VERSION "dbc-export 1 2026.26.6.5"

NS_ :

BS_:

BU_: ADSP APB APP APS APSB BB BMS CC CMP CMPD CP DAS DI DIF DIR DPB EPAS3P EPAS3S EPASTP EPASTS EPBL EPBR ESP EVSE FC GTW HCML HCMR HVP IBST ICR IDB LS OCS1P PARK PCS PCS2 PM PMF PMR PNCD PTC RADC RCM RCM2 RCM3 RCU SCCM SCM SCS SDCR TAS TCU TCU2 TPMS TRCM UI UIS UMC USM V2G VC VCBATT VCBATT0 VCBATT1 VCBATT2 VCCC VCFRONT VCFRONT1 VCFRONT2 VCLEFT VCRIGHT VCSEAT2L VCSEAT2R VCSEC VEH

BO_ 1513 APP_alertLog: 8 APP
 SG_ APP_alertID M : 0|14@1+ (1,0) [0|16383] "" Vector__XXX
 SG_ APP_sw285_exitTransportMode m285 : 24|1@1+ (1,0) [0|1] "" Vector__XXX
 SG_ APP_sw285_satRejectionTimeout m285 : 25|1@1+ (1,0) [0|1] "" Vector__XXX
 SG_ APP_sw285_gpsPPSMissing m285 : 26|1@1+ (1,0) [0|1] "" Vector__XXX
 SG_ APP_sw286_cfgBufNull m286 : 16|1@1+ (1,0) [0|1] "" Vector__XXX
 SG_ APP_sw286_invalidID m286 : 17|1@1+ (1,0) [0|1] "" Vector__XXX
 SG_ APP_sw286_gpsBufferOverflow m286 : 18|1@1+ (1,0) [0|1] "" Vector__XXX
 SG_ APP_sw286_navx5CfgFailed m286 : 19|1@1+ (1,0) [0|1] "" Vector__XXX
 SG_ APP_sw286_mcuNMEAmsgUDPinvalid m286 : 20|1@1+ (1,0) [0|1] "" Vector__XXX
 SG_ APP_sw286_mcuDbgMsgInvalid m286 : 21|1@1+ (1,0) [0|1] "" Vector__XXX
 SG_ APP_sw286_mcuDbgMsgTooBig m286 : 22|1@1+ (1,0) [0|1] "" Vector__XXX
 SG_ APP_sw286_mcuFwdNMEAfail m286 : 23|1@1+ (1,0) [0|1] "" Vector__XXX
 SG_ APP_sw286_NMEAinvalidChecksum m286 : 24|1@1+ (1,0) [0|1] "" Vector__XXX
 SG_ APP_sw286_unexpectedNMEAmsg m286 : 25|1@1+ (1,0) [0|1] "" Vector__XXX
 SG_ APP_sw286_UARTbusFull m286 : 26|1@1+ (1,0) [0|1] "" Vector__XXX
 SG_ APP_sw286_UARTframeError m286 : 27|1@1+ (1,0) [0|1] "" Vector__XXX
 SG_ APP_sw286_UBXrxFrameTooBig m286 : 28|1@1+ (1,0) [0|1] "" Vector__XXX
 SG_ APP_sw286_emptyValidNMEA m286 : 29|1@1+ (1,0) [0|1] "" Vector__XXX
 SG_ APP_sw286_invalidAsciiNMEA m286 : 30|1@1+ (1,0) [0|1] "" Vector__XXX
 SG_ APP_sw286_wheeltickUARTfault m286 : 31|1@1+ (1,0) [0|1] "" Vector__XXX
 SG_ APP_sw286_baudrateMismatch m286 : 32|1@1+ (1,0) [0|1] "" Vector__XXX
 SG_ APP_sw286_wheelTickInvalidSrc m286 : 33|1@1+ (1,0) [0|1] "" Vector__XXX
 SG_ APP_sw286_UARTparityError m286 : 34|1@1+ (1,0) [0|1] "" Vector__XXX
 SG_ APP_sw286_UARTrxFifoOverflow m286 : 35|1@1+ (1,0) [0|1] "" Vector__XXX
 SG_ APP_sw286_UARTrxFifoUnderflow m286 : 36|1@1+ (1,0) [0|1] "" Vector__XXX
 SG_ APP_sw286_UARTtxFifoOverflow m286 : 37|1@1+ (1,0) [0|1] "" Vector__XXX
 SG_ APP_sw286_esfWtMsgTimeout m286 : 38|1@1+ (1,0) [0|1] "" Vector__XXX
 SG_ APP_sw286_PFLASHReadError m286 : 39|1@1+ (1,0) [0|1] "" Vector__XXX
 SG_ APP_sw286_PFLASHWriteError m286 : 40|1@1+ (1,0) [0|1] "" Vector__XXX
 SG_ APP_sw286_gpsCfgNack m286 : 41|1@1+ (1,0) [0|1] "" Vector__XXX
 SG_ APP_sw286_gpsCfgIdFail m286 : 42|6@1+ (1,0) [0|63] "" Vector__XXX
 SG_ APP_sw286_gpsSetCfgNoAck m286 : 48|1@1+ (1,0) [0|1] "" Vector__XXX
 SG_ APP_sw286_gpsReadCfgNoResponse m286 : 49|1@1+ (1,0) [0|1] "" Vector__XXX
 SG_ APP_sw286_ubxErrorReported m286 : 50|1@1+ (1,0) [0|1] "" Vector__XXX
 SG_ APP_sw288_dist_to_stop m288 : 16|8@1+ (0.5,0) [0|127.5] "" Vector__XXX
 SG_ APP_sw288_ego_speed m288 : 24|8@1+ (0.2,0) [0|51] "" Vector__XXX
 SG_ APP_sw288_ego_acceleration m288 : 32|8@1+ (0.1,-15.5) [-15.5|10] "" Vector__XXX
 SG_ APP_sw291_dist_to_stop m291 : 16|8@1+ (0.5,0) [0|127.5] "" Vector__XXX
 SG_ APP_sw291_ego_speed m291 : 24|8@1+ (0.2,0) [0|51] "" Vector__XXX
 SG_ APP_sw291_ego_acceleration m291 : 32|8@1+ (0.1,-15.5) [-15.5|10] "" Vector__XXX
 SG_ APP_sw293_clockFrequencyDrift m293 : 16|16@1- (0.0005,0) [-16.384|16.3835] "" Vector__XXX
 SG_ APP_sw294_clockFrequencyDrift m294 : 16|16@1- (0.0005,0) [-16.384|16.3835] "" Vector__XXX
 SG_ APP_sw295_clockFrequencyDrift m295 : 16|16@1- (0.0005,0) [-16.384|16.3835] "" Vector__XXX
 SG_ APP_sw296_clockFrequencyDrift m296 : 16|16@1- (0.0005,0) [-16.384|16.3835] "" Vector__XXX
 SG_ APP_sw297_clockFrequencyDrift m297 : 16|16@1- (0.0005,0) [-16.384|16.3835] "" Vector__XXX
 SG_ APP_sw298_clockFrequencyDrift m298 : 16|16@1- (0.0005,0) [-16.384|16.3835] "" Vector__XXX
 SG_ APP_sw299_clockFrequencyDrift m299 : 16|16@1- (0.0005,0) [-16.384|16.3835] "" Vector__XXX
 SG_ APP_sw300_clockFrequencyDrift m300 : 16|16@1- (0.0005,0) [-16.384|16.3835] "" Vector__XXX
 SG_ APP_sw301_clockFrequencyDrift m301 : 16|16@1- (0.0005,0) [-16.384|16.3835] "" Vector__XXX
 SG_ APP_sw302_AP_vehicleState10Hz m302 : 16|1@1+ (1,0) [0|1] "" Vector__XXX
 SG_ APP_sw302_cameraCleaningStatus m302 : 17|1@1+ (1,0) [0|1] "" Vector__XXX
 SG_ APP_sw304_lssLPillarBlocked m304 : 16|1@1+ (1,0) [0|1] "" Vector__XXX
 SG_ APP_sw304_lssRPillarBlocked m304 : 17|1@1+ (1,0) [0|1] "" Vector__XXX
 SG_ APP_sw304_lssLRepeaterBlocked m304 : 18|1@1+ (1,0) [0|1] "" Vector__XXX
 SG_ APP_sw304_lssRRepeaterBlocked m304 : 19|1@1+ (1,0) [0|1] "" Vector__XXX
 SG_ APP_sw304_lssMainBlocked m304 : 20|1@1+ (1,0) [0|1] "" Vector__XXX
 SG_ APP_sw305_lssLPillarStreamExit m305 : 16|1@1+ (1,0) [0|1] "" Vector__XXX
 SG_ APP_sw305_lssRPillarStreamExit m305 : 17|1@1+ (1,0) [0|1] "" Vector__XXX
 SG_ APP_sw305_lssLRepeaterStreamExit m305 : 18|1@1+ (1,0) [0|1] "" Vector__XXX
 SG_ APP_sw305_lssRRepeaterStreamExit m305 : 19|1@1+ (1,0) [0|1] "" Vector__XXX
 SG_ APP_sw306_lssUssS1Blocked m306 : 16|1@1+ (1,0) [0|1] "" Vector__XXX
 SG_ APP_sw306_lssUssS2Blocked m306 : 17|1@1+ (1,0) [0|1] "" Vector__XXX
 SG_ APP_sw306_lssUssS3Blocked m306 : 18|1@1+ (1,0) [0|1] "" Vector__XXX
 SG_ APP_sw306_lssUssS4Blocked m306 : 19|1@1+ (1,0) [0|1] "" Vector__XXX
 SG_ APP_sw306_lssUssS5Blocked m306 : 20|1@1+ (1,0) [0|1] "" Vector__XXX
 SG_ APP_sw306_lssUssS6Blocked m306 : 21|1@1+ (1,0) [0|1] "" Vector__XXX
 SG_ APP_sw306_lssUssS7Blocked m306 : 22|1@1+ (1,0) [0|1] "" Vector__XXX
 SG_ APP_sw306_lssUssS8Blocked m306 : 23|1@1+ (1,0) [0|1] "" Vector__XXX
 SG_ APP_sw306_lssUssS9Blocked m306 : 24|1@1+ (1,0) [0|1] "" Vector__XXX
 SG_ APP_sw306_lssUssS10Blocked m306 : 25|1@1+ (1,0) [0|1] "" Vector__XXX
 SG_ APP_sw306_lssUssS11Blocked m306 : 26|1@1+ (1,0) [0|1] "" Vector__XXX
 SG_ APP_sw306_lssUssS12Blocked m306 : 27|1@1+ (1,0) [0|1] "" Vector__XXX
 SG_ APP_sw307_lssTurnSignalFLFault m307 : 16|1@1+ (1,0) [0|1] "" Vector__XXX
 SG_ APP_sw307_lssTurnSignalFRFault m307 : 17|1@1+ (1,0) [0|1] "" Vector__XXX
 SG_ APP_sw307_lssTurnSignalRLFault m307 : 18|1@1+ (1,0) [0|1] "" Vector__XXX
 SG_ APP_sw307_lssTurnSignalRRFault m307 : 19|1@1+ (1,0) [0|1] "" Vector__XXX
 SG_ APP_sw308_IBST_status m308 : 16|1@1+ (1,0) [0|1] "" Vector__XXX
 SG_ APP_sw321_energyStatus m321 : 16|1@1+ (1,0) [0|1] "" Vector__XXX
 SG_ APP_sw321_status m321 : 17|1@1+ (1,0) [0|1] "" Vector__XXX
 SG_ APP_sw321_autonomyHealth m321 : 18|1@1+ (1,0) [0|1] "" Vector__XXX
 SG_ APP_sw322_sunGlare m322 : 16|1@1+ (1,0) [0|1] "" Vector__XXX
 SG_ APP_sw322_blinded m322 : 17|1@1+ (1,0) [0|1] "" Vector__XXX
 SG_ APP_sw322_falseWipe m322 : 18|1@1+ (1,0) [0|1] "" Vector__XXX
 SG_ APP_sw323_confidence m323 : 16|8@1+ (0.004,0) [0|1.02] "" Vector__XXX
 SG_ APP_sw323_distance m323 : 24|8@1+ (0.5,0) [0|127.5] "" Vector__XXX
 SG_ APP_sw323_ttc m323 : 32|8@1+ (0.02,0) [0|5.1] "" Vector__XXX
 SG_ APP_sw324_state m324 : 16|1@1+ (1,0) [0|1] "" Vector__XXX
 SG_ APP_sw325_taskId m325 : 16|8@1+ (1,0) [0|255] "" Vector__XXX
 SG_ APP_sw325_issue m325 : 24|6@1+ (1,0) [0|63] "" Vector__XXX
 SG_ APP_sw327_driveHandSideMismatch m327 : 16|1@1+ (1,0) [0|1] "" Vector__XXX
 SG_ APP_sw327_hardwareTypeMismatch m327 : 17|1@1+ (1,0) [0|1] "" Vector__XXX
 SG_ APP_sw327_turboTypeMismatch m327 : 18|1@1+ (1,0) [0|1] "" Vector__XXX
 SG_ APP_sw327_epasTypeMismatch m327 : 19|1@1+ (1,0) [0|1] "" Vector__XXX
 SG_ APP_sw327_radarTypeMismatch m327 : 20|1@1+ (1,0) [0|1] "" Vector__XXX
 SG_ APP_sw327_chassisTypeMismatch m327 : 21|1@1+ (1,0) [0|1] "" Vector__XXX
 SG_ APP_sw327_displayTypeMismatch m327 : 22|1@1+ (1,0) [0|1] "" Vector__XXX
 SG_ APP_sw327_cameraTypeMismatch m327 : 23|1@1+ (1,0) [0|1] "" Vector__XXX
 SG_ APP_sw327_parkAssistTypeMismatch m327 : 24|1@1+ (1,0) [0|1] "" Vector__XXX
 SG_ APP_sw327_selfieCamTypeMismatch m327 : 25|1@1+ (1,0) [0|1] "" Vector__XXX
 SG_ APP_sw328_ussS1Unavailable m328 : 16|1@1+ (1,0) [0|1] "" Vector__XXX
 SG_ APP_sw328_ussS2Unavailable m328 : 17|1@1+ (1,0) [0|1] "" Vector__XXX
 SG_ APP_sw328_ussS3Unavailable m328 : 18|1@1+ (1,0) [0|1] "" Vector__XXX
 SG_ APP_sw328_ussS4Unavailable m328 : 19|1@1+ (1,0) [0|1] "" Vector__XXX
 SG_ APP_sw328_ussS5Unavailable m328 : 20|1@1+ (1,0) [0|1] "" Vector__XXX
 SG_ APP_sw328_ussS6Unavailable m328 : 21|1@1+ (1,0) [0|1] "" Vector__XXX
 SG_ APP_sw328_ussS7Unavailable m328 : 22|1@1+ (1,0) [0|1] "" Vector__XXX
 SG_ APP_sw328_ussS8Unavailable m328 : 23|1@1+ (1,0) [0|1] "" Vector__XXX
 SG_ APP_sw328_ussS9Unavailable m328 : 24|1@1+ (1,0) [0|1] "" Vector__XXX
 SG_ APP_sw328_ussS10Unavailable m328 : 25|1@1+ (1,0) [0|1] "" Vector__XXX
 SG_ APP_sw328_ussS11Unavailable m328 : 26|1@1+ (1,0) [0|1] "" Vector__XXX
 SG_ APP_sw328_ussS12Unavailable m328 : 27|1@1+ (1,0) [0|1] "" Vector__XXX
 SG_ APP_sw328_fisheyeStreamExit m328 : 28|1@1+ (1,0) [0|1] "" Vector__XXX
 SG_ APP_sw328_lPillarStreamExit m328 : 29|1@1+ (1,0) [0|1] "" Vector__XXX
 SG_ APP_sw328_rPillarStreamExit m328 : 30|1@1+ (1,0) [0|1] "" Vector__XXX
 SG_ APP_sw328_lRepeaterStreamExit m328 : 31|1@1+ (1,0) [0|1] "" Vector__XXX
 SG_ APP_sw328_rRepeaterStreamExit m328 : 32|1@1+ (1,0) [0|1] "" Vector__XXX
 SG_ APP_sw328_backupStreamExit m328 : 33|1@1+ (1,0) [0|1] "" Vector__XXX
 SG_ APP_sw328_fisheyeCal m328 : 34|1@1+ (1,0) [0|1] "" Vector__XXX
 SG_ APP_sw328_lPillarCal m328 : 35|1@1+ (1,0) [0|1] "" Vector__XXX
 SG_ APP_sw328_rPillarCal m328 : 36|1@1+ (1,0) [0|1] "" Vector__XXX
 SG_ APP_sw328_lRepeaterCal m328 : 37|1@1+ (1,0) [0|1] "" Vector__XXX
 SG_ APP_sw328_rRepeaterCal m328 : 38|1@1+ (1,0) [0|1] "" Vector__XXX
 SG_ APP_sw328_backupCal m328 : 39|1@1+ (1,0) [0|1] "" Vector__XXX
 SG_ APP_sw328_epasMia m328 : 40|1@1+ (1,0) [0|1] "" Vector__XXX
 SG_ APP_sw328_espMia m328 : 41|1@1+ (1,0) [0|1] "" Vector__XXX
 SG_ APP_sw328_parkMia m328 : 42|1@1+ (1,0) [0|1] "" Vector__XXX
 SG_ APP_sw328_sccmMia m328 : 43|1@1+ (1,0) [0|1] "" Vector__XXX
 SG_ APP_sw328_scMia m328 : 44|1@1+ (1,0) [0|1] "" Vector__XXX
 SG_ APP_sw328_ussOLONotEnabled m328 : 45|1@1+ (1,0) [0|1] "" Vector__XXX
 SG_ APP_sw328_ussPASNotEnabled m328 : 46|1@1+ (1,0) [0|1] "" Vector__XXX
 SG_ APP_sw328_ussOOCNotEnabled m328 : 47|1@1+ (1,0) [0|1] "" Vector__XXX
 SG_ APP_sw328_ussTemporaryFault m328 : 48|1@1+ (1,0) [0|1] "" Vector__XXX
 SG_ APP_sw328_ussSystemError m328 : 49|1@1+ (1,0) [0|1] "" Vector__XXX
 SG_ APP_sw328_ussFault m328 : 50|1@1+ (1,0) [0|1] "" Vector__XXX
 SG_ APP_sw328_ussStatusOutOfDate m328 : 51|1@1+ (1,0) [0|1] "" Vector__XXX
 SG_ APP_sw328_perceptionUnhealthy m328 : 52|1@1+ (1,0) [0|1] "" Vector__XXX
 SG_ APP_sw328_drivableSpaceUnhealthy m328 : 53|1@1+ (1,0) [0|1] "" Vector__XXX
 SG_ APP_sw328_uiDisplayNotOk m328 : 54|1@1+ (1,0) [0|1] "" Vector__XXX
 SG_ APP_sw328_externalLightsOff m328 : 55|1@1+ (1,0) [0|1] "" Vector__XXX
 SG_ APP_sw328_forwardCamerasBlinded m328 : 56|1@1+ (1,0) [0|1] "" Vector__XXX
 SG_ APP_sw328_backupCameraBlinded m328 : 57|1@1+ (1,0) [0|1] "" Vector__XXX
 SG_ APP_sw328_extComputeNotActive m328 : 58|1@1+ (1,0) [0|1] "" Vector__XXX
 SG_ APP_sw329_cipvSysReqAccel m329 : 16|7@1+ (0.15625,-10) [-10|9.84375] "" Vector__XXX
 SG_ APP_sw329_leftLaneReqAccel m329 : 24|7@1+ (0.15625,-10) [-10|9.84375] "" Vector__XXX
 SG_ APP_sw329_rightLaneReqAccel m329 : 32|7@1+ (0.15625,-10) [-10|9.84375] "" Vector__XXX
 SG_ APP_sw329_leftLaneAvailable m329 : 39|1@1+ (1,0) [0|1] "" Vector__XXX
 SG_ APP_sw329_rightLaneAvailable m329 : 40|1@1+ (1,0) [0|1] "" Vector__XXX
 SG_ APP_sw329_laneChangeLeft m329 : 41|1@1+ (1,0) [0|1] "" Vector__XXX
 SG_ APP_sw329_laneChangeRight m329 : 42|1@1+ (1,0) [0|1] "" Vector__XXX
 SG_ APP_sw329_leftLaneChngBehStatus m329 : 43|5@1+ (1,0) [0|31] "" Vector__XXX
 SG_ APP_sw329_rightLaneChngBehStatus m329 : 48|5@1+ (1,0) [0|31] "" Vector__XXX
 SG_ APP_sw330_initFailure m330 : 16|1@1+ (1,0) [0|1] "" Vector__XXX
 SG_ APP_sw330_streamExit m330 : 17|1@1+ (1,0) [0|1] "" Vector__XXX
 SG_ APP_sw330_ledFault m330 : 18|1@1+ (1,0) [0|1] "" Vector__XXX
 SG_ APP_sw331_lPillarOccluded m331 : 16|1@1+ (1,0) [0|1] "" Vector__XXX
 SG_ APP_sw331_rPillarOccluded m331 : 17|1@1+ (1,0) [0|1] "" Vector__XXX
 SG_ APP_sw331_lRepeaterOccluded m331 : 18|1@1+ (1,0) [0|1] "" Vector__XXX
 SG_ APP_sw331_rRepeaterOccluded m331 : 19|1@1+ (1,0) [0|1] "" Vector__XXX
 SG_ APP_sw331_gpsDegraded m331 : 20|1@1+ (1,0) [0|1] "" Vector__XXX
 SG_ APP_sw331_poorWeather m331 : 21|1@1+ (1,0) [0|1] "" Vector__XXX
 SG_ APP_sw331_invalidMap m331 : 22|1@1+ (1,0) [0|1] "" Vector__XXX
 SG_ APP_sw331_adverseRoadConditions m331 : 23|1@1+ (1,0) [0|1] "" Vector__XXX
 SG_ APP_sw332_narrowWithFisheye m332 : 16|1@1+ (1,0) [0|1] "" Vector__XXX
 SG_ APP_sw332_pillars m332 : 17|1@1+ (1,0) [0|1] "" Vector__XXX
 SG_ APP_sw348_main m348 : 16|1@1+ (1,0) [0|1] "" Vector__XXX
 SG_ APP_sw348_narrow m348 : 17|1@1+ (1,0) [0|1] "" Vector__XXX
 SG_ APP_sw348_fisheye m348 : 18|1@1+ (1,0) [0|1] "" Vector__XXX
 SG_ APP_sw348_leftPillar m348 : 19|1@1+ (1,0) [0|1] "" Vector__XXX
 SG_ APP_sw348_rightPillar m348 : 20|1@1+ (1,0) [0|1] "" Vector__XXX
 SG_ APP_sw348_leftRepeater m348 : 21|1@1+ (1,0) [0|1] "" Vector__XXX
 SG_ APP_sw348_rightRepeater m348 : 22|1@1+ (1,0) [0|1] "" Vector__XXX
 SG_ APP_sw348_backup m348 : 23|1@1+ (1,0) [0|1] "" Vector__XXX
 SG_ APP_sw348_selfie m348 : 24|1@1+ (1,0) [0|1] "" Vector__XXX
 SG_ APP_sw348_fascia m348 : 25|1@1+ (1,0) [0|1] "" Vector__XXX
 SG_ APP_sw351_errorCode m351 : 16|32@1+ (1,0) [0|4294967295] "" Vector__XXX
 SG_ APP_sw352_errorCode m352 : 16|32@1+ (1,0) [0|4294967295] "" Vector__XXX
 SG_ APP_sw353_errorCode m353 : 16|32@1+ (1,0) [0|4294967295] "" Vector__XXX
 SG_ APP_sw355_quad1 m355 : 16|1@1+ (1,0) [0|1] "" Vector__XXX
 SG_ APP_sw355_quad2 m355 : 17|1@1+ (1,0) [0|1] "" Vector__XXX
 SG_ APP_sw355_quad3 m355 : 18|1@1+ (1,0) [0|1] "" Vector__XXX
 SG_ APP_sw355_quad1FailureRate m355 : 24|8@1+ (0.392156869173,0) [0|100.000001639] "" Vector__XXX
 SG_ APP_sw355_quad2FailureRate m355 : 32|8@1+ (0.392156869173,0) [0|100.000001639] "" Vector__XXX
 SG_ APP_sw355_quad3FailureRate m355 : 40|8@1+ (0.392156869173,0) [0|100.000001639] "" Vector__XXX
 SG_ APP_sw357_cabinCameraFailsafeAct m357 : 16|1@1+ (1,0) [0|1] "" Vector__XXX
 SG_ APP_sw357_cameraDisabled m357 : 17|1@1+ (1,0) [0|1] "" Vector__XXX
 SG_ APP_sw357_cameraNotStreaming m357 : 18|1@1+ (1,0) [0|1] "" Vector__XXX
 SG_ APP_sw357_disableByBuildCfg m357 : 19|1@1+ (1,0) [0|1] "" Vector__XXX
 SG_ APP_sw357_invalidCameraFailsafe m357 : 20|1@1+ (1,0) [0|1] "" Vector__XXX
 SG_ APP_sw357_invalidDrowsinessPredi m357 : 21|1@1+ (1,0) [0|1] "" Vector__XXX
 SG_ APP_sw357_invalidSccmSteeringAng m357 : 22|1@1+ (1,0) [0|1] "" Vector__XXX
 SG_ APP_sw357_invalidSccmSteeri_0001 m357 : 23|1@1+ (1,0) [0|1] "" Vector__XXX
 SG_ APP_sw357_noVisionOutput m357 : 24|1@1+ (1,0) [0|1] "" Vector__XXX
 SG_ APP_sw357_poorFrontCameraVisibil m357 : 25|1@1+ (1,0) [0|1] "" Vector__XXX
 SG_ APP_sw357_staleVisionDv m357 : 26|1@1+ (1,0) [0|1] "" Vector__XXX
 SG_ APP_sw357_staleVisionOutput m357 : 27|1@1+ (1,0) [0|1] "" Vector__XXX
 SG_ APP_sw357_sccmMia m357 : 28|1@1+ (1,0) [0|1] "" Vector__XXX
 SG_ APP_sw357_electricalFaultForSccm m357 : 29|1@1+ (1,0) [0|1] "" Vector__XXX
 SG_ APP_sw357_electricalFaultForMain m357 : 30|1@1+ (1,0) [0|1] "" Vector__XXX
 SG_ APP_sw357_electricalFaultForCabi m357 : 31|1@1+ (1,0) [0|1] "" Vector__XXX
 SG_ APP_sw357_mainCameraFailsafeActi m357 : 32|1@1+ (1,0) [0|1] "" Vector__XXX
 SG_ APP_sw357_electricalFaultForFish m357 : 33|1@1+ (1,0) [0|1] "" Vector__XXX
 SG_ APP_sw357_fisheyeCameraFailsafeA m357 : 34|1@1+ (1,0) [0|1] "" Vector__XXX
 SG_ APP_sw357_camCalibOutOfBounds m357 : 35|1@1+ (1,0) [0|1] "" Vector__XXX
 SG_ APP_sw358_noSpeedLimitSource m358 : 16|1@1+ (1,0) [0|1] "" Vector__XXX
 SG_ APP_sw358_mainCameraBlinded m358 : 17|1@1+ (1,0) [0|1] "" Vector__XXX
 SG_ APP_sw358_fisheyeCameraBlinded m358 : 18|1@1+ (1,0) [0|1] "" Vector__XXX
 SG_ APP_sw358_mainCameraStreamUnavai m358 : 19|1@1+ (1,0) [0|1] "" Vector__XXX
 SG_ APP_sw358_fisheyeCameraStreamUna m358 : 20|1@1+ (1,0) [0|1] "" Vector__XXX
 SG_ APP_sw358_camCalibOutOfBounds m358 : 21|1@1+ (1,0) [0|1] "" Vector__XXX
 SG_ APP_sw359_mainCameraBlinded m359 : 16|1@1+ (1,0) [0|1] "" Vector__XXX
 SG_ APP_sw359_narrowCameraBlinded m359 : 17|1@1+ (1,0) [0|1] "" Vector__XXX
 SG_ APP_sw359_fisheyeCameraBlinded m359 : 18|1@1+ (1,0) [0|1] "" Vector__XXX
 SG_ APP_sw362_fasciaCamDeserFault m362 : 16|3@1+ (1,0) [0|7] "" Vector__XXX
 SG_ APP_sw362_fasciaCamI2CbusFault m362 : 19|1@1+ (1,0) [0|1] "" Vector__XXX
 SG_ APP_sw362_fasciaCamSensorFault m362 : 20|3@1+ (1,0) [0|7] "" Vector__XXX
 SG_ APP_sw362_fasciaCamSerFault m362 : 24|3@1+ (1,0) [0|7] "" Vector__XXX
 SG_ APP_sw363_exitStatus m363 : 16|1@1+ (1,0) [0|1] "" Vector__XXX
 SG_ APP_sw363_bufferError m363 : 17|1@1+ (1,0) [0|1] "" Vector__XXX
 SG_ APP_sw363_frameGrabFailure m363 : 18|1@1+ (1,0) [0|1] "" Vector__XXX
 SG_ APP_sw363_gainControlFailure m363 : 19|1@1+ (1,0) [0|1] "" Vector__XXX
 SG_ APP_sw363_tempMonitorFailure m363 : 20|2@1+ (1,0) [0|3] "" Vector__XXX
 SG_ APP_sw363_firstFrameGrabFailure m363 : 22|1@1+ (1,0) [0|1] "" Vector__XXX
 SG_ APP_sw363_deserParityError m363 : 23|1@1+ (1,0) [0|1] "" Vector__XXX
 SG_ APP_sw363_deserLockError m363 : 24|1@1+ (1,0) [0|1] "" Vector__XXX
 SG_ APP_sw363_deserCrcError m363 : 25|1@1+ (1,0) [0|1] "" Vector__XXX
 SG_ APP_sw363_imagerHeartbeat m363 : 26|2@1+ (1,0) [0|3] "" Vector__XXX
 SG_ APP_sw363_serializerCrcErrCount m363 : 28|8@1+ (1,0) [0|255] "" Vector__XXX
 SG_ APP_sw363_deserLineLengthError m363 : 36|1@1+ (1,0) [0|1] "" Vector__XXX
 SG_ APP_sw363_numCaptureRecoveries m363 : 37|3@1+ (1,0) [0|7] "" Vector__XXX
 SG_ APP_sw363_currentTemperature m363 : 40|8@1+ (1,-60) [-60|195] "" Vector__XXX
 SG_ APP_sw363_minTemperature m363 : 48|8@1+ (1,-60) [-60|195] "" Vector__XXX
 SG_ APP_sw363_maxTemperature m363 : 56|8@1+ (1,-60) [-60|195] "" Vector__XXX
 SG_ APP_sw364_colorFilterMismatch m364 : 16|1@1+ (1,0) [0|1] "" Vector__XXX
 SG_ APP_sw364_detectedColorFilter m364 : 17|2@1+ (1,0) [0|3] "" Vector__XXX
 SG_ APP_sw364_expectedColorFilter m364 : 19|2@1+ (1,0) [0|3] "" Vector__XXX
 SG_ APP_sw364_cameraPositionMismatch m364 : 21|1@1+ (1,0) [0|1] "" Vector__XXX
 SG_ APP_sw364_blacklistedFuseID m364 : 22|1@1+ (1,0) [0|1] "" Vector__XXX
 SG_ APP_sw364_uuidMismatch m364 : 23|1@1+ (1,0) [0|1] "" Vector__XXX
 SG_ APP_sw364_detectedPosition m364 : 24|4@1+ (1,0) [0|15] "" Vector__XXX
 SG_ APP_sw365_fasciaCamExtNoCalFile m365 : 16|1@1+ (1,0) [0|1] "" Vector__XXX
 SG_ APP_sw366_clockFrequencyDrift m366 : 16|16@1- (0.0005,0) [-16.384|16.3835] "" Vector__XXX
 SG_ APP_sw371_decryptionFailed m371 : 16|1@1+ (1,0) [0|1] "" Vector__XXX
 SG_ APP_sw389_frontCamResidue m389 : 16|1@1+ (1,0) [0|1] "" Vector__XXX
 SG_ APP_sw389_leftPillarCamResidue m389 : 17|1@1+ (1,0) [0|1] "" Vector__XXX
 SG_ APP_sw389_rightPillarCamResidue m389 : 18|1@1+ (1,0) [0|1] "" Vector__XXX
 SG_ APP_sw397_apImuNoise m397 : 16|1@1+ (1,0) [0|1] "" Vector__XXX
 SG_ APP_sw399_status m399 : 16|1@1+ (1,0) [0|1] "" Vector__XXX
 SG_ APP_sw404_status m404 : 16|1@1+ (1,0) [0|1] "" Vector__XXX
 SG_ APP_sw404_autonomyHealth m404 : 17|1@1+ (1,0) [0|1] "" Vector__XXX
 SG_ APP_sw407_unknown m407 : 16|1@1+ (1,0) [0|1] "" Vector__XXX
 SG_ APP_sw407_neutralGear m407 : 17|1@1+ (1,0) [0|1] "" Vector__XXX
 SG_ APP_sw407_noAutonomyModeActive m407 : 18|1@1+ (1,0) [0|1] "" Vector__XXX
 SG_ APP_sw407_delivered m407 : 19|1@1+ (1,0) [0|1] "" Vector__XXX
 SG_ APP_sw407_fsdDisabled m407 : 20|1@1+ (1,0) [0|1] "" Vector__XXX
 SG_ APP_sw407_outsideGeofence m407 : 21|1@1+ (1,0) [0|1] "" Vector__XXX
 SG_ APP_sw407_driverlessGtwConfigOff m407 : 22|1@1+ (1,0) [0|1] "" Vector__XXX
 SG_ APP_sw407_sentryActive m407 : 23|1@1+ (1,0) [0|1] "" Vector__XXX
 SG_ APP_sw407_apPowerRequestNotNomin m407 : 24|1@1+ (1,0) [0|1] "" Vector__XXX
 SG_ APP_sw407_gnssDegradedSignalStre m407 : 25|1@1+ (1,0) [0|1] "" Vector__XXX
 SG_ APP_sw407_cameraCalibration m407 : 26|1@1+ (1,0) [0|1] "" Vector__XXX
 SG_ APP_sw407_factoryCalibration m407 : 27|1@1+ (1,0) [0|1] "" Vector__XXX
 SG_ APP_sw407_frontCamerasStreamLost m407 : 28|1@1+ (1,0) [0|1] "" Vector__XXX
 SG_ APP_sw407_leftCamerasStreamLost m407 : 29|1@1+ (1,0) [0|1] "" Vector__XXX
 SG_ APP_sw407_rightCamerasStreamLost m407 : 30|1@1+ (1,0) [0|1] "" Vector__XXX
 SG_ APP_sw407_backupCameraStreamLost m407 : 31|1@1+ (1,0) [0|1] "" Vector__XXX
 SG_ APP_sw407_outOfSyncCameraStreams m407 : 32|1@1+ (1,0) [0|1] "" Vector__XXX
 SG_ APP_sw407_cameraAutoexposureLost m407 : 33|1@1+ (1,0) [0|1] "" Vector__XXX
 SG_ APP_sw407_cameraNightOffgassing m407 : 34|1@1+ (1,0) [0|1] "" Vector__XXX
 SG_ APP_sw407_cameraVisionFailsafeBe m407 : 35|1@1+ (1,0) [0|1] "" Vector__XXX
 SG_ APP_sw407_severeFrontVisionOcclu m407 : 36|1@1+ (1,0) [0|1] "" Vector__XXX
 SG_ APP_sw407_severeLeftVisionOcclus m407 : 37|1@1+ (1,0) [0|1] "" Vector__XXX
 SG_ APP_sw407_severeRightVisionOcclu m407 : 38|1@1+ (1,0) [0|1] "" Vector__XXX
 SG_ APP_sw407_severeReverseVisionOcc m407 : 39|1@1+ (1,0) [0|1] "" Vector__XXX
 SG_ APP_sw407_frequentVisionOcclusio m407 : 40|1@1+ (1,0) [0|1] "" Vector__XXX
 SG_ APP_sw407_fasciaVisionOcclusionA m407 : 41|1@1+ (1,0) [0|1] "" Vector__XXX
 SG_ APP_sw407_safetyDriverUnbuckled m407 : 42|1@1+ (1,0) [0|1] "" Vector__XXX
 SG_ APP_sw407_visionFpsLow m407 : 43|1@1+ (1,0) [0|1] "" Vector__XXX
 SG_ APP_sw407_driverDoorOpen m407 : 44|1@1+ (1,0) [0|1] "" Vector__XXX
 SG_ APP_sw407_passengerDoorOpen m407 : 45|1@1+ (1,0) [0|1] "" Vector__XXX
 SG_ APP_sw407_trunkOpen m407 : 46|1@1+ (1,0) [0|1] "" Vector__XXX
 SG_ APP_sw407_frunkOpen m407 : 47|1@1+ (1,0) [0|1] "" Vector__XXX
 SG_ APP_sw407_notPowerStateDrive m407 : 48|1@1+ (1,0) [0|1] "" Vector__XXX
 SG_ APP_sw407_cruiseUnavailable m407 : 49|1@1+ (1,0) [0|1] "" Vector__XXX
 SG_ APP_sw407_cruiseNotActive m407 : 50|1@1+ (1,0) [0|1] "" Vector__XXX
 SG_ APP_sw407_cruiseFault m407 : 51|1@1+ (1,0) [0|1] "" Vector__XXX
 SG_ APP_sw407_epasEacUnavailable m407 : 52|1@1+ (1,0) [0|1] "" Vector__XXX
 SG_ APP_sw407_epasEacNotActive m407 : 53|1@1+ (1,0) [0|1] "" Vector__XXX
 SG_ APP_sw407_epasDriverlessModeNotA m407 : 54|1@1+ (1,0) [0|1] "" Vector__XXX
 SG_ APP_sw407_epasRedundancyLost m407 : 55|1@1+ (1,0) [0|1] "" Vector__XXX
 SG_ APP_sw407_epasSystemTorqueReduce m407 : 56|1@1+ (1,0) [0|1] "" Vector__XXX
 SG_ APP_sw407_navGoalInvalid m407 : 57|1@1+ (1,0) [0|1] "" Vector__XXX
 SG_ APP_sw407_noFixedRoute m407 : 58|1@1+ (1,0) [0|1] "" Vector__XXX
 SG_ APP_sw407_notInParkNoTakeover m407 : 59|1@1+ (1,0) [0|1] "" Vector__XXX
 SG_ APP_sw407_extendedComputeInactiv m407 : 60|1@1+ (1,0) [0|1] "" Vector__XXX
 SG_ APP_sw407_epbRedundantBrakingSta m407 : 61|1@1+ (1,0) [0|1] "" Vector__XXX
 SG_ APP_sw407_cruiseStackMismatch m407 : 62|1@1+ (1,0) [0|1] "" Vector__XXX
 SG_ APP_sw407_vehicleAutonomyBehavio m407 : 63|1@1+ (1,0) [0|1] "" Vector__XXX
 SG_ APP_sw408_lvDegradedState m408 : 16|1@1+ (1,0) [0|1] "" Vector__XXX
 SG_ APP_sw408_lvCriticalState m408 : 17|1@1+ (1,0) [0|1] "" Vector__XXX
 SG_ APP_sw408_controllerSolverFailur m408 : 18|1@1+ (1,0) [0|1] "" Vector__XXX
 SG_ APP_sw408_controllerSolverDegrad m408 : 19|1@1+ (1,0) [0|1] "" Vector__XXX
 SG_ APP_sw408_controllerSolverCritic m408 : 20|1@1+ (1,0) [0|1] "" Vector__XXX
 SG_ APP_sw408_driverNotPresent m408 : 21|1@1+ (1,0) [0|1] "" Vector__XXX
 SG_ APP_sw408_driverMonitorStrikeout m408 : 22|1@1+ (1,0) [0|1] "" Vector__XXX
 SG_ APP_sw408_passengerExpected m408 : 23|1@1+ (1,0) [0|1] "" Vector__XXX
 SG_ APP_sw408_rideshareIngressNoNavR m408 : 24|1@1+ (1,0) [0|1] "" Vector__XXX
 SG_ APP_sw408_cabinCamBlinded m408 : 25|1@1+ (1,0) [0|1] "" Vector__XXX
 SG_ APP_sw408_incompatibleSystemHeal m408 : 26|1@1+ (1,0) [0|1] "" Vector__XXX
 SG_ APP_sw408_stateMachineDisabled m408 : 27|1@1+ (1,0) [0|1] "" Vector__XXX
 SG_ APP_sw408_imuReplicationNotReady m408 : 28|1@1+ (1,0) [0|1] "" Vector__XXX
 SG_ APP_sw408_singleSocHealthyExcept m408 : 29|1@1+ (1,0) [0|1] "" Vector__XXX
 SG_ APP_sw408_systemUnhealthyDevOver m408 : 30|1@1+ (1,0) [0|1] "" Vector__XXX
 SG_ APP_sw408_passengerUnbuckled m408 : 31|1@1+ (1,0) [0|1] "" Vector__XXX
 SG_ APP_sw408_passengerUnbuckledActi m408 : 32|1@1+ (1,0) [0|1] "" Vector__XXX
 SG_ APP_sw408_chargeCableConnectedOr m408 : 33|1@1+ (1,0) [0|1] "" Vector__XXX
 SG_ APP_sw408_fleetMaintenanceRequir m408 : 34|1@1+ (1,0) [0|1] "" Vector__XXX
 SG_ APP_sw408_sgkPlannerActiveDRN m408 : 35|1@1+ (1,0) [0|1] "" Vector__XXX
 SG_ APP_sw408_visionCabinOccupancyUn m408 : 36|1@1+ (1,0) [0|1] "" Vector__XXX
 SG_ APP_sw408_lowTirePressureReading m408 : 37|1@1+ (1,0) [0|1] "" Vector__XXX
 SG_ APP_sw408_elevatedTirePressureRe m408 : 38|1@1+ (1,0) [0|1] "" Vector__XXX
 SG_ APP_sw408_washerFluidLow m408 : 39|1@1+ (1,0) [0|1] "" Vector__XXX
 SG_ APP_sw408_imuDataNotReliable m408 : 40|1@1+ (1,0) [0|1] "" Vector__XXX
 SG_ APP_sw408_flatTire m408 : 41|1@1+ (1,0) [0|1] "" Vector__XXX
 SG_ APP_sw408_tirePressureHardWarnin m408 : 42|1@1+ (1,0) [0|1] "" Vector__XXX
 SG_ APP_sw408_epbParkingAvailability m408 : 43|1@1+ (1,0) [0|1] "" Vector__XXX
 SG_ APP_sw408_epbParkingAvailab_0002 m408 : 44|1@1+ (1,0) [0|1] "" Vector__XXX
 SG_ APP_sw408_epbParkingAvailab_0001 m408 : 45|1@1+ (1,0) [0|1] "" Vector__XXX
 SG_ APP_sw408_epbParkingAvailab_0003 m408 : 46|1@1+ (1,0) [0|1] "" Vector__XXX
 SG_ APP_sw408_epbStatusNotParked m408 : 47|1@1+ (1,0) [0|1] "" Vector__XXX
 SG_ APP_sw408_diLosingPropulsion m408 : 48|1@1+ (1,0) [0|1] "" Vector__XXX
 SG_ APP_sw408_diVdcStateNotNormal m408 : 49|1@1+ (1,0) [0|1] "" Vector__XXX
 SG_ APP_sw408_diBrakingDecelerationU m408 : 50|1@1+ (1,0) [0|1] "" Vector__XXX
 SG_ APP_sw408_apRedundancyUnavailabl m408 : 51|1@1+ (1,0) [0|1] "" Vector__XXX
 SG_ APP_sw408_headlightsNotAimed m408 : 52|1@1+ (1,0) [0|1] "" Vector__XXX
 SG_ APP_sw408_lowBeamLightFaulted m408 : 53|1@1+ (1,0) [0|1] "" Vector__XXX
 SG_ APP_sw408_highBeamLightFaulted m408 : 54|1@1+ (1,0) [0|1] "" Vector__XXX
 SG_ APP_sw408_lowBeamLightFaultedInL m408 : 55|1@1+ (1,0) [0|1] "" Vector__XXX
 SG_ APP_sw408_highBeamLightFaultedIn m408 : 56|1@1+ (1,0) [0|1] "" Vector__XXX
 SG_ APP_sw408_brakeLightFaulted m408 : 57|1@1+ (1,0) [0|1] "" Vector__XXX
 SG_ APP_sw408_allBrakeLightsFaulted m408 : 58|1@1+ (1,0) [0|1] "" Vector__XXX
 SG_ APP_sw408_leftTurnLightFaulted m408 : 59|1@1+ (1,0) [0|1] "" Vector__XXX
 SG_ APP_sw408_rightTurnLightFaulted m408 : 60|1@1+ (1,0) [0|1] "" Vector__XXX
 SG_ APP_sw408_reverseLightFaulted m408 : 61|1@1+ (1,0) [0|1] "" Vector__XXX
 SG_ APP_sw408_tailLightFaulted m408 : 62|1@1+ (1,0) [0|1] "" Vector__XXX
 SG_ APP_sw408_allTailLightsFaultedIn m408 : 63|1@1+ (1,0) [0|1] "" Vector__XXX
 SG_ APP_sw409_windshieldCamHeaterFau m409 : 16|1@1+ (1,0) [0|1] "" Vector__XXX
 SG_ APP_sw409_leftPillarCamHeaterFau m409 : 17|1@1+ (1,0) [0|1] "" Vector__XXX
 SG_ APP_sw409_rightPillarCamHeaterFa m409 : 18|1@1+ (1,0) [0|1] "" Vector__XXX
 SG_ APP_sw409_wiperNotHealthy m409 : 19|1@1+ (1,0) [0|1] "" Vector__XXX
 SG_ APP_sw409_brakePedalPressed m409 : 20|1@1+ (1,0) [0|1] "" Vector__XXX
 SG_ APP_sw409_rankerNotHealthy m409 : 21|1@1+ (1,0) [0|1] "" Vector__XXX
 SG_ APP_sw409_redundantBrakePathActi m409 : 22|1@1+ (1,0) [0|1] "" Vector__XXX
 SG_ APP_sw409_redundantBrakesNotRead m409 : 23|1@1+ (1,0) [0|1] "" Vector__XXX
 SG_ APP_sw409_redundantBrakesNotArme m409 : 24|1@1+ (1,0) [0|1] "" Vector__XXX
 SG_ APP_sw409_redundantBrakesRedunda m409 : 25|1@1+ (1,0) [0|1] "" Vector__XXX
 SG_ APP_sw409_redundantBrakesFailOpe m409 : 26|1@1+ (1,0) [0|1] "" Vector__XXX
 SG_ APP_sw409_rcmWarningIndicatorOn m409 : 27|1@1+ (1,0) [0|1] "" Vector__XXX
 SG_ APP_sw409_seatbeltStatusUnhealth m409 : 28|1@1+ (1,0) [0|1] "" Vector__XXX
 SG_ APP_sw409_teleopStreamsUnhealthy m409 : 29|1@1+ (1,0) [0|1] "" Vector__XXX
 SG_ APP_sw409_seatOccupancyStatusUnh m409 : 30|1@1+ (1,0) [0|1] "" Vector__XXX
 SG_ APP_sw409_visionFailoverActive m409 : 31|1@1+ (1,0) [0|1] "" Vector__XXX
 SG_ APP_sw409_poorLocalizationAccura m409 : 32|1@1+ (1,0) [0|1] "" Vector__XXX
 SG_ APP_sw409_apsCanMessagesMia m409 : 33|1@1+ (1,0) [0|1] "" Vector__XXX
 SG_ APP_sw409_diChassisControlCanMes m409 : 34|1@1+ (1,0) [0|1] "" Vector__XXX
 SG_ APP_sw409_diSystemStatusCanMessa m409 : 35|1@1+ (1,0) [0|1] "" Vector__XXX
 SG_ APP_sw409_steeringCanMessagesMia m409 : 36|1@1+ (1,0) [0|1] "" Vector__XXX
 SG_ APP_sw409_parkBrakeCanMessagesMi m409 : 37|1@1+ (1,0) [0|1] "" Vector__XXX
 SG_ APP_sw409_brakingCanMessagesMia m409 : 38|1@1+ (1,0) [0|1] "" Vector__XXX
 SG_ APP_sw409_imuCanMessagesMia m409 : 39|1@1+ (1,0) [0|1] "" Vector__XXX
 SG_ APP_sw409_narrowWashNotAvailable m409 : 40|1@1+ (1,0) [0|1] "" Vector__XXX
 SG_ APP_sw409_driverNotPresentPreAct m409 : 41|1@1+ (1,0) [0|1] "" Vector__XXX
 SG_ APP_sw409_passengerUnexpectedRid m409 : 42|1@1+ (1,0) [0|1] "" Vector__XXX
 SG_ APP_sw409_waitingForPassengerEgr m409 : 43|1@1+ (1,0) [0|1] "" Vector__XXX
 SG_ APP_sw409_unassignedPassengerUnb m409 : 44|1@1+ (1,0) [0|1] "" Vector__XXX
 SG_ APP_sw409_notAuthenticatedForDri m409 : 45|1@1+ (1,0) [0|1] "" Vector__XXX
 SG_ APP_sw409_coolantSystemNotReady m409 : 46|1@1+ (1,0) [0|1] "" Vector__XXX
 SG_ APP_sw409_defogSystemNotReady m409 : 47|1@1+ (1,0) [0|1] "" Vector__XXX
 SG_ APP_sw409_coolantSystemUnhealthy m409 : 48|1@1+ (1,0) [0|1] "" Vector__XXX
 SG_ APP_sw409_defogSystemUnhealthy m409 : 49|1@1+ (1,0) [0|1] "" Vector__XXX
 SG_ APP_sw409_diSpeedCanMessageMia m409 : 50|1@1+ (1,0) [0|1] "" Vector__XXX
 SG_ APP_sw409_cameraRedundancyNotRea m409 : 51|1@1+ (1,0) [0|1] "" Vector__XXX
 SG_ APP_sw409_audioBusDown m409 : 52|1@1+ (1,0) [0|1] "" Vector__XXX
 SG_ APP_sw409_autonomousBehaviorsTas m409 : 53|1@1+ (1,0) [0|1] "" Vector__XXX
 SG_ APP_sw409_hvDriveNoRestart m409 : 54|1@1+ (1,0) [0|1] "" Vector__XXX
 SG_ APP_sw409_vehicleLosingHv m409 : 55|1@1+ (1,0) [0|1] "" Vector__XXX
 SG_ APP_sw409_bmsCanMessagesMia m409 : 56|1@1+ (1,0) [0|1] "" Vector__XXX
 SG_ APP_sw409_cameraPreconditioningI m409 : 57|1@1+ (1,0) [0|1] "" Vector__XXX
 SG_ APP_sw409_safetyOperatorNotPrese m409 : 58|1@1+ (1,0) [0|1] "" Vector__XXX
 SG_ APP_sw409_unsupervisedRtNotAllow m409 : 59|1@1+ (1,0) [0|1] "" Vector__XXX
 SG_ APP_sw409_driverPresentNotAllowe m409 : 60|1@1+ (1,0) [0|1] "" Vector__XXX
 SG_ APP_sw409_apThermalDegradedBlock m409 : 61|1@1+ (1,0) [0|1] "" Vector__XXX
 SG_ APP_sw409_apThermalDegradedPullo m409 : 62|1@1+ (1,0) [0|1] "" Vector__XXX
 SG_ APP_sw409_autonomousBehaviorsLin m409 : 63|1@1+ (1,0) [0|1] "" Vector__XXX
 SG_ APP_sw410_noValidSgkStatus m410 : 16|1@1+ (1,0) [0|1] "" Vector__XXX
 SG_ APP_sw410_autonomyControllingAnd m410 : 17|1@1+ (1,0) [0|1] "" Vector__XXX
 SG_ APP_sw410_cameraDayOffgassing m410 : 18|1@1+ (1,0) [0|1] "" Vector__XXX
 SG_ APP_sw410_missionPlannerDesiredB m410 : 19|1@1+ (1,0) [0|1] "" Vector__XXX
 SG_ APP_sw410_arbiterSelectedBehavio m410 : 20|1@1+ (1,0) [0|1] "" Vector__XXX
 SG_ APP_sw410_arbiterSelectedBe_0001 m410 : 21|1@1+ (1,0) [0|1] "" Vector__XXX
 SG_ APP_sw410_peerVisionFailoverActi m410 : 22|1@1+ (1,0) [0|1] "" Vector__XXX
 SG_ APP_sw410_apsAUnhealthy m410 : 23|1@1+ (1,0) [0|1] "" Vector__XXX
 SG_ APP_sw410_apsBUnhealthy m410 : 24|1@1+ (1,0) [0|1] "" Vector__XXX
 SG_ APP_sw410_apsSelfCanFaulted m410 : 25|1@1+ (1,0) [0|1] "" Vector__XXX
 SG_ APP_sw410_apsPeerCanFaulted m410 : 26|1@1+ (1,0) [0|1] "" Vector__XXX
 SG_ APP_sw410_apsSelfImemFaulted m410 : 27|1@1+ (1,0) [0|1] "" Vector__XXX
 SG_ APP_sw410_apsPeerImemFaulted m410 : 28|1@1+ (1,0) [0|1] "" Vector__XXX
 SG_ APP_sw410_apsSelfVrmFaulted m410 : 29|1@1+ (1,0) [0|1] "" Vector__XXX
 SG_ APP_sw410_apsPeerVrmFaulted m410 : 30|1@1+ (1,0) [0|1] "" Vector__XXX
 SG_ APP_sw410_apsSelfPmicFaulted m410 : 31|1@1+ (1,0) [0|1] "" Vector__XXX
 SG_ APP_sw410_apsPeerPmicFaulted m410 : 32|1@1+ (1,0) [0|1] "" Vector__XXX
 SG_ APP_sw410_apsSingleCameraPowerFa m410 : 33|1@1+ (1,0) [0|1] "" Vector__XXX
 SG_ APP_sw410_apsDualCameraPowerFail m410 : 34|1@1+ (1,0) [0|1] "" Vector__XXX
 SG_ APP_sw410_apTaskPendingReboot m410 : 35|1@1+ (1,0) [0|1] "" Vector__XXX
 SG_ APP_sw410_anyLvHealthCanMessageM m410 : 36|1@1+ (1,0) [0|1] "" Vector__XXX
 SG_ APP_sw410_anyLvHealthCanMessageI m410 : 37|1@1+ (1,0) [0|1] "" Vector__XXX
 SG_ APP_sw410_uiHealthStatusCanMessa m410 : 38|1@1+ (1,0) [0|1] "" Vector__XXX
 SG_ APP_sw410_gtwCarConfigCanMessage m410 : 39|1@1+ (1,0) [0|1] "" Vector__XXX
 SG_ APP_sw410_bbStatusCanMessageMia m410 : 40|1@1+ (1,0) [0|1] "" Vector__XXX
 SG_ APP_sw410_vcleftDoorStatusCanMes m410 : 41|1@1+ (1,0) [0|1] "" Vector__XXX
 SG_ APP_sw410_vcrightDoorStatusCanMe m410 : 42|1@1+ (1,0) [0|1] "" Vector__XXX
 SG_ APP_sw410_anyLeftDoorOpenButtonF m410 : 43|1@1+ (1,0) [0|1] "" Vector__XXX
 SG_ APP_sw410_anyRightDoorOpenButton m410 : 44|1@1+ (1,0) [0|1] "" Vector__XXX
 SG_ APP_sw410_sgkAutonomyStateNotInS m410 : 45|1@1+ (1,0) [0|1] "" Vector__XXX
 SG_ APP_sw410_apThermalModelFaultDet m410 : 46|1@1+ (1,0) [0|1] "" Vector__XXX
 SG_ APP_sw410_wheelSpeedsCanMessageM m410 : 47|1@1+ (1,0) [0|1] "" Vector__XXX
 SG_ APP_sw410_allWheelSpeedsSensorsF m410 : 48|1@1+ (1,0) [0|1] "" Vector__XXX
 SG_ APP_sw410_diAutonomyHealthCanMes m410 : 49|1@1+ (1,0) [0|1] "" Vector__XXX
 SG_ APP_sw410_devPulloverOverrideAct m410 : 50|1@1+ (1,0) [0|1] "" Vector__XXX
 SG_ APP_sw410_imuRedundancyLost m410 : 51|1@1+ (1,0) [0|1] "" Vector__XXX
 SG_ APP_sw410_noImuSourcesAvailable m410 : 52|1@1+ (1,0) [0|1] "" Vector__XXX
 SG_ APP_sw410_tamperingDetected m410 : 53|1@1+ (1,0) [0|1] "" Vector__XXX
 SG_ APP_sw410_cabinCameraIrLedFaulte m410 : 54|1@1+ (1,0) [0|1] "" Vector__XXX
 SG_ APP_sw410_cameraExposureMismatch m410 : 55|1@1+ (1,0) [0|1] "" Vector__XXX
 SG_ APP_sw410_ssdClipLoggingInactive m410 : 56|1@1+ (1,0) [0|1] "" Vector__XXX
 SG_ APP_sw410_selfNetworkDecryptionN m410 : 57|1@1+ (1,0) [0|1] "" Vector__XXX
 SG_ APP_sw410_uiCenterDisplayUnavail m410 : 58|1@1+ (1,0) [0|1] "" Vector__XXX
 SG_ APP_sw410_uiConnectivityOffline m410 : 59|1@1+ (1,0) [0|1] "" Vector__XXX
 SG_ APP_sw410_uiConnectivityHwUnheal m410 : 60|1@1+ (1,0) [0|1] "" Vector__XXX
 SG_ APP_sw410_uiQtCarUnavailable m410 : 61|1@1+ (1,0) [0|1] "" Vector__XXX
 SG_ APP_sw410_gnssUartFaulted m410 : 62|1@1+ (1,0) [0|1] "" Vector__XXX
 SG_ APP_sw410_gnssAntennaFaulted m410 : 63|1@1+ (1,0) [0|1] "" Vector__XXX
 SG_ APP_sw413_apSystemIssuePendingRe m413 : 16|1@1+ (1,0) [0|1] "" Vector__XXX
 SG_ APP_sw413_diVelocityEstimatorSta m413 : 17|1@1+ (1,0) [0|1] "" Vector__XXX
 SG_ APP_sw413_noVehicleSpeedSourceAv m413 : 18|1@1+ (1,0) [0|1] "" Vector__XXX
 SG_ APP_sw413_secondaryWasherFluidLo m413 : 19|1@1+ (1,0) [0|1] "" Vector__XXX
 SG_ APP_sw413_leftRepeaterAirCleanDe m413 : 20|1@1+ (1,0) [0|1] "" Vector__XXX
 SG_ APP_sw413_rightRepeaterAirCleanD m413 : 21|1@1+ (1,0) [0|1] "" Vector__XXX
 SG_ APP_sw413_backupAirCleanDegraded m413 : 22|1@1+ (1,0) [0|1] "" Vector__XXX
 SG_ APP_sw413_fasciaAirCleanDegraded m413 : 23|1@1+ (1,0) [0|1] "" Vector__XXX
 SG_ APP_sw413_leftRepeaterFluid_0001 m413 : 24|1@1+ (1,0) [0|1] "" Vector__XXX
 SG_ APP_sw413_rightRepeaterFlui_0001 m413 : 25|1@1+ (1,0) [0|1] "" Vector__XXX
 SG_ APP_sw413_backupFluidCleanDegrad m413 : 26|1@1+ (1,0) [0|1] "" Vector__XXX
 SG_ APP_sw413_fasciaFluidCleanDegrad m413 : 27|1@1+ (1,0) [0|1] "" Vector__XXX
 SG_ APP_sw413_leftRepeaterAirCleanCr m413 : 28|1@1+ (1,0) [0|1] "" Vector__XXX
 SG_ APP_sw413_rightRepeaterAirCleanC m413 : 29|1@1+ (1,0) [0|1] "" Vector__XXX
 SG_ APP_sw413_backupAirCleanCritical m413 : 30|1@1+ (1,0) [0|1] "" Vector__XXX
 SG_ APP_sw413_fasciaAirCleanCritical m413 : 31|1@1+ (1,0) [0|1] "" Vector__XXX
 SG_ APP_sw413_leftRepeaterFluidClean m413 : 32|1@1+ (1,0) [0|1] "" Vector__XXX
 SG_ APP_sw413_rightRepeaterFluidClea m413 : 33|1@1+ (1,0) [0|1] "" Vector__XXX
 SG_ APP_sw413_backupFluidCleanCritic m413 : 34|1@1+ (1,0) [0|1] "" Vector__XXX
 SG_ APP_sw413_fasciaFluidCleanCritic m413 : 35|1@1+ (1,0) [0|1] "" Vector__XXX
 SG_ APP_sw413_cabinCamFanRpmFault m413 : 36|1@1+ (1,0) [0|1] "" Vector__XXX
 SG_ APP_sw413_gnssPpsMIA m413 : 37|1@1+ (1,0) [0|1] "" Vector__XXX
 SG_ APP_sw413_camDayOffgassingPreAle m413 : 38|1@1+ (1,0) [0|1] "" Vector__XXX
 SG_ APP_sw413_fluidCleaningStatusMia m413 : 39|1@1+ (1,0) [0|1] "" Vector__XXX
 SG_ APP_sw413_airCleaningStatusMia m413 : 40|1@1+ (1,0) [0|1] "" Vector__XXX
 SG_ APP_sw415_reason1 m415 : 16|9@1+ (1,0) [0|511] "" Vector__XXX
 SG_ APP_sw415_reason2 m415 : 25|9@1+ (1,0) [0|511] "" Vector__XXX
 SG_ APP_sw415_reason3 m415 : 34|9@1+ (1,0) [0|511] "" Vector__XXX
 SG_ APP_sw416_reason1 m416 : 16|9@1+ (1,0) [0|511] "" Vector__XXX
 SG_ APP_sw416_reason2 m416 : 25|9@1+ (1,0) [0|511] "" Vector__XXX
 SG_ APP_sw416_reason3 m416 : 34|9@1+ (1,0) [0|511] "" Vector__XXX
 SG_ APP_sw416_safeStateManeuver m416 : 43|2@1+ (1,0) [0|3] "" Vector__XXX
 SG_ APP_sw417_reason1 m417 : 16|9@1+ (1,0) [0|511] "" Vector__XXX
 SG_ APP_sw417_reason2 m417 : 25|9@1+ (1,0) [0|511] "" Vector__XXX
 SG_ APP_sw417_reason3 m417 : 34|9@1+ (1,0) [0|511] "" Vector__XXX
 SG_ APP_sw418_reason1 m418 : 16|9@1+ (1,0) [0|511] "" Vector__XXX
 SG_ APP_sw418_reason2 m418 : 25|9@1+ (1,0) [0|511] "" Vector__XXX
 SG_ APP_sw418_reason3 m418 : 34|9@1+ (1,0) [0|511] "" Vector__XXX
 SG_ APP_sw418_safeStateManeuver m418 : 43|2@1+ (1,0) [0|3] "" Vector__XXX
 SG_ APP_sw419_reason1 m419 : 16|9@1+ (1,0) [0|511] "" Vector__XXX
 SG_ APP_sw419_reason2 m419 : 25|9@1+ (1,0) [0|511] "" Vector__XXX
 SG_ APP_sw419_reason3 m419 : 34|9@1+ (1,0) [0|511] "" Vector__XXX
 SG_ APP_sw420_reason1 m420 : 16|9@1+ (1,0) [0|511] "" Vector__XXX
 SG_ APP_sw420_reason2 m420 : 25|9@1+ (1,0) [0|511] "" Vector__XXX
 SG_ APP_sw420_reason3 m420 : 34|9@1+ (1,0) [0|511] "" Vector__XXX
 SG_ APP_sw420_safeStateManeuver m420 : 43|2@1+ (1,0) [0|3] "" Vector__XXX
 SG_ APP_sw421_reason1 m421 : 16|9@1+ (1,0) [0|511] "" Vector__XXX
 SG_ APP_sw421_reason2 m421 : 25|9@1+ (1,0) [0|511] "" Vector__XXX
 SG_ APP_sw421_reason3 m421 : 34|9@1+ (1,0) [0|511] "" Vector__XXX
 SG_ APP_sw422_reason1 m422 : 16|9@1+ (1,0) [0|511] "" Vector__XXX
 SG_ APP_sw422_reason2 m422 : 25|9@1+ (1,0) [0|511] "" Vector__XXX
 SG_ APP_sw422_reason3 m422 : 34|9@1+ (1,0) [0|511] "" Vector__XXX
 SG_ APP_sw422_safeStateManeuver m422 : 43|2@1+ (1,0) [0|3] "" Vector__XXX
 SG_ APP_sw423_type m423 : 16|4@1+ (1,0) [0|15] "" Vector__XXX
 SG_ APP_sw424_type m424 : 16|4@1+ (1,0) [0|15] "" Vector__XXX
 SG_ APP_sw425_type m425 : 16|4@1+ (1,0) [0|15] "" Vector__XXX
 SG_ APP_sw426_type m426 : 16|4@1+ (1,0) [0|15] "" Vector__XXX
 SG_ APP_sw427_type m427 : 16|4@1+ (1,0) [0|15] "" Vector__XXX
 SG_ APP_sw428_type m428 : 16|4@1+ (1,0) [0|15] "" Vector__XXX
 SG_ APP_sw429_type m429 : 16|4@1+ (1,0) [0|15] "" Vector__XXX
 SG_ APP_sw433_currentCameraIsAeroRib m433 : 16|1@1+ (1,0) [0|1] "" Vector__XXX
 SG_ APP_sw433_currentCameraAeroRibIn m433 : 17|3@1+ (1,0) [0|7] "" Vector__XXX
 SG_ APP_sw433_previousCameraIsAeroRi m433 : 20|1@1+ (1,0) [0|1] "" Vector__XXX
 SG_ APP_sw433_previousCameraAeroRibI m433 : 21|3@1+ (1,0) [0|7] "" Vector__XXX
 SG_ APP_sw434_currentCameraIsAeroRib m434 : 16|1@1+ (1,0) [0|1] "" Vector__XXX
 SG_ APP_sw434_currentCameraAeroRibIn m434 : 17|3@1+ (1,0) [0|7] "" Vector__XXX
 SG_ APP_sw434_previousCameraIsAeroRi m434 : 20|1@1+ (1,0) [0|1] "" Vector__XXX
 SG_ APP_sw434_previousCameraAeroRibI m434 : 21|3@1+ (1,0) [0|7] "" Vector__XXX
 SG_ APP_sw443_configuredImagerModelN m443 : 16|4@1+ (1,0) [0|15] "" Vector__XXX
 SG_ APP_sw443_detectedImagerModelNum m443 : 20|4@1+ (1,0) [0|15] "" Vector__XXX
 SG_ APP_sw444_configuredImagerModelN m444 : 16|4@1+ (1,0) [0|15] "" Vector__XXX
 SG_ APP_sw444_detectedImagerModelNum m444 : 20|4@1+ (1,0) [0|15] "" Vector__XXX
 SG_ APP_sw445_configuredImagerModelN m445 : 16|4@1+ (1,0) [0|15] "" Vector__XXX
 SG_ APP_sw445_detectedImagerModelNum m445 : 20|4@1+ (1,0) [0|15] "" Vector__XXX
 SG_ APP_sw446_configuredImagerModelN m446 : 16|4@1+ (1,0) [0|15] "" Vector__XXX
 SG_ APP_sw446_detectedImagerModelNum m446 : 20|4@1+ (1,0) [0|15] "" Vector__XXX
 SG_ APP_sw447_configuredImagerModelN m447 : 16|4@1+ (1,0) [0|15] "" Vector__XXX
 SG_ APP_sw447_detectedImagerModelNum m447 : 20|4@1+ (1,0) [0|15] "" Vector__XXX
 SG_ APP_sw448_configuredImagerModelN m448 : 16|4@1+ (1,0) [0|15] "" Vector__XXX
 SG_ APP_sw448_detectedImagerModelNum m448 : 20|4@1+ (1,0) [0|15] "" Vector__XXX
 SG_ APP_sw449_configuredImagerModelN m449 : 16|4@1+ (1,0) [0|15] "" Vector__XXX
 SG_ APP_sw449_detectedImagerModelNum m449 : 20|4@1+ (1,0) [0|15] "" Vector__XXX
 SG_ APP_sw450_configuredImagerModelN m450 : 16|4@1+ (1,0) [0|15] "" Vector__XXX
 SG_ APP_sw450_detectedImagerModelNum m450 : 20|4@1+ (1,0) [0|15] "" Vector__XXX
 SG_ APP_sw451_configuredImagerModelN m451 : 16|4@1+ (1,0) [0|15] "" Vector__XXX
 SG_ APP_sw451_detectedImagerModelNum m451 : 20|4@1+ (1,0) [0|15] "" Vector__XXX
 SG_ APP_sw452_configuredImagerModelN m452 : 16|4@1+ (1,0) [0|15] "" Vector__XXX
 SG_ APP_sw452_detectedImagerModelNum m452 : 20|4@1+ (1,0) [0|15] "" Vector__XXX
 SG_ APP_sw454_reason1 m454 : 16|9@1+ (1,0) [0|511] "" Vector__XXX
 SG_ APP_sw455_reason1 m455 : 16|9@1+ (1,0) [0|511] "" Vector__XXX
 SG_ APP_sw456_reason1 m456 : 16|9@1+ (1,0) [0|511] "" Vector__XXX
 SG_ APP_sw456_reason2 m456 : 25|9@1+ (1,0) [0|511] "" Vector__XXX
 SG_ APP_sw456_reason3 m456 : 34|9@1+ (1,0) [0|511] "" Vector__XXX
 SG_ APP_sw457_reason1 m457 : 16|9@1+ (1,0) [0|511] "" Vector__XXX
 SG_ APP_sw457_reason2 m457 : 25|9@1+ (1,0) [0|511] "" Vector__XXX
 SG_ APP_sw457_reason3 m457 : 34|9@1+ (1,0) [0|511] "" Vector__XXX
 SG_ APP_sw457_safeStateManeuver m457 : 43|2@1+ (1,0) [0|3] "" Vector__XXX
 SG_ APP_sw458_fsdCollisionValue m458 : 16|7@1+ (1,0) [0|127] "" Vector__XXX
 SG_ APP_sw458_aebCollisionValue m458 : 24|7@1+ (1,0) [0|127] "" Vector__XXX
 SG_ APP_sw458_aebDurationAtAceOnset m458 : 32|7@1+ (0.05,0) [0|6.35] "" Vector__XXX
 SG_ APP_sw458_targetDistance m458 : 40|8@1+ (0.5,0) [0|127.5] "" Vector__XXX
 SG_ APP_sw458_targetRelativeSpeed m458 : 48|8@1+ (0.4,-51.2) [-51.2|50.8] "" Vector__XXX
 SG_ APP_sw458_egoVehicleSpeed m458 : 56|8@1+ (0.25,0) [0|63.75] "" Vector__XXX
 SG_ APP_sw459_status m459 : 16|1@1+ (1,0) [0|1] "" Vector__XXX
 SG_ APP_sw460_status m460 : 16|1@1+ (1,0) [0|1] "" Vector__XXX
 SG_ APP_sw461_rerouteRequest m461 : 16|2@1+ (1,0) [0|3] "" Vector__XXX
 SG_ APP_sw461_rerouteReason m461 : 18|9@1+ (1,0) [0|511] "" Vector__XXX
 SG_ APP_sw465_reason1 m465 : 16|9@1+ (1,0) [0|511] "" Vector__XXX
 SG_ APP_sw465_reason2 m465 : 25|9@1+ (1,0) [0|511] "" Vector__XXX
 SG_ APP_sw465_reason3 m465 : 34|9@1+ (1,0) [0|511] "" Vector__XXX
 SG_ APP_sw465_safeStateManeuver m465 : 43|2@1+ (1,0) [0|3] "" Vector__XXX

BO_ 1045 APP_backupDashCamStatus: 8 APP
 SG_ APP_backupDashCamFeedGood : 0|1@1+ (1,0) [0|1] "" Vector__XXX
 SG_ APP_backupDashCamFrameRate : 1|7@1+ (1,0) [0|127] "" Vector__XXX

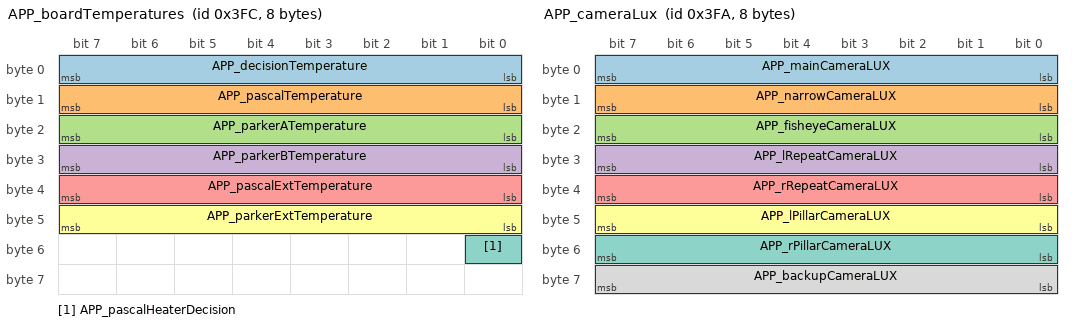
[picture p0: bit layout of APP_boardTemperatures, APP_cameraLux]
BO_ 1020 APP_boardTemperatures: 8 APP
 SG_ APP_decisionTemperature : 0|8@1+ (1,-128) [-128|127] "C" Vector__XXX
 SG_ APP_pascalTemperature : 8|8@1+ (1,-128) [-128|127] "C" Vector__XXX
 SG_ APP_parkerATemperature : 16|8@1+ (1,-128) [-128|127] "C" Vector__XXX
 SG_ APP_parkerBTemperature : 24|8@1+ (1,-128) [-128|127] "C" Vector__XXX
 SG_ APP_pascalExtTemperature : 32|8@1+ (1,-128) [-128|127] "C" Vector__XXX
 SG_ APP_parkerExtTemperature : 40|8@1+ (1,-128) [-128|127] "C" Vector__XXX
 SG_ APP_pascalHeaterDecision : 48|1@1+ (1,0) [0|1] "" Vector__XXX

BO_ 2046 APP_camCalibrationStatus: 8 APP
 SG_ APP_cameraPosition M : 0|4@1+ (1,0) [0|15] "" Vector__XXX
 SG_ APP_mainCamExtPitchCal m1 : 8|9@1+ (0.05,-12.5) [-12.5|12.5] "deg" Vector__XXX
 SG_ APP_mainCamExtYawCal m1 : 17|9@1+ (0.05,-12.5) [-12.5|12.5] "deg" Vector__XXX
 SG_ APP_mainCalibTime m1 : 26|7@1+ (1,0) [0|127] "min" Vector__XXX
 SG_ APP_mainCalibProgress m1 : 33|7@1+ (1,0) [0|100] "percent" Vector__XXX
 SG_ APP_mainCalibrated m1 : 40|1@1+ (1,0) [0|1] "" Vector__XXX
 SG_ APP_narrowCamExtPitchCal m2 : 8|9@1+ (0.05,-12.5) [-12.5|12.5] "deg" Vector__XXX
 SG_ APP_narrowCamExtYawCal m2 : 17|9@1+ (0.05,-12.5) [-12.5|12.5] "deg" Vector__XXX
 SG_ APP_narrowCalibTime m2 : 26|7@1+ (1,0) [0|127] "min" Vector__XXX
 SG_ APP_narrowCalibProgress m2 : 33|7@1+ (1,0) [0|100] "percent" Vector__XXX
 SG_ APP_narrowCalibrated m2 : 40|1@1+ (1,0) [0|1] "" Vector__XXX
 SG_ APP_fisheyeCamExtPitchCal m3 : 8|9@1+ (0.05,-12.5) [-12.5|12.5] "deg" Vector__XXX
 SG_ APP_fisheyeCamExtYawCal m3 : 17|9@1+ (0.05,-12.5) [-12.5|12.5] "deg" Vector__XXX
 SG_ APP_fisheyeCalibTime m3 : 26|7@1+ (1,0) [0|127] "min" Vector__XXX
 SG_ APP_fisheyeCalibProgress m3 : 33|7@1+ (1,0) [0|100] "percent" Vector__XXX
 SG_ APP_fisheyeCalibrated m3 : 40|1@1+ (1,0) [0|1] "" Vector__XXX
 SG_ APP_lPillarCamExtPitchCal m4 : 8|9@1+ (0.05,-12.5) [-12.5|12.5] "deg" Vector__XXX
 SG_ APP_lPillarCamExtYawCal m4 : 17|9@1+ (0.05,-12.5) [-12.5|12.5] "deg" Vector__XXX
 SG_ APP_lPillarCalibTime m4 : 26|7@1+ (1,0) [0|127] "min" Vector__XXX
 SG_ APP_lPillarCalibProgress m4 : 33|7@1+ (1,0) [0|100] "percent" Vector__XXX
 SG_ APP_lPillarCalibrated m4 : 40|1@1+ (1,0) [0|1] "" Vector__XXX
 SG_ APP_rPillarCamExtPitchCal m5 : 8|9@1+ (0.05,-12.5) [-12.5|12.5] "deg" Vector__XXX
 SG_ APP_rPillarCamExtYawCal m5 : 17|9@1+ (0.05,-12.5) [-12.5|12.5] "deg" Vector__XXX
 SG_ APP_rPillarCalibTime m5 : 26|7@1+ (1,0) [0|127] "min" Vector__XXX
 SG_ APP_rPillarCalibProgress m5 : 33|7@1+ (1,0) [0|100] "percent" Vector__XXX
 SG_ APP_rPillarCalibrated m5 : 40|1@1+ (1,0) [0|1] "" Vector__XXX
 SG_ APP_lRepeatCamExtPitchCal m6 : 8|9@1+ (0.05,-12.5) [-12.5|12.5] "deg" Vector__XXX
 SG_ APP_lRepeatCamExtYawCal m6 : 17|9@1+ (0.05,-12.5) [-12.5|12.5] "deg" Vector__XXX
 SG_ APP_lRepeatCalibTime m6 : 26|7@1+ (1,0) [0|127] "min" Vector__XXX
 SG_ APP_lRepeatCalibProgress m6 : 33|7@1+ (1,0) [0|100] "percent" Vector__XXX
 SG_ APP_lRepeatCalibrated m6 : 40|1@1+ (1,0) [0|1] "" Vector__XXX
 SG_ APP_rRepeatCamExtPitchCal m7 : 8|9@1+ (0.05,-12.5) [-12.5|12.5] "deg" Vector__XXX
 SG_ APP_rRepeatCamExtYawCal m7 : 17|9@1+ (0.05,-12.5) [-12.5|12.5] "deg" Vector__XXX
 SG_ APP_rRepeatCalibTime m7 : 26|7@1+ (1,0) [0|127] "min" Vector__XXX
 SG_ APP_rRepeatCalibProgress m7 : 33|7@1+ (1,0) [0|100] "percent" Vector__XXX
 SG_ APP_rRepeatCalibrated m7 : 40|1@1+ (1,0) [0|1] "" Vector__XXX
 SG_ APP_backupCamExtPitchCal m8 : 8|9@1+ (0.05,-12.5) [-12.5|12.5] "deg" Vector__XXX
 SG_ APP_backupCamExtYawCal m8 : 17|9@1+ (0.05,-12.5) [-12.5|12.5] "deg" Vector__XXX
 SG_ APP_backupCalibTime m8 : 26|7@1+ (1,0) [0|127] "min" Vector__XXX
 SG_ APP_backupCalibProgress m8 : 33|7@1+ (1,0) [0|100] "percent" Vector__XXX
 SG_ APP_backupCalibrated m8 : 40|1@1+ (1,0) [0|1] "" Vector__XXX
 SG_ APP_fasciaCamExtPitchCal m10 : 8|9@1+ (0.05,-12.5) [-12.5|12.5] "deg" Vector__XXX
 SG_ APP_fasciaCamExtYawCal m10 : 17|9@1+ (0.05,-12.5) [-12.5|12.5] "deg" Vector__XXX
 SG_ APP_fasciaCalibTime m10 : 26|7@1+ (1,0) [0|127] "min" Vector__XXX
 SG_ APP_fasciaCalibProgress m10 : 33|7@1+ (1,0) [0|100] "percent" Vector__XXX
 SG_ APP_fasciaCalibrated m10 : 40|1@1+ (1,0) [0|1] "" Vector__XXX

BO_ 1018 APP_cameraLux: 8 APP
 SG_ APP_mainCameraLUX : 0|8@1+ (0.5,0) [0|127] "lux^0.5" Vector__XXX
 SG_ APP_narrowCameraLUX : 8|8@1+ (0.5,0) [0|127] "lux^0.5" Vector__XXX
 SG_ APP_fisheyeCameraLUX : 16|8@1+ (0.5,0) [0|127] "lux^0.5" Vector__XXX
 SG_ APP_lRepeatCameraLUX : 24|8@1+ (0.5,0) [0|127] "lux^0.5" Vector__XXX
 SG_ APP_rRepeatCameraLUX : 32|8@1+ (0.5,0) [0|127] "lux^0.5" Vector__XXX
 SG_ APP_lPillarCameraLUX : 40|8@1+ (0.5,0) [0|127] "lux^0.5" Vector__XXX
 SG_ APP_rPillarCameraLUX : 48|8@1+ (0.5,0) [0|127] "lux^0.5" Vector__XXX
 SG_ APP_backupCameraLUX : 56|8@1+ (0.5,0) [0|127] "lux^0.5" Vector__XXX

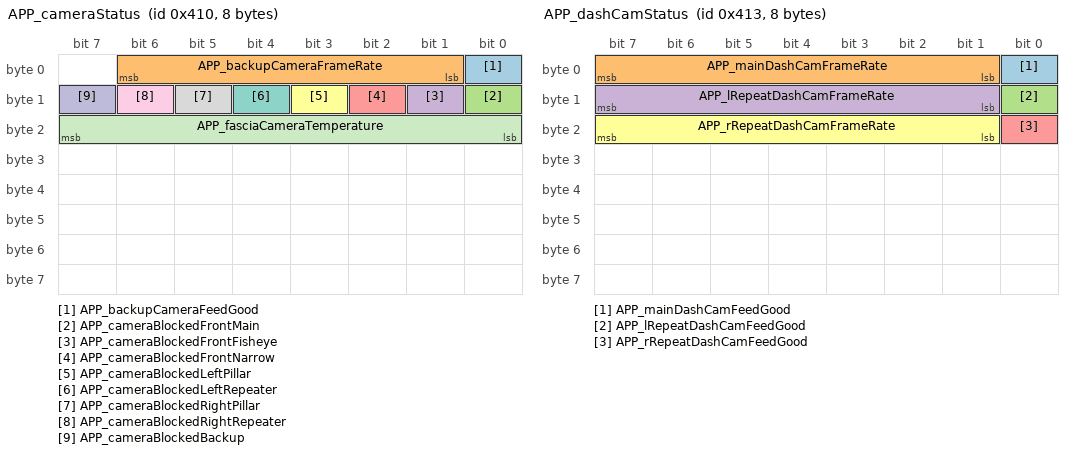
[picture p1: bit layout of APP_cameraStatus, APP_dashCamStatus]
BO_ 1040 APP_cameraStatus: 8 APP
 SG_ APP_backupCameraFeedGood : 0|1@1+ (1,0) [0|1] "" Vector__XXX
 SG_ APP_backupCameraFrameRate : 1|6@1+ (1,0) [0|63] "" Vector__XXX
 SG_ APP_cameraBlockedFrontMain : 8|1@1+ (1,0) [0|1] "" Vector__XXX
 SG_ APP_cameraBlockedFrontFisheye : 9|1@1+ (1,0) [0|1] "" Vector__XXX
 SG_ APP_cameraBlockedFrontNarrow : 10|1@1+ (1,0) [0|1] "" Vector__XXX
 SG_ APP_cameraBlockedLeftPillar : 11|1@1+ (1,0) [0|1] "" Vector__XXX
 SG_ APP_cameraBlockedLeftRepeater : 12|1@1+ (1,0) [0|1] "" Vector__XXX
 SG_ APP_cameraBlockedRightPillar : 13|1@1+ (1,0) [0|1] "" Vector__XXX
 SG_ APP_cameraBlockedRightRepeater : 14|1@1+ (1,0) [0|1] "" Vector__XXX
 SG_ APP_cameraBlockedBackup : 15|1@1+ (1,0) [0|1] "" Vector__XXX
 SG_ APP_fasciaCameraTemperature : 16|8@1+ (1,-60) [-60|195] "C" Vector__XXX

BO_ 1043 APP_dashCamStatus: 8 APP
 SG_ APP_mainDashCamFeedGood : 0|1@1+ (1,0) [0|1] "" Vector__XXX
 SG_ APP_mainDashCamFrameRate : 1|7@1+ (1,0) [0|127] "" Vector__XXX
 SG_ APP_lRepeatDashCamFeedGood : 8|1@1+ (1,0) [0|1] "" Vector__XXX
 SG_ APP_lRepeatDashCamFrameRate : 9|7@1+ (1,0) [0|127] "" Vector__XXX
 SG_ APP_rRepeatDashCamFeedGood : 16|1@1+ (1,0) [0|1] "" Vector__XXX
 SG_ APP_rRepeatDashCamFrameRate : 17|7@1+ (1,0) [0|127] "" Vector__XXX

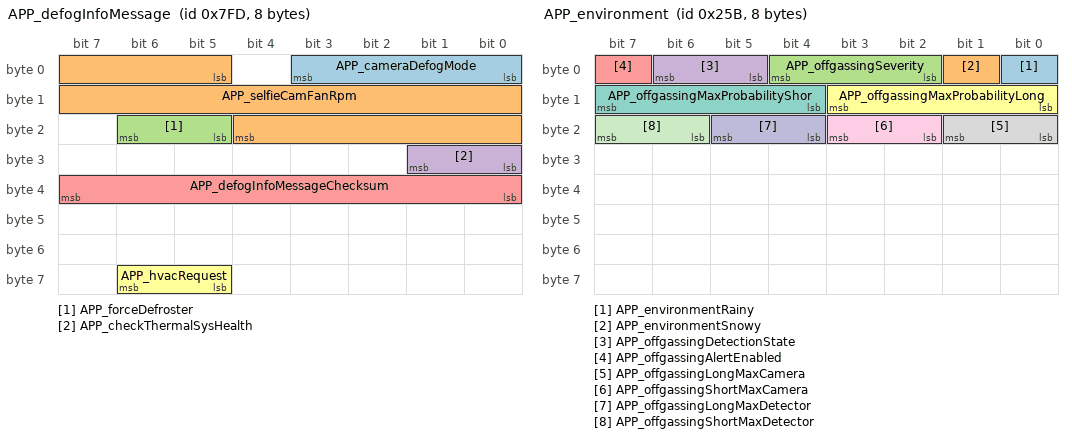
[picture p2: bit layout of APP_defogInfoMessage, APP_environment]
BO_ 2045 APP_defogInfoMessage: 8 APP
 SG_ APP_cameraDefogMode : 0|4@1+ (1,0) [0|15] "" Vector__XXX
 SG_ APP_selfieCamFanRpm : 5|16@1+ (1,0) [0|65535] "rpm" Vector__XXX
 SG_ APP_forceDefroster : 21|2@1+ (1,0) [0|3] "" Vector__XXX
 SG_ APP_checkThermalSysHealth : 24|2@1+ (1,0) [0|3] "" Vector__XXX
 SG_ APP_defogInfoMessageChecksum : 32|8@1+ (1,0) [0|255] "" Vector__XXX
 SG_ APP_hvacRequest : 61|2@1+ (1,0) [0|3] "" Vector__XXX

BO_ 939 APP_driverMonitorStatus: 8 APP
 SG_ APP_cabinCamTelemetryOn : 0|1@1+ (1,0) [0|1] "" Vector__XXX
 SG_ APP_attnMonitorVersion : 1|3@1+ (1,0) [0|7] "" Vector__XXX
 SG_ APP_attnBasedDriverMonitorOn : 4|1@1+ (1,0) [0|1] "" Vector__XXX
 SG_ APP_handsOnDetected : 5|1@1+ (1,0) [0|1] "" Vector__XXX
 SG_ APP_handsOnDetectedSource : 8|3@1+ (1,0) [0|7] "" Vector__XXX
 SG_ APP_cabinCamBlinded : 11|1@1+ (1,0) [0|1] "" Vector__XXX
 SG_ APP_cabinCamDark : 12|1@1+ (1,0) [0|1] "" Vector__XXX
 SG_ APP_driverStateUnknown : 13|1@1+ (1,0) [0|1] "" Vector__XXX
 SG_ APP_driverNotLively : 14|1@1+ (1,0) [0|1] "" Vector__XXX
 SG_ APP_driverStateUnknownHyst : 15|1@1+ (1,0) [0|1] "" Vector__XXX
 SG_ APP_driverLowNominal : 16|1@1+ (1,0) [0|1] "" Vector__XXX
 SG_ APP_driverHeadCappedHyst : 17|1@1+ (1,0) [0|1] "" Vector__XXX
 SG_ APP_driverSunglassesUseHyst : 18|1@1+ (1,0) [0|1] "" Vector__XXX
 SG_ APP_cabinLowLux : 19|1@1+ (1,0) [0|1] "" Vector__XXX
 SG_ APP_cabinCamInconsistent : 20|1@1+ (1,0) [0|1] "" Vector__XXX
 SG_ APP_driverLeaningBack : 21|1@1+ (1,0) [0|1] "" Vector__XXX
 SG_ APP_driverLowEyeVisibility : 22|1@1+ (1,0) [0|1] "" Vector__XXX
 SG_ APP_driverHandsNotReady : 23|1@1+ (1,0) [0|1] "" Vector__XXX
 SG_ APP_driverSeatUnoccupied : 24|1@1+ (1,0) [0|1] "" Vector__XXX
 SG_ APP_handsOnInputRequired : 25|1@1+ (1,0) [0|1] "" Vector__XXX
 SG_ APP_cabinCamDarkHyst : 26|1@1+ (1,0) [0|1] "" Vector__XXX
 SG_ APP_cabinLowLuxHyst : 27|1@1+ (1,0) [0|1] "" Vector__XXX
 SG_ APP_ADDWSystemStatus : 28|2@1+ (1,0) [0|3] "" Vector__XXX
 SG_ APP_dmStrictness : 30|2@1+ (1,0) [0|3] "" Vector__XXX
 SG_ APP_dmStrictnessReason : 32|6@1+ (1,0) [0|63] "" Vector__XXX

BO_ 603 APP_environment: 8 APP
 SG_ APP_environmentRainy : 0|1@1+ (1,0) [0|1] "" Vector__XXX
 SG_ APP_environmentSnowy : 1|1@1+ (1,0) [0|1] "" Vector__XXX
 SG_ APP_offgassingSeverity : 2|3@1+ (1,0) [0|7] "" Vector__XXX
 SG_ APP_offgassingDetectionState : 5|2@1+ (1,0) [0|3] "" Vector__XXX
 SG_ APP_offgassingAlertEnabled : 7|1@1+ (1,0) [0|1] "" Vector__XXX
 SG_ APP_offgassingMaxProbabilityLong : 8|4@1+ (1,0) [0|15] "" Vector__XXX
 SG_ APP_offgassingMaxProbabilityShor : 12|4@1+ (1,0) [0|15] "" Vector__XXX
 SG_ APP_offgassingLongMaxCamera : 16|2@1+ (1,0) [0|3] "" Vector__XXX
 SG_ APP_offgassingShortMaxCamera : 18|2@1+ (1,0) [0|3] "" Vector__XXX
 SG_ APP_offgassingLongMaxDetector : 20|2@1+ (1,0) [0|3] "" Vector__XXX
 SG_ APP_offgassingShortMaxDetector : 22|2@1+ (1,0) [0|3] "" Vector__XXX

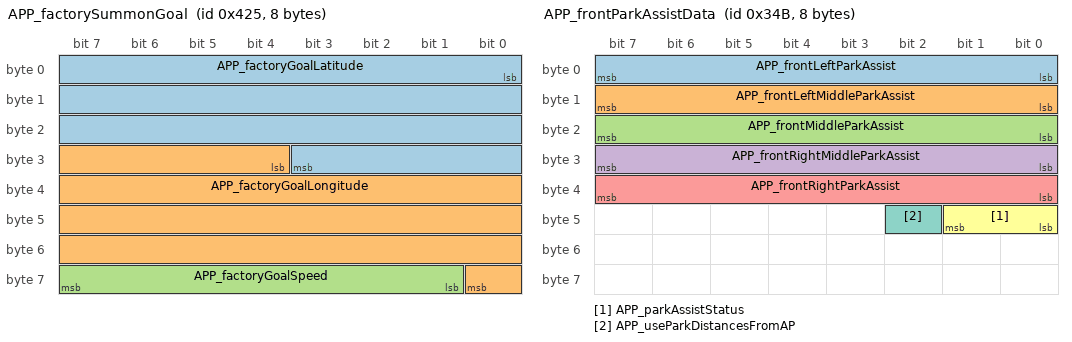
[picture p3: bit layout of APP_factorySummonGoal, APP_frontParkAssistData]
BO_ 1061 APP_factorySummonGoal: 8 APP
 SG_ APP_factoryGoalLatitude : 0|28@1- (1.0e-06,0) [-134.217728|134.217727] "deg" Vector__XXX
 SG_ APP_factoryGoalLongitude : 28|29@1- (1.0e-06,0) [-268.435456|268.435454] "deg" Vector__XXX
 SG_ APP_factoryGoalSpeed : 57|7@1+ (1,0) [0|100] "mph" Vector__XXX

BO_ 843 APP_frontParkAssistData: 8 APP
 SG_ APP_frontLeftParkAssist : 0|8@1+ (1,0) [0|255] "cm" Vector__XXX
 SG_ APP_frontLeftMiddleParkAssist : 8|8@1+ (1,0) [0|255] "cm" Vector__XXX
 SG_ APP_frontMiddleParkAssist : 16|8@1+ (1,0) [0|255] "cm" Vector__XXX
 SG_ APP_frontRightMiddleParkAssist : 24|8@1+ (1,0) [0|255] "cm" Vector__XXX
 SG_ APP_frontRightParkAssist : 32|8@1+ (1,0) [0|255] "cm" Vector__XXX
 SG_ APP_parkAssistStatus : 40|2@1+ (1,0) [0|3] "" Vector__XXX
 SG_ APP_useParkDistancesFromAP : 42|1@1+ (1,0) [0|1] "" Vector__XXX

BO_ 1353 APP_info: 8 APP
 SG_ APP_infoIndex M : 0|8@1+ (1,0) [0|255] "" Vector__XXX
 SG_ APP_buildType m0 : 8|8@1+ (1,0) [0|255] "" Vector__XXX

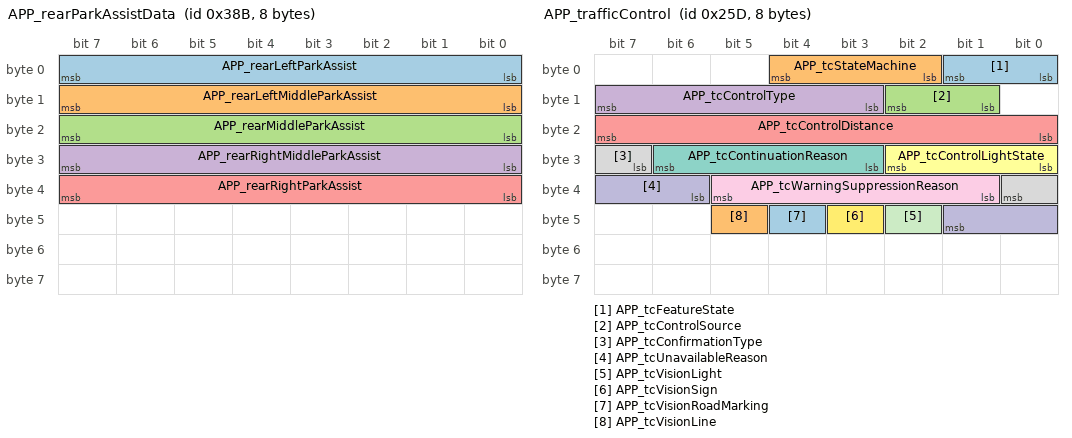
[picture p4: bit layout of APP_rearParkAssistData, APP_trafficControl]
BO_ 907 APP_rearParkAssistData: 8 APP
 SG_ APP_rearLeftParkAssist : 0|8@1+ (1,0) [0|255] "cm" Vector__XXX
 SG_ APP_rearLeftMiddleParkAssist : 8|8@1+ (1,0) [0|255] "cm" Vector__XXX
 SG_ APP_rearMiddleParkAssist : 16|8@1+ (1,0) [0|255] "cm" Vector__XXX
 SG_ APP_rearRightMiddleParkAssist : 24|8@1+ (1,0) [0|255] "cm" Vector__XXX
 SG_ APP_rearRightParkAssist : 32|8@1+ (1,0) [0|255] "cm" Vector__XXX

BO_ 601 APP_status: 8 APP
 SG_ APP_watchdogState : 0|3@1+ (1,0) [0|7] "" Vector__XXX
 SG_ APP_fusedState : 3|2@1+ (1,0) [0|3] "" Vector__XXX
 SG_ APP_cameraHeaterRequest : 5|1@1+ (1,0) [0|1] "" Vector__XXX
 SG_ APP_factorySummonStatus : 6|4@1+ (1,0) [0|15] "" Vector__XXX
 SG_ APP_clipRecordingStatus : 10|3@1+ (1,0) [0|7] "" Vector__XXX
 SG_ APP_allowApActivationWithBrake : 13|1@1+ (1,0) [0|1] "" Vector__XXX
 SG_ APP_summonUnavailableReason : 14|5@1+ (1,0) [0|31] "" Vector__XXX
 SG_ APP_fsdSuspendState : 19|2@1+ (1,0) [0|3] "" Vector__XXX
 SG_ APP_fsdRevokeStrikeoutCount : 21|3@1+ (1,0) [0|7] "" Vector__XXX
 SG_ APP_teslaVisionSupported : 24|2@1+ (1,0) [0|3] "" Vector__XXX
 SG_ APP_teslaVisionUnsupportedReason : 26|3@1+ (1,0) [0|7] "" Vector__XXX
 SG_ APP_fsdRevokeCount : 29|3@1+ (1,0) [0|7] "" Vector__XXX
 SG_ APP_excessiveAccelPedalWarning : 32|1@1+ (1,0) [0|1] "" Vector__XXX
 SG_ APP_unifiedObjectStackSupported : 33|2@1+ (1,0) [0|3] "" Vector__XXX
 SG_ APP_sendingBUCStream : 35|1@1+ (1,0) [0|1] "" Vector__XXX
 SG_ APP_DDAWSystemStatus : 37|3@1+ (1,0) [0|7] "" Vector__XXX
 SG_ APP_socOperatingMode : 40|2@1+ (1,0) [0|3] "" Vector__XXX
 SG_ APP_summonVersionIdentifier : 42|2@1+ (1,0) [0|3] "" Vector__XXX
 SG_ APP_sentryState : 44|3@1+ (1,0) [0|7] "" Vector__XXX
 SG_ APP_autoparkVersionIdentifier : 47|2@1+ (1,0) [0|3] "" Vector__XXX
 SG_ APP_autonomySystemHealth : 49|1@1+ (1,0) [0|1] "" Vector__XXX
 SG_ APP_uiEthFailoverDisabled : 50|1@1+ (1,0) [0|1] "" Vector__XXX
 SG_ APP_suspendResumeAvailable : 51|1@1+ (1,0) [0|1] "" Vector__XXX
 SG_ APP_statusCounter : 52|4@1+ (1,0) [0|15] "" Vector__XXX
 SG_ APP_statusChecksum : 56|8@1+ (1,0) [0|255] "" Vector__XXX

BO_ 605 APP_trafficControl: 8 APP
 SG_ APP_tcFeatureState : 0|2@1+ (1,0) [0|3] "" Vector__XXX
 SG_ APP_tcStateMachine : 2|3@1+ (1,0) [0|7] "" Vector__XXX
 SG_ APP_tcControlSource : 9|2@1+ (1,0) [0|3] "" Vector__XXX
 SG_ APP_tcControlType : 11|5@1+ (1,0) [0|31] "" Vector__XXX
 SG_ APP_tcControlDistance : 16|8@1+ (1,0) [0|255] "m" Vector__XXX
 SG_ APP_tcControlLightState : 24|3@1+ (1,0) [0|7] "" Vector__XXX
 SG_ APP_tcContinuationReason : 27|4@1+ (1,0) [0|15] "" Vector__XXX
 SG_ APP_tcConfirmationType : 31|2@1+ (1,0) [0|3] "" Vector__XXX
 SG_ APP_tcWarningSuppressionReason : 33|5@1+ (1,0) [0|31] "" Vector__XXX
 SG_ APP_tcUnavailableReason : 38|4@1+ (1,0) [0|15] "" Vector__XXX
 SG_ APP_tcVisionLight : 42|1@1+ (1,0) [0|1] "" Vector__XXX
 SG_ APP_tcVisionSign : 43|1@1+ (1,0) [0|1] "" Vector__XXX
 SG_ APP_tcVisionRoadMarking : 44|1@1+ (1,0) [0|1] "" Vector__XXX
 SG_ APP_tcVisionLine : 45|1@1+ (1,0) [0|1] "" Vector__XXX

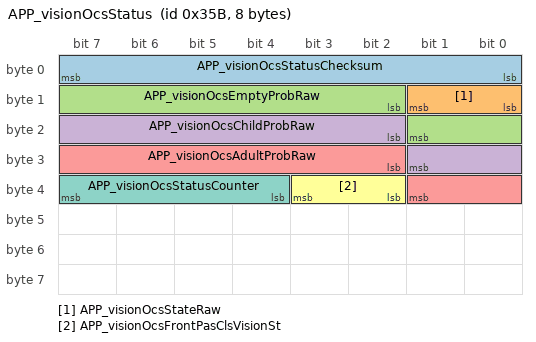
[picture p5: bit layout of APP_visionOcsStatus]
BO_ 859 APP_visionOcsStatus: 8 APP
 SG_ APP_visionOcsStatusChecksum : 0|8@1+ (1,0) [0|255] "" Vector__XXX
 SG_ APP_visionOcsStateRaw : 8|2@1+ (1,0) [0|3] "" Vector__XXX
 SG_ APP_visionOcsEmptyProbRaw : 10|8@1+ (0.004,0) [0|1.02] "points" Vector__XXX
 SG_ APP_visionOcsChildProbRaw : 18|8@1+ (0.004,0) [0|1.02] "points" Vector__XXX
 SG_ APP_visionOcsAdultProbRaw : 26|8@1+ (0.004,0) [0|1.02] "points" Vector__XXX
 SG_ APP_visionOcsFrontPasClsVisionSt : 34|2@1+ (1,0) [0|3] "" Vector__XXX
 SG_ APP_visionOcsStatusCounter : 36|4@1+ (1,0) [0|15] "" Vector__XXX

BO_ 809 APP_warningMatrix0: 8 APP
 SG_ APP_w001_DEPRECATED : 0|1@1+ (1,0) [0|1] "" Vector__XXX
 SG_ APP_w002_ldwDisabled : 1|1@1+ (1,0) [0|1] "" Vector__XXX
 SG_ APP_w003_isaDisabled : 2|1@1+ (1,0) [0|1] "" Vector__XXX
 SG_ APP_w004_accDisabled : 3|1@1+ (1,0) [0|1] "" Vector__XXX
 SG_ APP_w005_fcwCancelled : 4|1@1+ (1,0) [0|1] "" Vector__XXX
 SG_ APP_w006_aebCancelled : 5|1@1+ (1,0) [0|1] "" Vector__XXX
 SG_ APP_w007_ahlbDisabled : 6|1@1+ (1,0) [0|1] "" Vector__XXX
 SG_ APP_w008_parkDisabled : 7|1@1+ (1,0) [0|1] "" Vector__XXX
 SG_ APP_w009_aebFault : 8|1@1+ (1,0) [0|1] "" Vector__XXX
 SG_ APP_w010_radcCalibIssue : 9|1@1+ (1,0) [0|1] "" Vector__XXX
 SG_ APP_w011_scaEvent : 10|1@1+ (1,0) [0|1] "" Vector__XXX
 SG_ APP_w012_Cam_BootFailure : 11|1@1+ (1,0) [0|1] "" Vector__XXX
 SG_ APP_w013_Cam_Watchdog : 12|1@1+ (1,0) [0|1] "" Vector__XXX
 SG_ APP_w014_swAssert : 13|1@1+ (1,0) [0|1] "" Vector__XXX
 SG_ APP_w015_Camera_Failsafes : 14|1@1+ (1,0) [0|1] "" Vector__XXX
 SG_ APP_w016_aeb_e_event : 15|1@1+ (1,0) [0|1] "" Vector__XXX
 SG_ APP_w017_Cam_Msg_MIA : 16|1@1+ (1,0) [0|1] "" Vector__XXX
 SG_ APP_w018_ECU_Power_Issue : 17|1@1+ (1,0) [0|1] "" Vector__XXX
 SG_ APP_w019_ECU_Stack_Overflow : 18|1@1+ (1,0) [0|1] "" Vector__XXX
 SG_ APP_w020_ECU_checkstopError : 19|1@1+ (1,0) [0|1] "" Vector__XXX
 SG_ APP_w021_ECU_Temperature_Issue : 20|1@1+ (1,0) [0|1] "" Vector__XXX
 SG_ APP_w022_ECU_EEPROM_Failure : 21|1@1+ (1,0) [0|1] "" Vector__XXX
 SG_ APP_w023_ECU_Cam_Statemismatc : 22|1@1+ (1,0) [0|1] "" Vector__XXX
 SG_ APP_w024_ECU_Watchdog_Reset : 23|1@1+ (1,0) [0|1] "" Vector__XXX
 SG_ APP_w025_LC_Steering_Override : 24|1@1+ (1,0) [0|1] "" Vector__XXX
 SG_ APP_w026_ECU_timingIssue : 25|1@1+ (1,0) [0|1] "" Vector__XXX
 SG_ APP_w027_ECU_Reset_Fault : 26|1@1+ (1,0) [0|1] "" Vector__XXX
 SG_ APP_w028_spi_rx_error : 27|1@1+ (1,0) [0|1] "" Vector__XXX
 SG_ APP_w029_spi_tx_error : 28|1@1+ (1,0) [0|1] "" Vector__XXX
 SG_ APP_w030_Heater_Issue : 29|1@1+ (1,0) [0|1] "" Vector__XXX
 SG_ APP_w031_canRxError : 30|1@1+ (1,0) [0|1] "" Vector__XXX
 SG_ APP_w032_canTxError : 31|1@1+ (1,0) [0|1] "" Vector__XXX
 SG_ APP_w033_gtwMia : 32|1@1+ (1,0) [0|1] "" Vector__XXX
 SG_ APP_w034_sccmMia : 33|1@1+ (1,0) [0|1] "" Vector__XXX
 SG_ APP_w035_espMia : 34|1@1+ (1,0) [0|1] "" Vector__XXX
 SG_ APP_w036_bdyMia : 35|1@1+ (1,0) [0|1] "" Vector__XXX
 SG_ APP_w037_camTacIssue : 36|1@1+ (1,0) [0|1] "" Vector__XXX
 SG_ APP_w038_camFailure : 37|1@1+ (1,0) [0|1] "" Vector__XXX
 SG_ APP_w039_sdm_rcm_Mia : 38|1@1+ (1,0) [0|1] "" Vector__XXX
 SG_ APP_w040_autopilotAngleSaturated : 39|1@1+ (1,0) [0|1] "" Vector__XXX
 SG_ APP_w041_autopilotRateSaturated : 40|1@1+ (1,0) [0|1] "" Vector__XXX
 SG_ APP_w042_autopilotAborting : 41|1@1+ (1,0) [0|1] "" Vector__XXX
 SG_ APP_w043_camLongRunTime : 42|1@1+ (1,0) [0|1] "" Vector__XXX
 SG_ APP_w044_appMobileyeFailure : 43|1@1+ (1,0) [0|1] "" Vector__XXX
 SG_ APP_w045_radMia : 44|1@1+ (1,0) [0|1] "" Vector__XXX
 SG_ APP_w046_eepromRecordAbsent : 45|1@1+ (1,0) [0|1] "" Vector__XXX
 SG_ APP_w047_edrEvent : 46|1@1+ (1,0) [0|1] "" Vector__XXX
 SG_ APP_w048_APP_Features_Disabled : 47|1@1+ (1,0) [0|1] "" Vector__XXX
 SG_ APP_w049_eyeqVersionMismatch : 48|1@1+ (1,0) [0|1] "" Vector__XXX
 SG_ APP_w050_aeb_event : 49|1@1+ (1,0) [0|1] "" Vector__XXX
 SG_ APP_w051_radcEcuIssue : 50|1@1+ (1,0) [0|1] "" Vector__XXX
 SG_ APP_w052_radcSensorIssue : 51|1@1+ (1,0) [0|1] "" Vector__XXX
 SG_ APP_w053_radcCommIssue : 52|1@1+ (1,0) [0|1] "" Vector__XXX
 SG_ APP_w054_camAutofix : 53|1@1+ (1,0) [0|1] "" Vector__XXX
 SG_ APP_w055_radcVersionMismatch : 54|1@1+ (1,0) [0|1] "" Vector__XXX
 SG_ APP_w056_diMia : 55|1@1+ (1,0) [0|1] "" Vector__XXX
 SG_ APP_w057_mcuMia : 56|1@1+ (1,0) [0|1] "" Vector__XXX
 SG_ APP_w058_epbMia : 57|1@1+ (1,0) [0|1] "" Vector__XXX
 SG_ APP_w059_parkMia : 58|1@1+ (1,0) [0|1] "" Vector__XXX
 SG_ APP_w060_fcw_event : 59|1@1+ (1,0) [0|1] "" Vector__XXX
 SG_ APP_w061_airSuspensionMia : 60|1@1+ (1,0) [0|1] "" Vector__XXX
 SG_ APP_w062_radcAlignment : 61|1@1+ (1,0) [0|1] "" Vector__XXX
 SG_ APP_w063_parkVersionMismatch : 62|1@1+ (1,0) [0|1] "" Vector__XXX
 SG_ APP_w064_epasMia : 63|1@1+ (1,0) [0|1] "" Vector__XXX

BO_ 873 APP_warningMatrix1: 8 APP
 SG_ APP_w065_deserializerOvercurrent : 0|1@1+ (1,0) [0|1] "" Vector__XXX
 SG_ APP_w066_deserializerLockLost : 1|1@1+ (1,0) [0|1] "" Vector__XXX
 SG_ APP_w067_steeringAlignment : 2|1@1+ (1,0) [0|1] "" Vector__XXX
 SG_ APP_w068_vlInconsistency : 3|1@1+ (1,0) [0|1] "" Vector__XXX
 SG_ APP_w069_apcSpaceMasked : 4|1@1+ (1,0) [0|1] "" Vector__XXX
 SG_ APP_w070_apcIncompleteCal : 5|1@1+ (1,0) [0|1] "" Vector__XXX
 SG_ APP_w071_selfparkStarted : 6|1@1+ (1,0) [0|1] "" Vector__XXX
 SG_ APP_w072_selfparkComplete : 7|1@1+ (1,0) [0|1] "" Vector__XXX
 SG_ APP_w073_issueEscalatedLDW : 8|1@1+ (1,0) [0|1] "" Vector__XXX
 SG_ APP_w074_inPathStationaryObst : 9|1@1+ (1,0) [0|1] "" Vector__XXX
 SG_ APP_w075_scMia : 10|1@1+ (1,0) [0|1] "" Vector__XXX
 SG_ APP_w076_mobilEyeSetC : 11|1@1+ (1,0) [0|1] "" Vector__XXX
 SG_ APP_w077_pmmActive : 12|1@1+ (1,0) [0|1] "" Vector__XXX
 SG_ APP_w078_pmmActive2 : 13|1@1+ (1,0) [0|1] "" Vector__XXX
 SG_ APP_w079_edrAvailable : 14|1@1+ (1,0) [0|1] "" Vector__XXX
 SG_ APP_w080_accFailedActivation : 15|1@1+ (1,0) [0|1] "" Vector__XXX
 SG_ APP_w081_pmmActiveBraking : 16|1@1+ (1,0) [0|1] "" Vector__XXX
 SG_ APP_w082_inPathFSviolation : 17|1@1+ (1,0) [0|1] "" Vector__XXX
 SG_ APP_w083_inPathRADObject : 18|1@1+ (1,0) [0|1] "" Vector__XXX
 SG_ APP_w084_pmmIPSO : 19|1@1+ (1,0) [0|1] "" Vector__XXX
 SG_ APP_w085_pmmSteering : 20|1@1+ (1,0) [0|1] "" Vector__XXX
 SG_ APP_w086_robCollision : 21|1@1+ (1,0) [0|1] "" Vector__XXX
 SG_ APP_w087_DEPRECATED : 22|1@1+ (1,0) [0|1] "" Vector__XXX
 SG_ APP_w088_DEPRECATED : 23|1@1+ (1,0) [0|1] "" Vector__XXX
 SG_ APP_w089_DEPRECATED : 24|1@1+ (1,0) [0|1] "" Vector__XXX
 SG_ APP_w090_DEPRECATED : 25|1@1+ (1,0) [0|1] "" Vector__XXX
 SG_ APP_w091_DEPRECATED : 26|1@1+ (1,0) [0|1] "" Vector__XXX
 SG_ APP_w092_DEPRECATED : 27|1@1+ (1,0) [0|1] "" Vector__XXX
 SG_ APP_w093_DEPRECATED : 28|1@1+ (1,0) [0|1] "" Vector__XXX
 SG_ APP_w094_DEPRECATED : 29|1@1+ (1,0) [0|1] "" Vector__XXX
 SG_ APP_w095_DEPRECATED : 30|1@1+ (1,0) [0|1] "" Vector__XXX
 SG_ APP_w096_DEPRECATED : 31|1@1+ (1,0) [0|1] "" Vector__XXX
 SG_ APP_w097_DEPRECATED : 32|1@1+ (1,0) [0|1] "" Vector__XXX
 SG_ APP_w098_DEPRECATED : 33|1@1+ (1,0) [0|1] "" Vector__XXX
 SG_ APP_w099_DEPRECATED : 34|1@1+ (1,0) [0|1] "" Vector__XXX
 SG_ APP_w100_DEPRECATED : 35|1@1+ (1,0) [0|1] "" Vector__XXX
 SG_ APP_w101_DEPRECATED : 36|1@1+ (1,0) [0|1] "" Vector__XXX
 SG_ APP_w102_DEPRECATED : 37|1@1+ (1,0) [0|1] "" Vector__XXX
 SG_ APP_w103_robExperimentalAEB : 38|1@1+ (1,0) [0|1] "" Vector__XXX
 SG_ APP_w104_DEPRECATED : 39|1@1+ (1,0) [0|1] "" Vector__XXX
 SG_ APP_w105_DEPRECATED : 40|1@1+ (1,0) [0|1] "" Vector__XXX
 SG_ APP_w106_torsionBarOffset : 41|1@1+ (1,0) [0|1] "" Vector__XXX

CM_ SG_ 1513 APP_sw285_exitTransportMode "Driver assistance computer (primary): sw285 exit transport mode";
CM_ SG_ 1513 APP_sw285_satRejectionTimeout "Driver assistance computer (primary): sw285 sat rejection timeout";
CM_ SG_ 1513 APP_sw285_gpsPPSMissing "Driver assistance computer (primary): sw285 gps PPS missing";
CM_ SG_ 1513 APP_sw286_cfgBufNull "Driver assistance computer (primary): sw286 cfg buf null";
CM_ SG_ 1513 APP_sw286_invalidID "Driver assistance computer (primary): sw286 invalid ID";
CM_ SG_ 1513 APP_sw286_gpsBufferOverflow "Driver assistance computer (primary): sw286 gps buffer overflow";
CM_ SG_ 1513 APP_sw286_navx5CfgFailed "Driver assistance computer (primary): sw286 navx5 cfg failed";
CM_ SG_ 1513 APP_sw286_mcuNMEAmsgUDPinvalid "Driver assistance computer (primary): sw286 mcu NME amsg UD pinvalid";
CM_ SG_ 1513 APP_sw286_mcuDbgMsgInvalid "Driver assistance computer (primary): sw286 mcu dbg msg invalid";
CM_ SG_ 1513 APP_sw286_mcuDbgMsgTooBig "Driver assistance computer (primary): sw286 mcu dbg msg too big";
CM_ SG_ 1513 APP_sw286_mcuFwdNMEAfail "Driver assistance computer (primary): sw286 mcu fwd NME afail";
CM_ SG_ 1513 APP_sw286_NMEAinvalidChecksum "Driver assistance computer (primary): sw286 NME ainvalid checksum";
CM_ SG_ 1513 APP_sw286_unexpectedNMEAmsg "Driver assistance computer (primary): sw286 unexpected NME amsg";
CM_ SG_ 1513 APP_sw286_UARTbusFull "Driver assistance computer (primary): sw286 UAR tbus full";
CM_ SG_ 1513 APP_sw286_UARTframeError "Driver assistance computer (primary): sw286 UAR tframe error";
CM_ SG_ 1513 APP_sw286_UBXrxFrameTooBig "Driver assistance computer (primary): sw286 UB xrx frame too big";
CM_ SG_ 1513 APP_sw286_emptyValidNMEA "Driver assistance computer (primary): sw286 empty valid NMEA";
CM_ SG_ 1513 APP_sw286_invalidAsciiNMEA "Driver assistance computer (primary): sw286 invalid ascii NMEA";
CM_ SG_ 1513 APP_sw286_wheeltickUARTfault "Driver assistance computer (primary): sw286 wheeltick UAR tfault";
CM_ SG_ 1513 APP_sw286_baudrateMismatch "Driver assistance computer (primary): sw286 baudrate mismatch";
CM_ SG_ 1513 APP_sw286_wheelTickInvalidSrc "Driver assistance computer (primary): sw286 wheel tick invalid src";
CM_ SG_ 1513 APP_sw286_UARTparityError "Driver assistance computer (primary): sw286 UAR tparity error";
CM_ SG_ 1513 APP_sw286_UARTrxFifoOverflow "Driver assistance computer (primary): sw286 UAR trx fifo overflow";
CM_ SG_ 1513 APP_sw286_UARTrxFifoUnderflow "Driver assistance computer (primary): sw286 UAR trx fifo underflow";
CM_ SG_ 1513 APP_sw286_UARTtxFifoOverflow "Driver assistance computer (primary): sw286 UAR ttx fifo overflow";
CM_ SG_ 1513 APP_sw286_esfWtMsgTimeout "Driver assistance computer (primary): sw286 esf wt msg timeout";
CM_ SG_ 1513 APP_sw286_PFLASHReadError "Driver assistance computer (primary): sw286 PFLASH read error";
CM_ SG_ 1513 APP_sw286_PFLASHWriteError "Driver assistance computer (primary): sw286 PFLASH write error";
CM_ SG_ 1513 APP_sw286_gpsCfgNack "Driver assistance computer (primary): sw286 gps cfg nack";
CM_ SG_ 1513 APP_sw286_gpsCfgIdFail "Driver assistance computer (primary): sw286 gps cfg id fail";
CM_ SG_ 1513 APP_sw286_gpsSetCfgNoAck "Driver assistance computer (primary): sw286 gps set cfg no ack";
CM_ SG_ 1513 APP_sw286_gpsReadCfgNoResponse "Driver assistance computer (primary): sw286 gps read cfg no response";
CM_ SG_ 1513 APP_sw286_ubxErrorReported "Driver assistance computer (primary): sw286 ubx error reported";
CM_ SG_ 1513 APP_sw288_dist_to_stop "Driver assistance computer (primary): sw288 dist to stop";
CM_ SG_ 1513 APP_sw288_ego_speed "Driver assistance computer (primary): sw288 ego speed";
CM_ SG_ 1513 APP_sw288_ego_acceleration "Driver assistance computer (primary): sw288 ego acceleration";
CM_ SG_ 1513 APP_sw291_dist_to_stop "Driver assistance computer (primary): sw291 dist to stop";
CM_ SG_ 1513 APP_sw291_ego_speed "Driver assistance computer (primary): sw291 ego speed";
CM_ SG_ 1513 APP_sw291_ego_acceleration "Driver assistance computer (primary): sw291 ego acceleration";
CM_ SG_ 1513 APP_sw293_clockFrequencyDrift "Driver assistance computer (primary): sw293 clock frequency drift";
CM_ SG_ 1513 APP_sw294_clockFrequencyDrift "Driver assistance computer (primary): sw294 clock frequency drift";
CM_ SG_ 1513 APP_sw295_clockFrequencyDrift "Driver assistance computer (primary): sw295 clock frequency drift";
CM_ SG_ 1513 APP_sw296_clockFrequencyDrift "Driver assistance computer (primary): sw296 clock frequency drift";
CM_ SG_ 1513 APP_sw297_clockFrequencyDrift "Driver assistance computer (primary): sw297 clock frequency drift";
CM_ SG_ 1513 APP_sw298_clockFrequencyDrift "Driver assistance computer (primary): sw298 clock frequency drift";
CM_ SG_ 1513 APP_sw299_clockFrequencyDrift "Driver assistance computer (primary): sw299 clock frequency drift";
CM_ SG_ 1513 APP_sw300_clockFrequencyDrift "Driver assistance computer (primary): sw300 clock frequency drift";
CM_ SG_ 1513 APP_sw301_clockFrequencyDrift "Driver assistance computer (primary): sw301 clock frequency drift";
CM_ SG_ 1513 APP_sw302_AP_vehicleState10Hz "Driver assistance computer (primary): sw302 AP vehicle state10 hz";
CM_ SG_ 1513 APP_sw302_cameraCleaningStatus "Driver assistance computer (primary): sw302 camera cleaning status";
CM_ SG_ 1513 APP_sw304_lssLPillarBlocked "Driver assistance computer (primary): sw304 lss l pillar blocked";
CM_ SG_ 1513 APP_sw304_lssRPillarBlocked "Driver assistance computer (primary): sw304 lss r pillar blocked";
CM_ SG_ 1513 APP_sw304_lssLRepeaterBlocked "Driver assistance computer (primary): sw304 lss l repeater blocked";
CM_ SG_ 1513 APP_sw304_lssRRepeaterBlocked "Driver assistance computer (primary): sw304 lss r repeater blocked";
CM_ SG_ 1513 APP_sw304_lssMainBlocked "Driver assistance computer (primary): sw304 lss main blocked";
CM_ SG_ 1513 APP_sw305_lssLPillarStreamExit "Driver assistance computer (primary): sw305 lss l pillar stream exit";
CM_ SG_ 1513 APP_sw305_lssRPillarStreamExit "Driver assistance computer (primary): sw305 lss r pillar stream exit";
CM_ SG_ 1513 APP_sw305_lssLRepeaterStreamExit "Driver assistance computer (primary): sw305 lss l repeater stream exit";
CM_ SG_ 1513 APP_sw305_lssRRepeaterStreamExit "Driver assistance computer (primary): sw305 lss r repeater stream exit";
CM_ SG_ 1513 APP_sw306_lssUssS1Blocked "Driver assistance computer (primary): sw306 lss uss S1 blocked";
CM_ SG_ 1513 APP_sw306_lssUssS2Blocked "Driver assistance computer (primary): sw306 lss uss S2 blocked";
CM_ SG_ 1513 APP_sw306_lssUssS3Blocked "Driver assistance computer (primary): sw306 lss uss S3 blocked";
CM_ SG_ 1513 APP_sw306_lssUssS4Blocked "Driver assistance computer (primary): sw306 lss uss S4 blocked";
CM_ SG_ 1513 APP_sw306_lssUssS5Blocked "Driver assistance computer (primary): sw306 lss uss S5 blocked";
CM_ SG_ 1513 APP_sw306_lssUssS6Blocked "Driver assistance computer (primary): sw306 lss uss S6 blocked";
CM_ SG_ 1513 APP_sw306_lssUssS7Blocked "Driver assistance computer (primary): sw306 lss uss S7 blocked";
CM_ SG_ 1513 APP_sw306_lssUssS8Blocked "Driver assistance computer (primary): sw306 lss uss S8 blocked";
CM_ SG_ 1513 APP_sw306_lssUssS9Blocked "Driver assistance computer (primary): sw306 lss uss S9 blocked";
CM_ SG_ 1513 APP_sw306_lssUssS10Blocked "Driver assistance computer (primary): sw306 lss uss S10 blocked";
CM_ SG_ 1513 APP_sw306_lssUssS11Blocked "Driver assistance computer (primary): sw306 lss uss S11 blocked";
CM_ SG_ 1513 APP_sw306_lssUssS12Blocked "Driver assistance computer (primary): sw306 lss uss S12 blocked";
CM_ SG_ 1513 APP_sw307_lssTurnSignalFLFault "Driver assistance computer (primary): sw307 lss turn signal FL fault";
CM_ SG_ 1513 APP_sw307_lssTurnSignalFRFault "Driver assistance computer (primary): sw307 lss turn signal FR fault";
CM_ SG_ 1513 APP_sw307_lssTurnSignalRLFault "Driver assistance computer (primary): sw307 lss turn signal RL fault";
CM_ SG_ 1513 APP_sw307_lssTurnSignalRRFault "Driver assistance computer (primary): sw307 lss turn signal RR fault";
CM_ SG_ 1513 APP_sw308_IBST_status "Driver assistance computer (primary): sw308 IBST status";
CM_ SG_ 1513 APP_sw321_energyStatus "Driver assistance computer (primary): sw321 energy status";
CM_ SG_ 1513 APP_sw321_status "Driver assistance computer (primary): sw321 status";
CM_ SG_ 1513 APP_sw321_autonomyHealth "Driver assistance computer (primary): sw321 autonomy health";
CM_ SG_ 1513 APP_sw322_sunGlare "Driver assistance computer (primary): sw322 sun glare";
CM_ SG_ 1513 APP_sw322_blinded "Driver assistance computer (primary): sw322 blinded";
CM_ SG_ 1513 APP_sw322_falseWipe "Driver assistance computer (primary): sw322 false wipe";
CM_ SG_ 1513 APP_sw323_confidence "Driver assistance computer (primary): sw323 confidence";
CM_ SG_ 1513 APP_sw323_distance "Driver assistance computer (primary): sw323 distance";
CM_ SG_ 1513 APP_sw323_ttc "Driver assistance computer (primary): sw323 ttc";
CM_ SG_ 1513 APP_sw324_state "Driver assistance computer (primary): sw324 state";
CM_ SG_ 1513 APP_sw325_taskId "Driver assistance computer (primary): sw325 task id";
CM_ SG_ 1513 APP_sw325_issue "Driver assistance computer (primary): sw325 issue";
CM_ SG_ 1513 APP_sw327_driveHandSideMismatch "Driver assistance computer (primary): sw327 drive hand side mismatch";
CM_ SG_ 1513 APP_sw327_hardwareTypeMismatch "Driver assistance computer (primary): sw327 hardware type mismatch";
CM_ SG_ 1513 APP_sw327_turboTypeMismatch "Driver assistance computer (primary): sw327 turbo type mismatch";
CM_ SG_ 1513 APP_sw327_epasTypeMismatch "Driver assistance computer (primary): sw327 epas type mismatch";
CM_ SG_ 1513 APP_sw327_radarTypeMismatch "Driver assistance computer (primary): sw327 radar type mismatch";
CM_ SG_ 1513 APP_sw327_chassisTypeMismatch "Driver assistance computer (primary): sw327 chassis type mismatch";
CM_ SG_ 1513 APP_sw327_displayTypeMismatch "Driver assistance computer (primary): sw327 display type mismatch";
CM_ SG_ 1513 APP_sw327_cameraTypeMismatch "Driver assistance computer (primary): sw327 camera type mismatch";
CM_ SG_ 1513 APP_sw327_parkAssistTypeMismatch "Driver assistance computer (primary): sw327 park assist type mismatch";
CM_ SG_ 1513 APP_sw327_selfieCamTypeMismatch "Driver assistance computer (primary): sw327 selfie cam type mismatch";
CM_ SG_ 1513 APP_sw328_ussS1Unavailable "Driver assistance computer (primary): sw328 uss S1 unavailable";
CM_ SG_ 1513 APP_sw328_ussS2Unavailable "Driver assistance computer (primary): sw328 uss S2 unavailable";
CM_ SG_ 1513 APP_sw328_ussS3Unavailable "Driver assistance computer (primary): sw328 uss S3 unavailable";
CM_ SG_ 1513 APP_sw328_ussS4Unavailable "Driver assistance computer (primary): sw328 uss S4 unavailable";
CM_ SG_ 1513 APP_sw328_ussS5Unavailable "Driver assistance computer (primary): sw328 uss S5 unavailable";
CM_ SG_ 1513 APP_sw328_ussS6Unavailable "Driver assistance computer (primary): sw328 uss S6 unavailable";
CM_ SG_ 1513 APP_sw328_ussS7Unavailable "Driver assistance computer (primary): sw328 uss S7 unavailable";
CM_ SG_ 1513 APP_sw328_ussS8Unavailable "Driver assistance computer (primary): sw328 uss S8 unavailable";
CM_ SG_ 1513 APP_sw328_ussS9Unavailable "Driver assistance computer (primary): sw328 uss S9 unavailable";
CM_ SG_ 1513 APP_sw328_ussS10Unavailable "Driver assistance computer (primary): sw328 uss S10 unavailable";
CM_ SG_ 1513 APP_sw328_ussS11Unavailable "Driver assistance computer (primary): sw328 uss S11 unavailable";
CM_ SG_ 1513 APP_sw328_ussS12Unavailable "Driver assistance computer (primary): sw328 uss S12 unavailable";
CM_ SG_ 1513 APP_sw328_fisheyeStreamExit "Driver assistance computer (primary): sw328 fisheye stream exit";
CM_ SG_ 1513 APP_sw328_lPillarStreamExit "Driver assistance computer (primary): sw328 l pillar stream exit";
CM_ SG_ 1513 APP_sw328_rPillarStreamExit "Driver assistance computer (primary): sw328 r pillar stream exit";
CM_ SG_ 1513 APP_sw328_lRepeaterStreamExit "Driver assistance computer (primary): sw328 l repeater stream exit";
CM_ SG_ 1513 APP_sw328_rRepeaterStreamExit "Driver assistance computer (primary): sw328 r repeater stream exit";
CM_ SG_ 1513 APP_sw328_backupStreamExit "Driver assistance computer (primary): sw328 backup stream exit";
CM_ SG_ 1513 APP_sw328_fisheyeCal "Driver assistance computer (primary): sw328 fisheye cal";
CM_ SG_ 1513 APP_sw328_lPillarCal "Driver assistance computer (primary): sw328 l pillar cal";
CM_ SG_ 1513 APP_sw328_rPillarCal "Driver assistance computer (primary): sw328 r pillar cal";
CM_ SG_ 1513 APP_sw328_lRepeaterCal "Driver assistance computer (primary): sw328 l repeater cal";
CM_ SG_ 1513 APP_sw328_rRepeaterCal "Driver assistance computer (primary): sw328 r repeater cal";
CM_ SG_ 1513 APP_sw328_backupCal "Driver assistance computer (primary): sw328 backup cal";
CM_ SG_ 1513 APP_sw328_epasMia "Driver assistance computer (primary): sw328 epas mia";
CM_ SG_ 1513 APP_sw328_espMia "Driver assistance computer (primary): sw328 esp mia";
CM_ SG_ 1513 APP_sw328_parkMia "Driver assistance computer (primary): sw328 park mia";
CM_ SG_ 1513 APP_sw328_sccmMia "Driver assistance computer (primary): sw328 sccm mia";
CM_ SG_ 1513 APP_sw328_scMia "Driver assistance computer (primary): sw328 sc mia";
CM_ SG_ 1513 APP_sw328_ussOLONotEnabled "Driver assistance computer (primary): sw328 uss OLO not enabled";
CM_ SG_ 1513 APP_sw328_ussPASNotEnabled "Driver assistance computer (primary): sw328 uss PAS not enabled";
CM_ SG_ 1513 APP_sw328_ussOOCNotEnabled "Driver assistance computer (primary): sw328 uss OOC not enabled";
CM_ SG_ 1513 APP_sw328_ussTemporaryFault "Driver assistance computer (primary): sw328 uss temporary fault";
CM_ SG_ 1513 APP_sw328_ussSystemError "Driver assistance computer (primary): sw328 uss system error";
CM_ SG_ 1513 APP_sw328_ussFault "Driver assistance computer (primary): sw328 uss fault";
CM_ SG_ 1513 APP_sw328_ussStatusOutOfDate "Driver assistance computer (primary): sw328 uss status out of date";
CM_ SG_ 1513 APP_sw328_perceptionUnhealthy "Driver assistance computer (primary): sw328 perception unhealthy";
CM_ SG_ 1513 APP_sw328_drivableSpaceUnhealthy "Driver assistance computer (primary): sw328 drivable space unhealthy";
CM_ SG_ 1513 APP_sw328_uiDisplayNotOk "Driver assistance computer (primary): sw328 ui display not ok";
CM_ SG_ 1513 APP_sw328_externalLightsOff "Driver assistance computer (primary): sw328 external lights off";
CM_ SG_ 1513 APP_sw328_forwardCamerasBlinded "Driver assistance computer (primary): sw328 forward cameras blinded";
CM_ SG_ 1513 APP_sw328_backupCameraBlinded "Driver assistance computer (primary): sw328 backup camera blinded";
CM_ SG_ 1513 APP_sw328_extComputeNotActive "Driver assistance computer (primary): sw328 ext compute not active";
CM_ SG_ 1513 APP_sw329_cipvSysReqAccel "Driver assistance computer (primary): sw329 cipv sys req accel";
CM_ SG_ 1513 APP_sw329_leftLaneReqAccel "Driver assistance computer (primary): sw329 left lane req accel";
CM_ SG_ 1513 APP_sw329_rightLaneReqAccel "Driver assistance computer (primary): sw329 right lane req accel";
CM_ SG_ 1513 APP_sw329_leftLaneAvailable "Driver assistance computer (primary): sw329 left lane available";
CM_ SG_ 1513 APP_sw329_rightLaneAvailable "Driver assistance computer (primary): sw329 right lane available";
CM_ SG_ 1513 APP_sw329_laneChangeLeft "Driver assistance computer (primary): sw329 lane change left";
CM_ SG_ 1513 APP_sw329_laneChangeRight "Driver assistance computer (primary): sw329 lane change right";
CM_ SG_ 1513 APP_sw329_leftLaneChngBehStatus "Driver assistance computer (primary): sw329 left lane chng beh status";
CM_ SG_ 1513 APP_sw329_rightLaneChngBehStatus "Driver assistance computer (primary): sw329 right lane chng beh status";
CM_ SG_ 1513 APP_sw330_initFailure "Driver assistance computer (primary): sw330 init failure";
CM_ SG_ 1513 APP_sw330_streamExit "Driver assistance computer (primary): sw330 stream exit";
CM_ SG_ 1513 APP_sw330_ledFault "Driver assistance computer (primary): sw330 led fault";
CM_ SG_ 1513 APP_sw331_lPillarOccluded "Driver assistance computer (primary): sw331 l pillar occluded";
CM_ SG_ 1513 APP_sw331_rPillarOccluded "Driver assistance computer (primary): sw331 r pillar occluded";
CM_ SG_ 1513 APP_sw331_lRepeaterOccluded "Driver assistance computer (primary): sw331 l repeater occluded";
CM_ SG_ 1513 APP_sw331_rRepeaterOccluded "Driver assistance computer (primary): sw331 r repeater occluded";
CM_ SG_ 1513 APP_sw331_gpsDegraded "Driver assistance computer (primary): sw331 gps degraded";
CM_ SG_ 1513 APP_sw331_poorWeather "Driver assistance computer (primary): sw331 poor weather";
CM_ SG_ 1513 APP_sw331_invalidMap "Driver assistance computer (primary): sw331 invalid map";
CM_ SG_ 1513 APP_sw331_adverseRoadConditions "Driver assistance computer (primary): sw331 adverse road conditions";
CM_ SG_ 1513 APP_sw332_narrowWithFisheye "Driver assistance computer (primary): sw332 narrow with fisheye";
CM_ SG_ 1513 APP_sw332_pillars "Driver assistance computer (primary): sw332 pillars";
CM_ SG_ 1513 APP_sw348_main "Driver assistance computer (primary): sw348 main";
CM_ SG_ 1513 APP_sw348_narrow "Driver assistance computer (primary): sw348 narrow";
CM_ SG_ 1513 APP_sw348_fisheye "Driver assistance computer (primary): sw348 fisheye";
CM_ SG_ 1513 APP_sw348_leftPillar "Driver assistance computer (primary): sw348 left pillar";
CM_ SG_ 1513 APP_sw348_rightPillar "Driver assistance computer (primary): sw348 right pillar";
CM_ SG_ 1513 APP_sw348_leftRepeater "Driver assistance computer (primary): sw348 left repeater";
CM_ SG_ 1513 APP_sw348_rightRepeater "Driver assistance computer (primary): sw348 right repeater";
CM_ SG_ 1513 APP_sw348_backup "Driver assistance computer (primary): sw348 backup";
CM_ SG_ 1513 APP_sw348_selfie "Driver assistance computer (primary): sw348 selfie";
CM_ SG_ 1513 APP_sw348_fascia "Driver assistance computer (primary): sw348 fascia";
CM_ SG_ 1513 APP_sw351_errorCode "Driver assistance computer (primary): sw351 error code";
CM_ SG_ 1513 APP_sw352_errorCode "Driver assistance computer (primary): sw352 error code";
CM_ SG_ 1513 APP_sw353_errorCode "Driver assistance computer (primary): sw353 error code";
CM_ SG_ 1513 APP_sw355_quad1 "Driver assistance computer (primary): sw355 quad1";
CM_ SG_ 1513 APP_sw355_quad2 "Driver assistance computer (primary): sw355 quad2";
CM_ SG_ 1513 APP_sw355_quad3 "Driver assistance computer (primary): sw355 quad3";
CM_ SG_ 1513 APP_sw355_quad1FailureRate "Driver assistance computer (primary): sw355 quad1 failure rate";
CM_ SG_ 1513 APP_sw355_quad2FailureRate "Driver assistance computer (primary): sw355 quad2 failure rate";
CM_ SG_ 1513 APP_sw355_quad3FailureRate "Driver assistance computer (primary): sw355 quad3 failure rate";
CM_ SG_ 1513 APP_sw357_cabinCameraFailsafeAct "Driver assistance computer (primary): sw357 cabin camera failsafe active";
CM_ SG_ 1513 APP_sw357_cameraDisabled "Driver assistance computer (primary): sw357 camera disabled";
CM_ SG_ 1513 APP_sw357_cameraNotStreaming "Driver assistance computer (primary): sw357 camera not streaming";
CM_ SG_ 1513 APP_sw357_disableByBuildCfg "Driver assistance computer (primary): sw357 disable by build cfg";
CM_ SG_ 1513 APP_sw357_invalidCameraFailsafe "Driver assistance computer (primary): sw357 invalid camera failsafe";
CM_ SG_ 1513 APP_sw357_invalidDrowsinessPredi "Driver assistance computer (primary): sw357 invalid drowsiness predictions";
CM_ SG_ 1513 APP_sw357_invalidSccmSteeringAng "Driver assistance computer (primary): sw357 invalid sccm steering angle";
CM_ SG_ 1513 APP_sw357_invalidSccmSteeri_0001 "Driver assistance computer (primary): sw357 invalid sccm steering angle rate";
CM_ SG_ 1513 APP_sw357_noVisionOutput "Driver assistance computer (primary): sw357 no vision output";
CM_ SG_ 1513 APP_sw357_poorFrontCameraVisibil "Driver assistance computer (primary): sw357 poor front camera visibility";
CM_ SG_ 1513 APP_sw357_staleVisionDv "Driver assistance computer (primary): sw357 stale vision dv";
CM_ SG_ 1513 APP_sw357_staleVisionOutput "Driver assistance computer (primary): sw357 stale vision output";
CM_ SG_ 1513 APP_sw357_sccmMia "Driver assistance computer (primary): sw357 sccm mia";
CM_ SG_ 1513 APP_sw357_electricalFaultForSccm "Driver assistance computer (primary): sw357 electrical fault for sccm";
CM_ SG_ 1513 APP_sw357_electricalFaultForMain "Driver assistance computer (primary): sw357 electrical fault for main cam";
CM_ SG_ 1513 APP_sw357_electricalFaultForCabi "Driver assistance computer (primary): sw357 electrical fault for cabin cam";
CM_ SG_ 1513 APP_sw357_mainCameraFailsafeActi "Driver assistance computer (primary): sw357 main camera failsafe active";
CM_ SG_ 1513 APP_sw357_electricalFaultForFish "Driver assistance computer (primary): sw357 electrical fault for fisheye cam";
CM_ SG_ 1513 APP_sw357_fisheyeCameraFailsafeA "Driver assistance computer (primary): sw357 fisheye camera failsafe active";
CM_ SG_ 1513 APP_sw357_camCalibOutOfBounds "Driver assistance computer (primary): sw357 cam calib out of bounds";
CM_ SG_ 1513 APP_sw358_noSpeedLimitSource "Driver assistance computer (primary): sw358 no speed limit source";
CM_ SG_ 1513 APP_sw358_mainCameraBlinded "Driver assistance computer (primary): sw358 main camera blinded";
CM_ SG_ 1513 APP_sw358_fisheyeCameraBlinded "Driver assistance computer (primary): sw358 fisheye camera blinded";
CM_ SG_ 1513 APP_sw358_mainCameraStreamUnavai "Driver assistance computer (primary): sw358 main camera stream unavailable";
CM_ SG_ 1513 APP_sw358_fisheyeCameraStreamUna "Driver assistance computer (primary): sw358 fisheye camera stream unavailable";
CM_ SG_ 1513 APP_sw358_camCalibOutOfBounds "Driver assistance computer (primary): sw358 cam calib out of bounds";
CM_ SG_ 1513 APP_sw359_mainCameraBlinded "Driver assistance computer (primary): sw359 main camera blinded";
CM_ SG_ 1513 APP_sw359_narrowCameraBlinded "Driver assistance computer (primary): sw359 narrow camera blinded";
CM_ SG_ 1513 APP_sw359_fisheyeCameraBlinded "Driver assistance computer (primary): sw359 fisheye camera blinded";
CM_ SG_ 1513 APP_sw362_fasciaCamDeserFault "Driver assistance computer (primary): sw362 fascia cam deser fault";
CM_ SG_ 1513 APP_sw362_fasciaCamI2CbusFault "Driver assistance computer (primary): sw362 fascia cam I2 cbus fault";
CM_ SG_ 1513 APP_sw362_fasciaCamSensorFault "Driver assistance computer (primary): sw362 fascia cam sensor fault";
CM_ SG_ 1513 APP_sw362_fasciaCamSerFault "Driver assistance computer (primary): sw362 fascia cam ser fault";
CM_ SG_ 1513 APP_sw363_exitStatus "Driver assistance computer (primary): sw363 exit status";
CM_ SG_ 1513 APP_sw363_bufferError "Driver assistance computer (primary): sw363 buffer error";
CM_ SG_ 1513 APP_sw363_frameGrabFailure "Driver assistance computer (primary): sw363 frame grab failure";
CM_ SG_ 1513 APP_sw363_gainControlFailure "Driver assistance computer (primary): sw363 gain control failure";
CM_ SG_ 1513 APP_sw363_tempMonitorFailure "Driver assistance computer (primary): sw363 temp monitor failure";
CM_ SG_ 1513 APP_sw363_firstFrameGrabFailure "Driver assistance computer (primary): sw363 first frame grab failure";
CM_ SG_ 1513 APP_sw363_deserParityError "Driver assistance computer (primary): sw363 deser parity error";
CM_ SG_ 1513 APP_sw363_deserLockError "Driver assistance computer (primary): sw363 deser lock error";
CM_ SG_ 1513 APP_sw363_deserCrcError "Driver assistance computer (primary): sw363 deser crc error";
CM_ SG_ 1513 APP_sw363_imagerHeartbeat "Driver assistance computer (primary): sw363 imager heartbeat";
CM_ SG_ 1513 APP_sw363_serializerCrcErrCount "Driver assistance computer (primary): sw363 serializer crc err count";
CM_ SG_ 1513 APP_sw363_deserLineLengthError "Driver assistance computer (primary): sw363 deser line length error";
CM_ SG_ 1513 APP_sw363_numCaptureRecoveries "Driver assistance computer (primary): sw363 num capture recoveries";
CM_ SG_ 1513 APP_sw363_currentTemperature "Driver assistance computer (primary): sw363 current temperature";
CM_ SG_ 1513 APP_sw363_minTemperature "Driver assistance computer (primary): sw363 min temperature";
CM_ SG_ 1513 APP_sw363_maxTemperature "Driver assistance computer (primary): sw363 max temperature";
CM_ SG_ 1513 APP_sw364_colorFilterMismatch "Driver assistance computer (primary): sw364 color filter mismatch";
CM_ SG_ 1513 APP_sw364_detectedColorFilter "Driver assistance computer (primary): sw364 detected color filter";
CM_ SG_ 1513 APP_sw364_expectedColorFilter "Driver assistance computer (primary): sw364 expected color filter";
CM_ SG_ 1513 APP_sw364_cameraPositionMismatch "Driver assistance computer (primary): sw364 camera position mismatch";
CM_ SG_ 1513 APP_sw364_blacklistedFuseID "Driver assistance computer (primary): sw364 blacklisted fuse ID";
CM_ SG_ 1513 APP_sw364_uuidMismatch "Driver assistance computer (primary): sw364 uuid mismatch";
CM_ SG_ 1513 APP_sw364_detectedPosition "Driver assistance computer (primary): sw364 detected position";
CM_ SG_ 1513 APP_sw365_fasciaCamExtNoCalFile "Driver assistance computer (primary): sw365 fascia cam ext no cal file";
CM_ SG_ 1513 APP_sw366_clockFrequencyDrift "Driver assistance computer (primary): sw366 clock frequency drift";
CM_ SG_ 1513 APP_sw371_decryptionFailed "Driver assistance computer (primary): sw371 decryption failed";
CM_ SG_ 1513 APP_sw389_frontCamResidue "Driver assistance computer (primary): sw389 front cam residue";
CM_ SG_ 1513 APP_sw389_leftPillarCamResidue "Driver assistance computer (primary): sw389 left pillar cam residue";
CM_ SG_ 1513 APP_sw389_rightPillarCamResidue "Driver assistance computer (primary): sw389 right pillar cam residue";
CM_ SG_ 1513 APP_sw397_apImuNoise "Driver assistance computer (primary): sw397 ap imu noise";
CM_ SG_ 1513 APP_sw399_status "Driver assistance computer (primary): sw399 status";
CM_ SG_ 1513 APP_sw404_status "Driver assistance computer (primary): sw404 status";
CM_ SG_ 1513 APP_sw404_autonomyHealth "Driver assistance computer (primary): sw404 autonomy health";
CM_ SG_ 1513 APP_sw407_unknown "Driver assistance computer (primary): sw407 unknown";
CM_ SG_ 1513 APP_sw407_neutralGear "Driver assistance computer (primary): sw407 neutral gear";
CM_ SG_ 1513 APP_sw407_noAutonomyModeActive "Driver assistance computer (primary): sw407 no autonomy mode active";
CM_ SG_ 1513 APP_sw407_delivered "Driver assistance computer (primary): sw407 delivered";
CM_ SG_ 1513 APP_sw407_fsdDisabled "Driver assistance computer (primary): sw407 fsd disabled";
CM_ SG_ 1513 APP_sw407_outsideGeofence "Driver assistance computer (primary): sw407 outside geofence";
CM_ SG_ 1513 APP_sw407_driverlessGtwConfigOff "Driver assistance computer (primary): sw407 driverless gtw config off";
CM_ SG_ 1513 APP_sw407_sentryActive "Driver assistance computer (primary): sw407 sentry active";
CM_ SG_ 1513 APP_sw407_apPowerRequestNotNomin "Driver assistance computer (primary): sw407 ap power request not nominal";
CM_ SG_ 1513 APP_sw407_gnssDegradedSignalStre "Driver assistance computer (primary): sw407 gnss degraded signal strength";
CM_ SG_ 1513 APP_sw407_cameraCalibration "Driver assistance computer (primary): sw407 camera calibration";
CM_ SG_ 1513 APP_sw407_factoryCalibration "Driver assistance computer (primary): sw407 factory calibration";
CM_ SG_ 1513 APP_sw407_frontCamerasStreamLost "Driver assistance computer (primary): sw407 front cameras stream lost";
CM_ SG_ 1513 APP_sw407_leftCamerasStreamLost "Driver assistance computer (primary): sw407 left cameras stream lost";
CM_ SG_ 1513 APP_sw407_rightCamerasStreamLost "Driver assistance computer (primary): sw407 right cameras stream lost";
CM_ SG_ 1513 APP_sw407_backupCameraStreamLost "Driver assistance computer (primary): sw407 backup camera stream lost";
CM_ SG_ 1513 APP_sw407_outOfSyncCameraStreams "Driver assistance computer (primary): sw407 out of sync camera streams";
CM_ SG_ 1513 APP_sw407_cameraAutoexposureLost "Driver assistance computer (primary): sw407 camera autoexposure lost";
CM_ SG_ 1513 APP_sw407_cameraNightOffgassing "Driver assistance computer (primary): sw407 camera night offgassing";
CM_ SG_ 1513 APP_sw407_cameraVisionFailsafeBe "Driver assistance computer (primary): sw407 camera vision failsafe before activation";
CM_ SG_ 1513 APP_sw407_severeFrontVisionOcclu "Driver assistance computer (primary): sw407 severe front vision occlusion";
CM_ SG_ 1513 APP_sw407_severeLeftVisionOcclus "Driver assistance computer (primary): sw407 severe left vision occlusion";
CM_ SG_ 1513 APP_sw407_severeRightVisionOcclu "Driver assistance computer (primary): sw407 severe right vision occlusion";
CM_ SG_ 1513 APP_sw407_severeReverseVisionOcc "Driver assistance computer (primary): sw407 severe reverse vision occlusion";
CM_ SG_ 1513 APP_sw407_frequentVisionOcclusio "Driver assistance computer (primary): sw407 frequent vision occlusion";
CM_ SG_ 1513 APP_sw407_fasciaVisionOcclusionA "Driver assistance computer (primary): sw407 fascia vision occlusion at stop";
CM_ SG_ 1513 APP_sw407_safetyDriverUnbuckled "Driver assistance computer (primary): sw407 safety driver unbuckled";
CM_ SG_ 1513 APP_sw407_visionFpsLow "Driver assistance computer (primary): sw407 vision fps low";
CM_ SG_ 1513 APP_sw407_driverDoorOpen "Driver assistance computer (primary): sw407 driver door open";
CM_ SG_ 1513 APP_sw407_passengerDoorOpen "Driver assistance computer (primary): sw407 passenger door open";
CM_ SG_ 1513 APP_sw407_trunkOpen "Driver assistance computer (primary): sw407 trunk open";
CM_ SG_ 1513 APP_sw407_frunkOpen "Driver assistance computer (primary): sw407 frunk open";
CM_ SG_ 1513 APP_sw407_notPowerStateDrive "Driver assistance computer (primary): sw407 not power state drive";
CM_ SG_ 1513 APP_sw407_cruiseUnavailable "Driver assistance computer (primary): sw407 cruise unavailable";
CM_ SG_ 1513 APP_sw407_cruiseNotActive "Driver assistance computer (primary): sw407 cruise not active";
CM_ SG_ 1513 APP_sw407_cruiseFault "Driver assistance computer (primary): sw407 cruise fault";
CM_ SG_ 1513 APP_sw407_epasEacUnavailable "Driver assistance computer (primary): sw407 epas eac unavailable";
CM_ SG_ 1513 APP_sw407_epasEacNotActive "Driver assistance computer (primary): sw407 epas eac not active";
CM_ SG_ 1513 APP_sw407_epasDriverlessModeNotA "Driver assistance computer (primary): sw407 epas driverless mode not active";
CM_ SG_ 1513 APP_sw407_epasRedundancyLost "Driver assistance computer (primary): sw407 epas redundancy lost";
CM_ SG_ 1513 APP_sw407_epasSystemTorqueReduce "Driver assistance computer (primary): sw407 epas system torque reduced";
CM_ SG_ 1513 APP_sw407_navGoalInvalid "Driver assistance computer (primary): sw407 nav goal invalid";
CM_ SG_ 1513 APP_sw407_noFixedRoute "Driver assistance computer (primary): sw407 no fixed route";
CM_ SG_ 1513 APP_sw407_notInParkNoTakeover "Driver assistance computer (primary): sw407 not in park no takeover";
CM_ SG_ 1513 APP_sw407_extendedComputeInactiv "Driver assistance computer (primary): sw407 extended compute inactive";
CM_ SG_ 1513 APP_sw407_epbRedundantBrakingSta "Driver assistance computer (primary): sw407 epb redundant braking status";
CM_ SG_ 1513 APP_sw407_cruiseStackMismatch "Driver assistance computer (primary): sw407 cruise stack mismatch";
CM_ SG_ 1513 APP_sw407_vehicleAutonomyBehavio "Driver assistance computer (primary): sw407 vehicle autonomy behavior mismatch";
CM_ SG_ 1513 APP_sw408_lvDegradedState "Driver assistance computer (primary): sw408 lv degraded state";
CM_ SG_ 1513 APP_sw408_lvCriticalState "Driver assistance computer (primary): sw408 lv critical state";
CM_ SG_ 1513 APP_sw408_controllerSolverFailur "Driver assistance computer (primary): sw408 controller solver failure";
CM_ SG_ 1513 APP_sw408_controllerSolverDegrad "Driver assistance computer (primary): sw408 controller solver degraded";
CM_ SG_ 1513 APP_sw408_controllerSolverCritic "Driver assistance computer (primary): sw408 controller solver critical";
CM_ SG_ 1513 APP_sw408_driverNotPresent "Driver assistance computer (primary): sw408 driver not present";
CM_ SG_ 1513 APP_sw408_driverMonitorStrikeout "Driver assistance computer (primary): sw408 driver monitor strikeout";
CM_ SG_ 1513 APP_sw408_passengerExpected "Driver assistance computer (primary): sw408 passenger expected";
CM_ SG_ 1513 APP_sw408_rideshareIngressNoNavR "Driver assistance computer (primary): sw408 rideshare ingress no nav route";
CM_ SG_ 1513 APP_sw408_cabinCamBlinded "Driver assistance computer (primary): sw408 cabin cam blinded";
CM_ SG_ 1513 APP_sw408_incompatibleSystemHeal "Driver assistance computer (primary): sw408 incompatible system health";
CM_ SG_ 1513 APP_sw408_stateMachineDisabled "Driver assistance computer (primary): sw408 state machine disabled";
CM_ SG_ 1513 APP_sw408_imuReplicationNotReady "Driver assistance computer (primary): sw408 imu replication not ready";
CM_ SG_ 1513 APP_sw408_singleSocHealthyExcept "Driver assistance computer (primary): sw408 single soc healthy exception";
CM_ SG_ 1513 APP_sw408_systemUnhealthyDevOver "Driver assistance computer (primary): sw408 system unhealthy dev override";
CM_ SG_ 1513 APP_sw408_passengerUnbuckled "Driver assistance computer (primary): sw408 passenger unbuckled";
CM_ SG_ 1513 APP_sw408_passengerUnbuckledActi "Driver assistance computer (primary): sw408 passenger unbuckled active ride";
CM_ SG_ 1513 APP_sw408_chargeCableConnectedOr "Driver assistance computer (primary): sw408 charge cable connected or status unknown";
CM_ SG_ 1513 APP_sw408_fleetMaintenanceRequir "Driver assistance computer (primary): sw408 fleet maintenance required";
CM_ SG_ 1513 APP_sw408_sgkPlannerActiveDRN "Driver assistance computer (primary): sw408 sgk planner active DRN";
CM_ SG_ 1513 APP_sw408_visionCabinOccupancyUn "Driver assistance computer (primary): sw408 vision cabin occupancy unavailable";
CM_ SG_ 1513 APP_sw408_lowTirePressureReading "Driver assistance computer (primary): sw408 low tire pressure reading";
CM_ SG_ 1513 APP_sw408_elevatedTirePressureRe "Driver assistance computer (primary): sw408 elevated tire pressure reading";
CM_ SG_ 1513 APP_sw408_washerFluidLow "Driver assistance computer (primary): sw408 washer fluid low";
CM_ SG_ 1513 APP_sw408_imuDataNotReliable "Driver assistance computer (primary): sw408 imu data not reliable";
CM_ SG_ 1513 APP_sw408_flatTire "Driver assistance computer (primary): sw408 flat tire";
CM_ SG_ 1513 APP_sw408_tirePressureHardWarnin "Driver assistance computer (primary): sw408 tire pressure hard warning";
CM_ SG_ 1513 APP_sw408_epbParkingAvailability "Driver assistance computer (primary): sw408 epb parking availability faulted";
CM_ SG_ 1513 APP_sw408_epbParkingAvailab_0002 "Driver assistance computer (primary): sw408 epb parking availability speed invalid";
CM_ SG_ 1513 APP_sw408_epbParkingAvailab_0001 "Driver assistance computer (primary): sw408 epb parking availability request path degraded";
CM_ SG_ 1513 APP_sw408_epbParkingAvailab_0003 "Driver assistance computer (primary): sw408 epb parking availability unknown";
CM_ SG_ 1513 APP_sw408_epbStatusNotParked "Driver assistance computer (primary): sw408 epb status not parked";
CM_ SG_ 1513 APP_sw408_diLosingPropulsion "Driver assistance computer (primary): sw408 di losing propulsion";
CM_ SG_ 1513 APP_sw408_diVdcStateNotNormal "Driver assistance computer (primary): sw408 di vdc state not normal";
CM_ SG_ 1513 APP_sw408_diBrakingDecelerationU "Driver assistance computer (primary): sw408 di braking deceleration unavailable";
CM_ SG_ 1513 APP_sw408_apRedundancyUnavailabl "Driver assistance computer (primary): sw408 ap redundancy unavailable";
CM_ SG_ 1513 APP_sw408_headlightsNotAimed "Driver assistance computer (primary): sw408 headlights not aimed";
CM_ SG_ 1513 APP_sw408_lowBeamLightFaulted "Driver assistance computer (primary): sw408 low beam light faulted";
CM_ SG_ 1513 APP_sw408_highBeamLightFaulted "Driver assistance computer (primary): sw408 high beam light faulted";
CM_ SG_ 1513 APP_sw408_lowBeamLightFaultedInL "Driver assistance computer (primary): sw408 low beam light faulted in low vis";
CM_ SG_ 1513 APP_sw408_highBeamLightFaultedIn "Driver assistance computer (primary): sw408 high beam light faulted in low vis";
CM_ SG_ 1513 APP_sw408_brakeLightFaulted "Driver assistance computer (primary): sw408 brake light faulted";
CM_ SG_ 1513 APP_sw408_allBrakeLightsFaulted "Driver assistance computer (primary): sw408 all brake lights faulted";
CM_ SG_ 1513 APP_sw408_leftTurnLightFaulted "Driver assistance computer (primary): sw408 left turn light faulted";
CM_ SG_ 1513 APP_sw408_rightTurnLightFaulted "Driver assistance computer (primary): sw408 right turn light faulted";
CM_ SG_ 1513 APP_sw408_reverseLightFaulted "Driver assistance computer (primary): sw408 reverse light faulted";
CM_ SG_ 1513 APP_sw408_tailLightFaulted "Driver assistance computer (primary): sw408 tail light faulted";
CM_ SG_ 1513 APP_sw408_allTailLightsFaultedIn "Driver assistance computer (primary): sw408 all tail lights faulted in low vis";
CM_ SG_ 1513 APP_sw409_windshieldCamHeaterFau "Driver assistance computer (primary): sw409 windshield cam heater fault";
CM_ SG_ 1513 APP_sw409_leftPillarCamHeaterFau "Driver assistance computer (primary): sw409 left pillar cam heater fault";
CM_ SG_ 1513 APP_sw409_rightPillarCamHeaterFa "Driver assistance computer (primary): sw409 right pillar cam heater fault";
CM_ SG_ 1513 APP_sw409_wiperNotHealthy "Driver assistance computer (primary): sw409 wiper not healthy";
CM_ SG_ 1513 APP_sw409_brakePedalPressed "Driver assistance computer (primary): sw409 brake pedal pressed";
CM_ SG_ 1513 APP_sw409_rankerNotHealthy "Driver assistance computer (primary): sw409 ranker not healthy";
CM_ SG_ 1513 APP_sw409_redundantBrakePathActi "Driver assistance computer (primary): sw409 redundant brake path active";
CM_ SG_ 1513 APP_sw409_redundantBrakesNotRead "Driver assistance computer (primary): sw409 redundant brakes not ready";
CM_ SG_ 1513 APP_sw409_redundantBrakesNotArme "Driver assistance computer (primary): sw409 redundant brakes not armed";
CM_ SG_ 1513 APP_sw409_redundantBrakesRedunda "Driver assistance computer (primary): sw409 redundant brakes redundancy lost";
CM_ SG_ 1513 APP_sw409_redundantBrakesFailOpe "Driver assistance computer (primary): sw409 redundant brakes fail operational";
CM_ SG_ 1513 APP_sw409_rcmWarningIndicatorOn "Driver assistance computer (primary): sw409 rcm warning indicator on";
CM_ SG_ 1513 APP_sw409_seatbeltStatusUnhealth "Driver assistance computer (primary): sw409 seatbelt status unhealthy";
CM_ SG_ 1513 APP_sw409_teleopStreamsUnhealthy "Driver assistance computer (primary): sw409 teleop streams unhealthy";
CM_ SG_ 1513 APP_sw409_seatOccupancyStatusUnh "Driver assistance computer (primary): sw409 seat occupancy status unhealthy";
CM_ SG_ 1513 APP_sw409_visionFailoverActive "Driver assistance computer (primary): sw409 vision failover active";
CM_ SG_ 1513 APP_sw409_poorLocalizationAccura "Driver assistance computer (primary): sw409 poor localization accuracy";
CM_ SG_ 1513 APP_sw409_apsCanMessagesMia "Driver assistance computer (primary): sw409 aps can messages mia";
CM_ SG_ 1513 APP_sw409_diChassisControlCanMes "Driver assistance computer (primary): sw409 di chassis control can message mia";
CM_ SG_ 1513 APP_sw409_diSystemStatusCanMessa "Driver assistance computer (primary): sw409 di system status can messages mia";
CM_ SG_ 1513 APP_sw409_steeringCanMessagesMia "Driver assistance computer (primary): sw409 steering can messages mia";
CM_ SG_ 1513 APP_sw409_parkBrakeCanMessagesMi "Driver assistance computer (primary): sw409 park brake can messages mia";
CM_ SG_ 1513 APP_sw409_brakingCanMessagesMia "Driver assistance computer (primary): sw409 braking can messages mia";
CM_ SG_ 1513 APP_sw409_imuCanMessagesMia "Driver assistance computer (primary): sw409 imu can messages mia";
CM_ SG_ 1513 APP_sw409_narrowWashNotAvailable "Driver assistance computer (primary): sw409 narrow wash not available";
CM_ SG_ 1513 APP_sw409_driverNotPresentPreAct "Driver assistance computer (primary): sw409 driver not present pre activation";
CM_ SG_ 1513 APP_sw409_passengerUnexpectedRid "Driver assistance computer (primary): sw409 passenger unexpected ride inactive";
CM_ SG_ 1513 APP_sw409_waitingForPassengerEgr "Driver assistance computer (primary): sw409 waiting for passenger egress";
CM_ SG_ 1513 APP_sw409_unassignedPassengerUnb "Driver assistance computer (primary): sw409 unassigned passenger unbuckled";
CM_ SG_ 1513 APP_sw409_notAuthenticatedForDri "Driver assistance computer (primary): sw409 not authenticated for drive";
CM_ SG_ 1513 APP_sw409_coolantSystemNotReady "Driver assistance computer (primary): sw409 coolant system not ready";
CM_ SG_ 1513 APP_sw409_defogSystemNotReady "Driver assistance computer (primary): sw409 defog system not ready";
CM_ SG_ 1513 APP_sw409_coolantSystemUnhealthy "Driver assistance computer (primary): sw409 coolant system unhealthy";
CM_ SG_ 1513 APP_sw409_defogSystemUnhealthy "Driver assistance computer (primary): sw409 defog system unhealthy";
CM_ SG_ 1513 APP_sw409_diSpeedCanMessageMia "Driver assistance computer (primary): sw409 di speed can message mia";
CM_ SG_ 1513 APP_sw409_cameraRedundancyNotRea "Driver assistance computer (primary): sw409 camera redundancy not ready";
CM_ SG_ 1513 APP_sw409_audioBusDown "Driver assistance computer (primary): sw409 audio bus down";
CM_ SG_ 1513 APP_sw409_autonomousBehaviorsTas "Driver assistance computer (primary): sw409 autonomous behaviors task suspending";
CM_ SG_ 1513 APP_sw409_hvDriveNoRestart "Driver assistance computer (primary): sw409 hv drive no restart";
CM_ SG_ 1513 APP_sw409_vehicleLosingHv "Driver assistance computer (primary): sw409 vehicle losing hv";
CM_ SG_ 1513 APP_sw409_bmsCanMessagesMia "Driver assistance computer (primary): sw409 bms can messages mia";
CM_ SG_ 1513 APP_sw409_cameraPreconditioningI "Driver assistance computer (primary): sw409 camera preconditioning incomplete";
CM_ SG_ 1513 APP_sw409_safetyOperatorNotPrese "Driver assistance computer (primary): sw409 safety operator not present";
CM_ SG_ 1513 APP_sw409_unsupervisedRtNotAllow "Driver assistance computer (primary): sw409 unsupervised rt not allowed";
CM_ SG_ 1513 APP_sw409_driverPresentNotAllowe "Driver assistance computer (primary): sw409 driver present not allowed";
CM_ SG_ 1513 APP_sw409_apThermalDegradedBlock "Driver assistance computer (primary): sw409 ap thermal degraded block activation";
CM_ SG_ 1513 APP_sw409_apThermalDegradedPullo "Driver assistance computer (primary): sw409 ap thermal degraded pullover req";
CM_ SG_ 1513 APP_sw409_autonomousBehaviorsLin "Driver assistance computer (primary): sw409 autonomous behaviors link not established";
CM_ SG_ 1513 APP_sw410_noValidSgkStatus "Driver assistance computer (primary): sw410 no valid sgk status";
CM_ SG_ 1513 APP_sw410_autonomyControllingAnd "Driver assistance computer (primary): sw410 autonomy controlling and not parked";
CM_ SG_ 1513 APP_sw410_cameraDayOffgassing "Driver assistance computer (primary): sw410 camera day offgassing";
CM_ SG_ 1513 APP_sw410_missionPlannerDesiredB "Driver assistance computer (primary): sw410 mission planner desired behavior not e2e";
CM_ SG_ 1513 APP_sw410_arbiterSelectedBehavio "Driver assistance computer (primary): sw410 arbiter selected behavior not e2e";
CM_ SG_ 1513 APP_sw410_arbiterSelectedBe_0001 "Driver assistance computer (primary): sw410 arbiter selected behavior out of date";
CM_ SG_ 1513 APP_sw410_peerVisionFailoverActi "Driver assistance computer (primary): sw410 peer vision failover active";
CM_ SG_ 1513 APP_sw410_apsAUnhealthy "Driver assistance computer (primary): sw410 aps a unhealthy";
CM_ SG_ 1513 APP_sw410_apsBUnhealthy "Driver assistance computer (primary): sw410 aps b unhealthy";
CM_ SG_ 1513 APP_sw410_apsSelfCanFaulted "Driver assistance computer (primary): sw410 aps self can faulted";
CM_ SG_ 1513 APP_sw410_apsPeerCanFaulted "Driver assistance computer (primary): sw410 aps peer can faulted";
CM_ SG_ 1513 APP_sw410_apsSelfImemFaulted "Driver assistance computer (primary): sw410 aps self imem faulted";
CM_ SG_ 1513 APP_sw410_apsPeerImemFaulted "Driver assistance computer (primary): sw410 aps peer imem faulted";
CM_ SG_ 1513 APP_sw410_apsSelfVrmFaulted "Driver assistance computer (primary): sw410 aps self vrm faulted";
CM_ SG_ 1513 APP_sw410_apsPeerVrmFaulted "Driver assistance computer (primary): sw410 aps peer vrm faulted";
CM_ SG_ 1513 APP_sw410_apsSelfPmicFaulted "Driver assistance computer (primary): sw410 aps self pmic faulted";
CM_ SG_ 1513 APP_sw410_apsPeerPmicFaulted "Driver assistance computer (primary): sw410 aps peer pmic faulted";
CM_ SG_ 1513 APP_sw410_apsSingleCameraPowerFa "Driver assistance computer (primary): sw410 aps single camera power failure";
CM_ SG_ 1513 APP_sw410_apsDualCameraPowerFail "Driver assistance computer (primary): sw410 aps dual camera power failure";
CM_ SG_ 1513 APP_sw410_apTaskPendingReboot "Driver assistance computer (primary): sw410 ap task pending reboot";
CM_ SG_ 1513 APP_sw410_anyLvHealthCanMessageM "Driver assistance computer (primary): sw410 any lv health can message mia";
CM_ SG_ 1513 APP_sw410_anyLvHealthCanMessageI "Driver assistance computer (primary): sw410 any lv health can message invalid";
CM_ SG_ 1513 APP_sw410_uiHealthStatusCanMessa "Driver assistance computer (primary): sw410 ui health status can message mia";
CM_ SG_ 1513 APP_sw410_gtwCarConfigCanMessage "Driver assistance computer (primary): sw410 gtw car config can message mia";
CM_ SG_ 1513 APP_sw410_bbStatusCanMessageMia "Driver assistance computer (primary): sw410 bb status can message mia";
CM_ SG_ 1513 APP_sw410_vcleftDoorStatusCanMes "Driver assistance computer (primary): sw410 vcleft door status can message mia";
CM_ SG_ 1513 APP_sw410_vcrightDoorStatusCanMe "Driver assistance computer (primary): sw410 vcright door status can message mia";
CM_ SG_ 1513 APP_sw410_anyLeftDoorOpenButtonF "Driver assistance computer (primary): sw410 any left door open button faulted";
CM_ SG_ 1513 APP_sw410_anyRightDoorOpenButton "Driver assistance computer (primary): sw410 any right door open button faulted";
CM_ SG_ 1513 APP_sw410_sgkAutonomyStateNotInS "Driver assistance computer (primary): sw410 sgk autonomy state not in sync";
CM_ SG_ 1513 APP_sw410_apThermalModelFaultDet "Driver assistance computer (primary): sw410 ap thermal model fault detected";
CM_ SG_ 1513 APP_sw410_wheelSpeedsCanMessageM "Driver assistance computer (primary): sw410 wheel speeds can message mia";
CM_ SG_ 1513 APP_sw410_allWheelSpeedsSensorsF "Driver assistance computer (primary): sw410 all wheel speeds sensors faulted";
CM_ SG_ 1513 APP_sw410_diAutonomyHealthCanMes "Driver assistance computer (primary): sw410 di autonomy health can message mia";
CM_ SG_ 1513 APP_sw410_devPulloverOverrideAct "Driver assistance computer (primary): sw410 dev pullover override active";
CM_ SG_ 1513 APP_sw410_imuRedundancyLost "Driver assistance computer (primary): sw410 imu redundancy lost";
CM_ SG_ 1513 APP_sw410_noImuSourcesAvailable "Driver assistance computer (primary): sw410 no imu sources available";
CM_ SG_ 1513 APP_sw410_tamperingDetected "Driver assistance computer (primary): sw410 tampering detected";
CM_ SG_ 1513 APP_sw410_cabinCameraIrLedFaulte "Driver assistance computer (primary): sw410 cabin camera ir led faulted";
CM_ SG_ 1513 APP_sw410_cameraExposureMismatch "Driver assistance computer (primary): sw410 camera exposure mismatch";
CM_ SG_ 1513 APP_sw410_ssdClipLoggingInactive "Driver assistance computer (primary): sw410 ssd clip logging inactive";
CM_ SG_ 1513 APP_sw410_selfNetworkDecryptionN "Driver assistance computer (primary): sw410 self network decryption not ready";
CM_ SG_ 1513 APP_sw410_uiCenterDisplayUnavail "Driver assistance computer (primary): sw410 ui center display unavailable";
CM_ SG_ 1513 APP_sw410_uiConnectivityOffline "Driver assistance computer (primary): sw410 ui connectivity offline";
CM_ SG_ 1513 APP_sw410_uiConnectivityHwUnheal "Driver assistance computer (primary): sw410 ui connectivity hw unhealthy";
CM_ SG_ 1513 APP_sw410_uiQtCarUnavailable "Signal reported by Driver assistance computer (primary)";
CM_ SG_ 1513 APP_sw410_gnssUartFaulted "Driver assistance computer (primary): sw410 gnss uart faulted";
CM_ SG_ 1513 APP_sw410_gnssAntennaFaulted "Driver assistance computer (primary): sw410 gnss antenna faulted";
CM_ SG_ 1513 APP_sw413_apSystemIssuePendingRe "Driver assistance computer (primary): sw413 ap system issue pending reboot";
CM_ SG_ 1513 APP_sw413_diVelocityEstimatorSta "Driver assistance computer (primary): sw413 di velocity estimator state degraded";
CM_ SG_ 1513 APP_sw413_noVehicleSpeedSourceAv "Driver assistance computer (primary): sw413 no vehicle speed source available";
CM_ SG_ 1513 APP_sw413_secondaryWasherFluidLo "Driver assistance computer (primary): sw413 secondary washer fluid low";
CM_ SG_ 1513 APP_sw413_leftRepeaterAirCleanDe "Driver assistance computer (primary): sw413 left repeater air clean degraded";
CM_ SG_ 1513 APP_sw413_rightRepeaterAirCleanD "Driver assistance computer (primary): sw413 right repeater air clean degraded";
CM_ SG_ 1513 APP_sw413_backupAirCleanDegraded "Driver assistance computer (primary): sw413 backup air clean degraded";
CM_ SG_ 1513 APP_sw413_fasciaAirCleanDegraded "Driver assistance computer (primary): sw413 fascia air clean degraded";
CM_ SG_ 1513 APP_sw413_leftRepeaterFluid_0001 "Driver assistance computer (primary): sw413 left repeater fluid clean degraded";
CM_ SG_ 1513 APP_sw413_rightRepeaterFlui_0001 "Driver assistance computer (primary): sw413 right repeater fluid clean degraded";
CM_ SG_ 1513 APP_sw413_backupFluidCleanDegrad "Driver assistance computer (primary): sw413 backup fluid clean degraded";
CM_ SG_ 1513 APP_sw413_fasciaFluidCleanDegrad "Driver assistance computer (primary): sw413 fascia fluid clean degraded";
CM_ SG_ 1513 APP_sw413_leftRepeaterAirCleanCr "Driver assistance computer (primary): sw413 left repeater air clean critical";
CM_ SG_ 1513 APP_sw413_rightRepeaterAirCleanC "Driver assistance computer (primary): sw413 right repeater air clean critical";
CM_ SG_ 1513 APP_sw413_backupAirCleanCritical "Driver assistance computer (primary): sw413 backup air clean critical";
CM_ SG_ 1513 APP_sw413_fasciaAirCleanCritical "Driver assistance computer (primary): sw413 fascia air clean critical";
CM_ SG_ 1513 APP_sw413_leftRepeaterFluidClean "Driver assistance computer (primary): sw413 left repeater fluid clean critical";
CM_ SG_ 1513 APP_sw413_rightRepeaterFluidClea "Driver assistance computer (primary): sw413 right repeater fluid clean critical";
CM_ SG_ 1513 APP_sw413_backupFluidCleanCritic "Driver assistance computer (primary): sw413 backup fluid clean critical";
CM_ SG_ 1513 APP_sw413_fasciaFluidCleanCritic "Driver assistance computer (primary): sw413 fascia fluid clean critical";
CM_ SG_ 1513 APP_sw413_cabinCamFanRpmFault "Driver assistance computer (primary): sw413 cabin cam fan rpm fault";
CM_ SG_ 1513 APP_sw413_gnssPpsMIA "Driver assistance computer (primary): sw413 gnss pps MIA";
CM_ SG_ 1513 APP_sw413_camDayOffgassingPreAle "Driver assistance computer (primary): sw413 cam day offgassing pre alert";
CM_ SG_ 1513 APP_sw413_fluidCleaningStatusMia "Driver assistance computer (primary): sw413 fluid cleaning status mia";
CM_ SG_ 1513 APP_sw413_airCleaningStatusMia "Driver assistance computer (primary): sw413 air cleaning status mia";
CM_ SG_ 1513 APP_sw415_reason1 "Driver assistance computer (primary): sw415 reason1";
CM_ SG_ 1513 APP_sw415_reason2 "Driver assistance computer (primary): sw415 reason2";
CM_ SG_ 1513 APP_sw415_reason3 "Driver assistance computer (primary): sw415 reason3";
CM_ SG_ 1513 APP_sw416_reason1 "Driver assistance computer (primary): sw416 reason1";
CM_ SG_ 1513 APP_sw416_reason2 "Driver assistance computer (primary): sw416 reason2";
CM_ SG_ 1513 APP_sw416_reason3 "Driver assistance computer (primary): sw416 reason3";
CM_ SG_ 1513 APP_sw416_safeStateManeuver "Driver assistance computer (primary): sw416 safe state maneuver";
CM_ SG_ 1513 APP_sw417_reason1 "Driver assistance computer (primary): sw417 reason1";
CM_ SG_ 1513 APP_sw417_reason2 "Driver assistance computer (primary): sw417 reason2";
CM_ SG_ 1513 APP_sw417_reason3 "Driver assistance computer (primary): sw417 reason3";
CM_ SG_ 1513 APP_sw418_reason1 "Driver assistance computer (primary): sw418 reason1";
CM_ SG_ 1513 APP_sw418_reason2 "Driver assistance computer (primary): sw418 reason2";
CM_ SG_ 1513 APP_sw418_reason3 "Driver assistance computer (primary): sw418 reason3";
CM_ SG_ 1513 APP_sw418_safeStateManeuver "Driver assistance computer (primary): sw418 safe state maneuver";
CM_ SG_ 1513 APP_sw419_reason1 "Driver assistance computer (primary): sw419 reason1";
CM_ SG_ 1513 APP_sw419_reason2 "Driver assistance computer (primary): sw419 reason2";
CM_ SG_ 1513 APP_sw419_reason3 "Driver assistance computer (primary): sw419 reason3";
CM_ SG_ 1513 APP_sw420_reason1 "Driver assistance computer (primary): sw420 reason1";
CM_ SG_ 1513 APP_sw420_reason2 "Driver assistance computer (primary): sw420 reason2";
CM_ SG_ 1513 APP_sw420_reason3 "Driver assistance computer (primary): sw420 reason3";
CM_ SG_ 1513 APP_sw420_safeStateManeuver "Driver assistance computer (primary): sw420 safe state maneuver";
CM_ SG_ 1513 APP_sw421_reason1 "Driver assistance computer (primary): sw421 reason1";
CM_ SG_ 1513 APP_sw421_reason2 "Driver assistance computer (primary): sw421 reason2";
CM_ SG_ 1513 APP_sw421_reason3 "Driver assistance computer (primary): sw421 reason3";
CM_ SG_ 1513 APP_sw422_reason1 "Driver assistance computer (primary): sw422 reason1";
CM_ SG_ 1513 APP_sw422_reason2 "Driver assistance computer (primary): sw422 reason2";
CM_ SG_ 1513 APP_sw422_reason3 "Driver assistance computer (primary): sw422 reason3";
CM_ SG_ 1513 APP_sw422_safeStateManeuver "Driver assistance computer (primary): sw422 safe state maneuver";
CM_ SG_ 1513 APP_sw423_type "Driver assistance computer (primary): sw423 type";
CM_ SG_ 1513 APP_sw424_type "Driver assistance computer (primary): sw424 type";
CM_ SG_ 1513 APP_sw425_type "Driver assistance computer (primary): sw425 type";
CM_ SG_ 1513 APP_sw426_type "Driver assistance computer (primary): sw426 type";
CM_ SG_ 1513 APP_sw427_type "Driver assistance computer (primary): sw427 type";
CM_ SG_ 1513 APP_sw428_type "Driver assistance computer (primary): sw428 type";
CM_ SG_ 1513 APP_sw429_type "Driver assistance computer (primary): sw429 type";
CM_ SG_ 1513 APP_sw433_currentCameraIsAeroRib "Driver assistance computer (primary): sw433 current camera is aero rib from eeprom";
CM_ SG_ 1513 APP_sw433_currentCameraAeroRibIn "Driver assistance computer (primary): sw433 current camera aero rib info from gtw";
CM_ SG_ 1513 APP_sw433_previousCameraIsAeroRi "Driver assistance computer (primary): sw433 previous camera is aero rib from eeprom";
CM_ SG_ 1513 APP_sw433_previousCameraAeroRibI "Driver assistance computer (primary): sw433 previous camera aero rib info from gtw";
CM_ SG_ 1513 APP_sw434_currentCameraIsAeroRib "Driver assistance computer (primary): sw434 current camera is aero rib from eeprom";
CM_ SG_ 1513 APP_sw434_currentCameraAeroRibIn "Driver assistance computer (primary): sw434 current camera aero rib info from gtw";
CM_ SG_ 1513 APP_sw434_previousCameraIsAeroRi "Driver assistance computer (primary): sw434 previous camera is aero rib from eeprom";
CM_ SG_ 1513 APP_sw434_previousCameraAeroRibI "Driver assistance computer (primary): sw434 previous camera aero rib info from gtw";
CM_ SG_ 1513 APP_sw443_configuredImagerModelN "Driver assistance computer (primary): sw443 configured imager model number";
CM_ SG_ 1513 APP_sw443_detectedImagerModelNum "Driver assistance computer (primary): sw443 detected imager model number";
CM_ SG_ 1513 APP_sw444_configuredImagerModelN "Driver assistance computer (primary): sw444 configured imager model number";
CM_ SG_ 1513 APP_sw444_detectedImagerModelNum "Driver assistance computer (primary): sw444 detected imager model number";
CM_ SG_ 1513 APP_sw445_configuredImagerModelN "Driver assistance computer (primary): sw445 configured imager model number";
CM_ SG_ 1513 APP_sw445_detectedImagerModelNum "Driver assistance computer (primary): sw445 detected imager model number";
CM_ SG_ 1513 APP_sw446_configuredImagerModelN "Driver assistance computer (primary): sw446 configured imager model number";
CM_ SG_ 1513 APP_sw446_detectedImagerModelNum "Driver assistance computer (primary): sw446 detected imager model number";
CM_ SG_ 1513 APP_sw447_configuredImagerModelN "Driver assistance computer (primary): sw447 configured imager model number";
CM_ SG_ 1513 APP_sw447_detectedImagerModelNum "Driver assistance computer (primary): sw447 detected imager model number";
CM_ SG_ 1513 APP_sw448_configuredImagerModelN "Driver assistance computer (primary): sw448 configured imager model number";
CM_ SG_ 1513 APP_sw448_detectedImagerModelNum "Driver assistance computer (primary): sw448 detected imager model number";
CM_ SG_ 1513 APP_sw449_configuredImagerModelN "Driver assistance computer (primary): sw449 configured imager model number";
CM_ SG_ 1513 APP_sw449_detectedImagerModelNum "Driver assistance computer (primary): sw449 detected imager model number";
CM_ SG_ 1513 APP_sw450_configuredImagerModelN "Driver assistance computer (primary): sw450 configured imager model number";
CM_ SG_ 1513 APP_sw450_detectedImagerModelNum "Driver assistance computer (primary): sw450 detected imager model number";
CM_ SG_ 1513 APP_sw451_configuredImagerModelN "Driver assistance computer (primary): sw451 configured imager model number";
CM_ SG_ 1513 APP_sw451_detectedImagerModelNum "Driver assistance computer (primary): sw451 detected imager model number";
CM_ SG_ 1513 APP_sw452_configuredImagerModelN "Driver assistance computer (primary): sw452 configured imager model number";
CM_ SG_ 1513 APP_sw452_detectedImagerModelNum "Driver assistance computer (primary): sw452 detected imager model number";
CM_ SG_ 1513 APP_sw454_reason1 "Driver assistance computer (primary): sw454 reason1";
CM_ SG_ 1513 APP_sw455_reason1 "Driver assistance computer (primary): sw455 reason1";
CM_ SG_ 1513 APP_sw456_reason1 "Driver assistance computer (primary): sw456 reason1";
CM_ SG_ 1513 APP_sw456_reason2 "Driver assistance computer (primary): sw456 reason2";
CM_ SG_ 1513 APP_sw456_reason3 "Driver assistance computer (primary): sw456 reason3";
CM_ SG_ 1513 APP_sw457_reason1 "Driver assistance computer (primary): sw457 reason1";
CM_ SG_ 1513 APP_sw457_reason2 "Driver assistance computer (primary): sw457 reason2";
CM_ SG_ 1513 APP_sw457_reason3 "Driver assistance computer (primary): sw457 reason3";
CM_ SG_ 1513 APP_sw457_safeStateManeuver "Driver assistance computer (primary): sw457 safe state maneuver";
CM_ SG_ 1513 APP_sw458_fsdCollisionValue "Driver assistance computer (primary): sw458 fsd collision value";
CM_ SG_ 1513 APP_sw458_aebCollisionValue "Driver assistance computer (primary): sw458 aeb collision value";
CM_ SG_ 1513 APP_sw458_aebDurationAtAceOnset "Driver assistance computer (primary): sw458 aeb duration at ace onset";
CM_ SG_ 1513 APP_sw458_targetDistance "Driver assistance computer (primary): sw458 target distance";
CM_ SG_ 1513 APP_sw458_targetRelativeSpeed "Driver assistance computer (primary): sw458 target relative speed";
CM_ SG_ 1513 APP_sw458_egoVehicleSpeed "Driver assistance computer (primary): sw458 ego vehicle speed";
CM_ SG_ 1513 APP_sw459_status "Driver assistance computer (primary): sw459 status";
CM_ SG_ 1513 APP_sw460_status "Driver assistance computer (primary): sw460 status";
CM_ SG_ 1513 APP_sw461_rerouteRequest "Driver assistance computer (primary): sw461 reroute request";
CM_ SG_ 1513 APP_sw461_rerouteReason "Driver assistance computer (primary): sw461 reroute reason";
CM_ SG_ 1513 APP_sw465_reason1 "Driver assistance computer (primary): sw465 reason1";
CM_ SG_ 1513 APP_sw465_reason2 "Driver assistance computer (primary): sw465 reason2";
CM_ SG_ 1513 APP_sw465_reason3 "Driver assistance computer (primary): sw465 reason3";
CM_ SG_ 1513 APP_sw465_safeStateManeuver "Driver assistance computer (primary): sw465 safe state maneuver";
CM_ BO_ 1045 "Driver assistance computer (primary) message: backup dash cam status";
CM_ SG_ 1045 APP_backupDashCamFeedGood "Indicates if the backup dash cam stream is healthy.";
CM_ SG_ 1045 APP_backupDashCamFrameRate "The backup dash cam frame rate.";
CM_ BO_ 1020 "Driver assistance computer (primary) message: board temperatures";
CM_ SG_ 1020 APP_decisionTemperature "Rolling average of Parker and Pascal temperature.";
CM_ SG_ 1020 APP_pascalTemperature "Temperature of Autopilot GPU";
CM_ SG_ 1020 APP_parkerATemperature "Temperature of Autopilot CPU(1)";
CM_ SG_ 1020 APP_parkerBTemperature "Temperature of Autopilot CPU(1)";
CM_ SG_ 1020 APP_pascalExtTemperature "External temperature of Autopilot GPU";
CM_ SG_ 1020 APP_parkerExtTemperature "External temperature of Parker";
CM_ SG_ 1020 APP_pascalHeaterDecision "Pascal heater descision on/off";
CM_ BO_ 2046 "Driver assistance computer (primary) message: cam calibration status";
CM_ SG_ 2046 APP_cameraPosition "Driver assistance computer (primary): camera position";
CM_ SG_ 2046 APP_mainCamExtPitchCal "The calibration, pitch or yaw offset of a camera";
CM_ SG_ 2046 APP_mainCamExtYawCal "The calibration, pitch or yaw offset of a camera";
CM_ SG_ 2046 APP_mainCalibTime "Driver assistance computer (primary): main calib time";
CM_ SG_ 2046 APP_mainCalibProgress "The percent progress of the main camera calibration.";
CM_ SG_ 2046 APP_mainCalibrated "Whether or not the main camera is calibrated.";
CM_ SG_ 2046 APP_narrowCamExtPitchCal "The calibration, pitch or yaw offset of a camera";
CM_ SG_ 2046 APP_narrowCamExtYawCal "The calibration, pitch or yaw offset of a camera";
CM_ SG_ 2046 APP_narrowCalibTime "Driver assistance computer (primary): narrow calib time";
CM_ SG_ 2046 APP_narrowCalibProgress "The percent progress of the narrow camera calibration.";
CM_ SG_ 2046 APP_narrowCalibrated "Whether or not the narrow camera is calibrated.";
CM_ SG_ 2046 APP_fisheyeCamExtPitchCal "The calibration, pitch or yaw offset of a camera";
CM_ SG_ 2046 APP_fisheyeCamExtYawCal "The calibration, pitch or yaw offset of a camera";
CM_ SG_ 2046 APP_fisheyeCalibTime "Driver assistance computer (primary): fisheye calib time";
CM_ SG_ 2046 APP_fisheyeCalibProgress "The percent progress of the fisheye camera calibration.";
CM_ SG_ 2046 APP_fisheyeCalibrated "Whether or not the fisheye camera is calibrated.";
CM_ SG_ 2046 APP_lPillarCamExtPitchCal "The calibration, pitch or yaw offset of a camera";
CM_ SG_ 2046 APP_lPillarCamExtYawCal "The calibration, pitch or yaw offset of a camera";
CM_ SG_ 2046 APP_lPillarCalibTime "Driver assistance computer (primary): l pillar calib time";
CM_ SG_ 2046 APP_lPillarCalibProgress "The percent progress of the left pillar camera calibration.";
CM_ SG_ 2046 APP_lPillarCalibrated "Whether or not the left pillar camera is calibrated.";
CM_ SG_ 2046 APP_rPillarCamExtPitchCal "The calibration, pitch or yaw offset of a camera";
CM_ SG_ 2046 APP_rPillarCamExtYawCal "The calibration, pitch or yaw offset of a camera";
CM_ SG_ 2046 APP_rPillarCalibTime "Driver assistance computer (primary): r pillar calib time";
CM_ SG_ 2046 APP_rPillarCalibProgress "The percent progress of the right pillar camera calibration.";
CM_ SG_ 2046 APP_rPillarCalibrated "Whether or not the right pillar camera is calibrated.";
CM_ SG_ 2046 APP_lRepeatCamExtPitchCal "The calibration, pitch or yaw offset of a camera";
CM_ SG_ 2046 APP_lRepeatCamExtYawCal "The calibration, pitch or yaw offset of a camera";
CM_ SG_ 2046 APP_lRepeatCalibTime "Driver assistance computer (primary): l repeat calib time";
CM_ SG_ 2046 APP_lRepeatCalibProgress "The percent progress of the left repeater camera calibration.";
CM_ SG_ 2046 APP_lRepeatCalibrated "Whether or not the left repeater camera is calibrated.";
CM_ SG_ 2046 APP_rRepeatCamExtPitchCal "The calibration, pitch or yaw offset of a camera";
CM_ SG_ 2046 APP_rRepeatCamExtYawCal "The calibration, pitch or yaw offset of a camera";
CM_ SG_ 2046 APP_rRepeatCalibTime "Driver assistance computer (primary): r repeat calib time";
CM_ SG_ 2046 APP_rRepeatCalibProgress "The percent progress of the right repeater camera calibration.";
CM_ SG_ 2046 APP_rRepeatCalibrated "Whether or not the right repeater camera is calibrated.";
CM_ SG_ 2046 APP_backupCamExtPitchCal "The calibration, pitch or yaw offset of a camera";
CM_ SG_ 2046 APP_backupCamExtYawCal "The calibration, pitch or yaw offset of a camera";
CM_ SG_ 2046 APP_backupCalibTime "Driver assistance computer (primary): backup calib time";
CM_ SG_ 2046 APP_backupCalibProgress "The percent progress of the backup calibration.";
CM_ SG_ 2046 APP_backupCalibrated "Whether or not the backup camera is calibrated.";
CM_ SG_ 2046 APP_fasciaCamExtPitchCal "The calibration, pitch or yaw offset of a camera";
CM_ SG_ 2046 APP_fasciaCamExtYawCal "The calibration, pitch or yaw offset of a camera";
CM_ SG_ 2046 APP_fasciaCalibTime "Driver assistance computer (primary): fascia calib time";
CM_ SG_ 2046 APP_fasciaCalibProgress "The percent progress of the fascia calibration.";
CM_ SG_ 2046 APP_fasciaCalibrated "Whether or not the fascia camera is calibrated.";
CM_ BO_ 1018 "Driver assistance computer (primary) message: camera lux";
CM_ SG_ 1018 APP_mainCameraLUX "Amount of illuminance seen by the main camera";
CM_ SG_ 1018 APP_narrowCameraLUX "Driver assistance computer (primary): narrow camera LUX";
CM_ SG_ 1018 APP_fisheyeCameraLUX "Driver assistance computer (primary): fisheye camera LUX";
CM_ SG_ 1018 APP_lRepeatCameraLUX "Driver assistance computer (primary): l repeat camera LUX";
CM_ SG_ 1018 APP_rRepeatCameraLUX "Driver assistance computer (primary): r repeat camera LUX";
CM_ SG_ 1018 APP_lPillarCameraLUX "Driver assistance computer (primary): l pillar camera LUX";
CM_ SG_ 1018 APP_rPillarCameraLUX "Driver assistance computer (primary): r pillar camera LUX";
CM_ SG_ 1018 APP_backupCameraLUX "Driver assistance computer (primary): backup camera LUX";
CM_ BO_ 1040 "Driver assistance computer (primary) message: camera status";
CM_ SG_ 1040 APP_backupCameraFeedGood "Indicates if the backup camera stream is healthy.";
CM_ SG_ 1040 APP_backupCameraFrameRate "The backup camera frame rate.";
CM_ SG_ 1040 APP_cameraBlockedFrontMain "Indicates that a blockage was detected by the main forward camera.";
CM_ SG_ 1040 APP_cameraBlockedFrontFisheye "Indicates that a blockage was detected by the fisheye camera.";
CM_ SG_ 1040 APP_cameraBlockedFrontNarrow "Indicates that a blockage was detected by the narrow camera.";
CM_ SG_ 1040 APP_cameraBlockedLeftPillar "Indicates that a blockage was detected by the left pillar camera.";
CM_ SG_ 1040 APP_cameraBlockedLeftRepeater "Indicates that a blockage was detected by the left repeater camera.";
CM_ SG_ 1040 APP_cameraBlockedRightPillar "Indicates that a blockage was detected by the right pillar camera.";
CM_ SG_ 1040 APP_cameraBlockedRightRepeater "Indicates that a blockage was detected by the right repeater camera.";
CM_ SG_ 1040 APP_cameraBlockedBackup "Indicates that a blockage was detected by the backup camera.";
CM_ SG_ 1040 APP_fasciaCameraTemperature "Die temperature of camera image sensor";
CM_ BO_ 1043 "Driver assistance computer (primary) message: dash cam status";
CM_ SG_ 1043 APP_mainDashCamFeedGood "Indicates if the main dash cam stream is healthy.";
CM_ SG_ 1043 APP_mainDashCamFrameRate "The main dash cam frame rate.";
CM_ SG_ 1043 APP_lRepeatDashCamFeedGood "Indicates if the left repeater dash cam stream is healthy.";
CM_ SG_ 1043 APP_lRepeatDashCamFrameRate "The left repeater dash cam frame rate.";
CM_ SG_ 1043 APP_rRepeatDashCamFeedGood "Indicates if the right repeater dash cam stream is healthy.";
CM_ SG_ 1043 APP_rRepeatDashCamFrameRate "The right repeater dash cam frame rate.";
CM_ BO_ 2045 "Driver assistance computer (primary) message: defog info message";
CM_ SG_ 2045 APP_cameraDefogMode "Instructs SGK to activate or deactivate cameras when the vehicle is in a parked state.";
CM_ SG_ 2045 APP_selfieCamFanRpm "Indicates the selfie camera fan rpm.";
CM_ SG_ 2045 APP_forceDefroster "Force Front Defroster mode instructs VC to activate defog/defrost when AP detects dew/fog.";
CM_ SG_ 2045 APP_checkThermalSysHealth "Driver assistance computer (primary): check thermal sys health";
CM_ SG_ 2045 APP_defogInfoMessageChecksum "Driver assistance computer (primary): defog info message checksum";
CM_ SG_ 2045 APP_hvacRequest "Das request to turn on HVAC";
CM_ BO_ 939 "Driver assistance computer (primary) message: driver monitor status";
CM_ SG_ 939 APP_cabinCamTelemetryOn "Driver assistance computer (primary): cabin cam telemetry on";
CM_ SG_ 939 APP_attnMonitorVersion "Driver assistance computer (primary): attn monitor version";
CM_ SG_ 939 APP_attnBasedDriverMonitorOn "Indicates whether attention based Driver Monitor is currently enabled during Autosteer/Full Self-Driving (FSD).";
CM_ SG_ 939 APP_handsOnDetected "Indicates whether Driver Monitor detects that a user has their hands on the wheel during Autosteer/Full Self-Driving (FSD).";
CM_ SG_ 939 APP_handsOnDetectedSource "Reports the source of the hands on detection output from driver monitor.";
CM_ SG_ 939 APP_cabinCamBlinded "Indicates that the cabin camera is detected as blinded.";
CM_ SG_ 939 APP_cabinCamDark "Indicates that the cabin camera is detected as dark.";
CM_ SG_ 939 APP_driverStateUnknown "Indicates that the cabin camera detects the driver state as unknown.";
CM_ SG_ 939 APP_driverNotLively "Reports that the cabin camera detects the driver as not lively.";
CM_ SG_ 939 APP_driverStateUnknownHyst "Indicates that the cabin camera detects the driver state as unknown, with a logging lag to reduce excess signal noise by briefly indicating 'unknown' even if 'unknown' is no longer detected.";
CM_ SG_ 939 APP_driverLowNominal "Indicates that the cabin camera detects the driver's forward eye gaze is low.";
CM_ SG_ 939 APP_driverHeadCappedHyst "Indicates that the cabin camera detects a driver head obstruction.";
CM_ SG_ 939 APP_driverSunglassesUseHyst "Indicates that the cabin camera detects driver is wearing sunglasses.";
CM_ SG_ 939 APP_cabinLowLux "Indicates that the cabin camera detects cabin illumination is low.";
CM_ SG_ 939 APP_cabinCamInconsistent "Indicates that Driver Monitor detects inconsistencies in cabin camera network signals.";
CM_ SG_ 939 APP_driverLeaningBack "Indicates that the cabin camera detects driver may be leaning back and not ready to take over.";
CM_ SG_ 939 APP_driverLowEyeVisibility "Indicates that the cabin camera detects degraded driver eye visibility.";
CM_ SG_ 939 APP_driverHandsNotReady "Indicates that the cabin camera detects driver hands may not be near steering wheel/yoke.";
CM_ SG_ 939 APP_driverSeatUnoccupied "Reports that the cabin camera detects that driver seat may not be occupied.";
CM_ SG_ 939 APP_handsOnInputRequired "Indicates that driver monitoring requires driver hands-on acknowledgement.";
CM_ SG_ 939 APP_cabinCamDarkHyst "Indicates that the cabin camera is detected as dark, with a logging lag to reduce excess signal noise by briefly indicating 'dark' even if 'dark' is no longer detected.";
CM_ SG_ 939 APP_cabinLowLuxHyst "Indicates that the cabin camera detects cabin illumination low, with a logging lag to reduce excess signal noise by briefly indicating 'low' even if 'low' is no longer detected.";
CM_ SG_ 939 APP_ADDWSystemStatus "Reports the Advanced Distracted Driver Warning (ADDW) system status.";
CM_ SG_ 939 APP_dmStrictness "Driver assistance computer (primary): dm strictness";
CM_ SG_ 939 APP_dmStrictnessReason "Driver assistance computer (primary): dm strictness reason";
CM_ BO_ 603 "Driver assistance computer (primary) message: environment";
CM_ SG_ 603 APP_environmentRainy "Driver assistance computer (primary): environment rainy";
CM_ SG_ 603 APP_environmentSnowy "Driver assistance computer (primary): environment snowy";
CM_ SG_ 603 APP_offgassingSeverity "Driver assistance computer (primary): offgassing severity";
CM_ SG_ 603 APP_offgassingDetectionState "Driver assistance computer (primary): offgassing detection state";
CM_ SG_ 603 APP_offgassingAlertEnabled "Driver assistance computer (primary): offgassing alert enabled";
CM_ SG_ 603 APP_offgassingMaxProbabilityLong "Driver assistance computer (primary): offgassing max probability long";
CM_ SG_ 603 APP_offgassingMaxProbabilityShor "Driver assistance computer (primary): offgassing max probability short";
CM_ SG_ 603 APP_offgassingLongMaxCamera "Driver assistance computer (primary): offgassing long max camera";
CM_ SG_ 603 APP_offgassingShortMaxCamera "Driver assistance computer (primary): offgassing short max camera";
CM_ SG_ 603 APP_offgassingLongMaxDetector "Driver assistance computer (primary): offgassing long max detector";
CM_ SG_ 603 APP_offgassingShortMaxDetector "Driver assistance computer (primary): offgassing short max detector";
CM_ BO_ 1061 "Driver assistance computer (primary) message: factory summon goal";
CM_ SG_ 1061 APP_factoryGoalLatitude "Driver assistance computer (primary): factory goal latitude";
CM_ SG_ 1061 APP_factoryGoalLongitude "Driver assistance computer (primary): factory goal longitude";
CM_ SG_ 1061 APP_factoryGoalSpeed "Driver assistance computer (primary): factory goal speed";
CM_ BO_ 843 "Driver assistance computer (primary) message: front park assist data";
CM_ SG_ 843 APP_frontLeftParkAssist "Driver assistance computer (primary): front left park assist";
CM_ SG_ 843 APP_frontLeftMiddleParkAssist "Driver assistance computer (primary): front left middle park assist";
CM_ SG_ 843 APP_frontMiddleParkAssist "Driver assistance computer (primary): front middle park assist";
CM_ SG_ 843 APP_frontRightMiddleParkAssist "Driver assistance computer (primary): front right middle park assist";
CM_ SG_ 843 APP_frontRightParkAssist "Driver assistance computer (primary): front right park assist";
CM_ SG_ 843 APP_parkAssistStatus "Driver assistance computer (primary): park assist status";
CM_ SG_ 843 APP_useParkDistancesFromAP "Driver assistance computer (primary): use park distances from AP";
CM_ BO_ 1353 "Driver assistance computer (primary) message: info";
CM_ SG_ 1353 APP_infoIndex "Driver assistance computer (primary): info index";
CM_ SG_ 1353 APP_buildType "Driver assistance computer (primary): build type";
CM_ BO_ 907 "Driver assistance computer (primary) message: rear park assist data";
CM_ SG_ 907 APP_rearLeftParkAssist "Driver assistance computer (primary): rear left park assist";
CM_ SG_ 907 APP_rearLeftMiddleParkAssist "Driver assistance computer (primary): rear left middle park assist";
CM_ SG_ 907 APP_rearMiddleParkAssist "Driver assistance computer (primary): rear middle park assist";
CM_ SG_ 907 APP_rearRightMiddleParkAssist "Driver assistance computer (primary): rear right middle park assist";
CM_ SG_ 907 APP_rearRightParkAssist "Driver assistance computer (primary): rear right park assist";
CM_ BO_ 601 "Driver assistance computer (primary) message: status";
CM_ SG_ 601 APP_watchdogState "State of system watchdog on ParkerB";
CM_ SG_ 601 APP_fusedState "Driver assistance computer (primary): fused state";
CM_ SG_ 601 APP_cameraHeaterRequest "Indicates if heater grid is active because of request from AP cameras.";
CM_ SG_ 601 APP_factorySummonStatus "Driver assistance computer (primary): factory summon status";
CM_ SG_ 601 APP_clipRecordingStatus "Driver assistance computer (primary): clip recording status";
CM_ SG_ 601 APP_allowApActivationWithBrake "Indicates whether Autopilot (AP) activation while brake pressed is allowed.";
CM_ SG_ 601 APP_summonUnavailableReason "The reason why smart summon is currently unavailable.";
CM_ SG_ 601 APP_fsdSuspendState "If FSD feature is suspended on this car";
CM_ SG_ 601 APP_fsdRevokeStrikeoutCount "Reports the number of strikeouts counted towards revoking Full Self-Driving (FSD) feature.";
CM_ SG_ 601 APP_teslaVisionSupported "Whether autopilot can support tesla vision";
CM_ SG_ 601 APP_teslaVisionUnsupportedReason "Reason for vehicle not supporting tesla vision";
CM_ SG_ 601 APP_fsdRevokeCount "Reports the number of times the car has had Full Self-Driving (FSD) revoked.";
CM_ SG_ 601 APP_excessiveAccelPedalWarning "Indicates that driver is using acceleration pedal continously and excessively";
CM_ SG_ 601 APP_unifiedObjectStackSupported "Whether autopilot can support unified objects stack for tesla vision";
CM_ SG_ 601 APP_sendingBUCStream "Indicates if the backup camera stream is being sent to the Media Control Unit (MCU) from Turbo A.";
CM_ SG_ 601 APP_DDAWSystemStatus "DDAW system status";
CM_ SG_ 601 APP_socOperatingMode "Operating Mode of the SOC";
CM_ SG_ 601 APP_summonVersionIdentifier "Driver assistance computer (primary): summon version identifier";
CM_ SG_ 601 APP_sentryState "Reports the Sentry mode state on Gen. 4 Hardware (HW4) and later vehicles.";
CM_ SG_ 601 APP_autoparkVersionIdentifier "Driver assistance computer (primary): autopark version identifier";
CM_ SG_ 601 APP_autonomySystemHealth "Driver assistance computer (primary): autonomy system health";
CM_ SG_ 601 APP_uiEthFailoverDisabled "Driver assistance computer (primary): ui eth failover disabled";
CM_ SG_ 601 APP_suspendResumeAvailable "Driver assistance computer (primary): suspend resume available";
CM_ SG_ 601 APP_statusCounter "Driver assistance computer (primary): status counter";
CM_ SG_ 601 APP_statusChecksum "Driver assistance computer (primary): status checksum";
CM_ BO_ 605 "Driver assistance computer (primary) message: traffic control";
CM_ SG_ 605 APP_tcFeatureState "The feature level state of stopping for traffic controls";
CM_ SG_ 605 APP_tcStateMachine "The traffic control state machine's internal control state.";
CM_ SG_ 605 APP_tcControlSource "The input data source for the traffic control object";
CM_ SG_ 605 APP_tcControlType "The specific type of traffic control, note not all are control worthy.";
CM_ SG_ 605 APP_tcControlDistance "The distance to the nearest critical traffic control object.";
CM_ SG_ 605 APP_tcControlLightState "Driver assistance computer (primary): tc control light state";
CM_ SG_ 605 APP_tcContinuationReason "The reason the traffic control state machine entered the continue state.";
CM_ SG_ 605 APP_tcConfirmationType "The mechanism of how the driver confirmed the traffic control.";
CM_ SG_ 605 APP_tcWarningSuppressionReason "The suppression reason for the traffic control warning feature.";
CM_ SG_ 605 APP_tcUnavailableReason "The reason why the traffic control feature is currently unavailable.";
CM_ SG_ 605 APP_tcVisionLight "Whether or not the traffic light has a vision measurement.";
CM_ SG_ 605 APP_tcVisionSign "Whether or not the traffic sign has a vision measurement.";
CM_ SG_ 605 APP_tcVisionRoadMarking "Whether or not the road marking has a vision measurement.";
CM_ SG_ 605 APP_tcVisionLine "Whether or not the traffic control line has a vision measurement.";
CM_ BO_ 859 "Driver assistance computer (primary) message: vision ocs status";
CM_ SG_ 859 APP_visionOcsStatusChecksum "Driver assistance computer (primary): vision ocs status checksum";
CM_ SG_ 859 APP_visionOcsStateRaw "Reports classification state raw signal for front passenger from interior camera.";
CM_ SG_ 859 APP_visionOcsEmptyProbRaw "Driver assistance computer (primary): vision ocs empty prob raw";
CM_ SG_ 859 APP_visionOcsChildProbRaw "Driver assistance computer (primary): vision ocs child prob raw";
CM_ SG_ 859 APP_visionOcsAdultProbRaw "Driver assistance computer (primary): vision ocs adult prob raw";
CM_ SG_ 859 APP_visionOcsFrontPasClsVisionSt "Reports classification state of front passenger seat after Bayesian filter.";
CM_ SG_ 859 APP_visionOcsStatusCounter "Driver assistance computer (primary): vision ocs status counter";
CM_ BO_ 809 "Driver assistance computer (primary) message: warning matrix0";
CM_ SG_ 809 APP_w001_DEPRECATED "Driver assistance computer (primary): w001 DEPRECATED";
CM_ SG_ 809 APP_w002_ldwDisabled "Driver assistance computer (primary): w002 ldw disabled";
CM_ SG_ 809 APP_w003_isaDisabled "Driver assistance computer (primary): w003 isa disabled";
CM_ SG_ 809 APP_w004_accDisabled "Driver assistance computer (primary): w004 acc disabled";
CM_ SG_ 809 APP_w005_fcwCancelled "Driver assistance computer (primary): w005 fcw cancelled";
CM_ SG_ 809 APP_w006_aebCancelled "Driver assistance computer (primary): w006 aeb cancelled";
CM_ SG_ 809 APP_w007_ahlbDisabled "Driver assistance computer (primary): w007 ahlb disabled";
CM_ SG_ 809 APP_w008_parkDisabled "Driver assistance computer (primary): w008 park disabled";
CM_ SG_ 809 APP_w009_aebFault "Driver assistance computer (primary): w009 aeb fault";
CM_ SG_ 809 APP_w010_radcCalibIssue "Driver assistance computer (primary): w010 radc calib issue";
CM_ SG_ 809 APP_w011_scaEvent "Driver assistance computer (primary): w011 sca event";
CM_ SG_ 809 APP_w012_Cam_BootFailure "Driver assistance computer (primary): w012 cam boot failure";
CM_ SG_ 809 APP_w013_Cam_Watchdog "Driver assistance computer (primary): w013 cam watchdog";
CM_ SG_ 809 APP_w014_swAssert "Driver assistance computer (primary): w014 sw assert";
CM_ SG_ 809 APP_w015_Camera_Failsafes "Driver assistance computer (primary): w015 camera failsafes";
CM_ SG_ 809 APP_w016_aeb_e_event "Driver assistance computer (primary): w016 aeb e event";
CM_ SG_ 809 APP_w017_Cam_Msg_MIA "Driver assistance computer (primary): w017 cam msg MIA";
CM_ SG_ 809 APP_w018_ECU_Power_Issue "Driver assistance computer (primary): w018 ECU power issue";
CM_ SG_ 809 APP_w019_ECU_Stack_Overflow "Driver assistance computer (primary): w019 ECU stack overflow";
CM_ SG_ 809 APP_w020_ECU_checkstopError "Driver assistance computer (primary): w020 ECU checkstop error";
CM_ SG_ 809 APP_w021_ECU_Temperature_Issue "Driver assistance computer (primary): w021 ECU temperature issue";
CM_ SG_ 809 APP_w022_ECU_EEPROM_Failure "Driver assistance computer (primary): w022 ECU EEPROM failure";
CM_ SG_ 809 APP_w023_ECU_Cam_Statemismatc "Driver assistance computer (primary): w023 ECU cam statemismatc";
CM_ SG_ 809 APP_w024_ECU_Watchdog_Reset "Driver assistance computer (primary): w024 ECU watchdog reset";
CM_ SG_ 809 APP_w025_LC_Steering_Override "Driver assistance computer (primary): w025 LC steering override";
CM_ SG_ 809 APP_w026_ECU_timingIssue "Driver assistance computer (primary): w026 ECU timing issue";
CM_ SG_ 809 APP_w027_ECU_Reset_Fault "Driver assistance computer (primary): w027 ECU reset fault";
CM_ SG_ 809 APP_w028_spi_rx_error "Driver assistance computer (primary): w028 spi rx error";
CM_ SG_ 809 APP_w029_spi_tx_error "Driver assistance computer (primary): w029 spi tx error";
CM_ SG_ 809 APP_w030_Heater_Issue "Driver assistance computer (primary): w030 heater issue";
CM_ SG_ 809 APP_w031_canRxError "Driver assistance computer (primary): w031 can rx error";
CM_ SG_ 809 APP_w032_canTxError "Driver assistance computer (primary): w032 can tx error";
CM_ SG_ 809 APP_w033_gtwMia "Driver assistance computer (primary): w033 gtw mia";
CM_ SG_ 809 APP_w034_sccmMia "Driver assistance computer (primary): w034 sccm mia";
CM_ SG_ 809 APP_w035_espMia "Driver assistance computer (primary): w035 esp mia";
CM_ SG_ 809 APP_w036_bdyMia "Driver assistance computer (primary): w036 bdy mia";
CM_ SG_ 809 APP_w037_camTacIssue "Driver assistance computer (primary): w037 cam tac issue";
CM_ SG_ 809 APP_w038_camFailure "Driver assistance computer (primary): w038 cam failure";
CM_ SG_ 809 APP_w039_sdm_rcm_Mia "Driver assistance computer (primary): w039 sdm rcm mia";
CM_ SG_ 809 APP_w040_autopilotAngleSaturated "Driver assistance computer (primary): w040 autopilot angle saturated";
CM_ SG_ 809 APP_w041_autopilotRateSaturated "Driver assistance computer (primary): w041 autopilot rate saturated";
CM_ SG_ 809 APP_w042_autopilotAborting "Driver assistance computer (primary): w042 autopilot aborting";
CM_ SG_ 809 APP_w043_camLongRunTime "Driver assistance computer (primary): w043 cam long run time";
CM_ SG_ 809 APP_w044_appMobileyeFailure "Driver assistance computer (primary): w044 app mobileye failure";
CM_ SG_ 809 APP_w045_radMia "Driver assistance computer (primary): w045 rad mia";
CM_ SG_ 809 APP_w046_eepromRecordAbsent "Driver assistance computer (primary): w046 eeprom record absent";
CM_ SG_ 809 APP_w047_edrEvent "Driver assistance computer (primary): w047 edr event";
CM_ SG_ 809 APP_w048_APP_Features_Disabled "Driver assistance computer (primary): w048 APP features disabled";
CM_ SG_ 809 APP_w049_eyeqVersionMismatch "Driver assistance computer (primary): w049 eyeq version mismatch";
CM_ SG_ 809 APP_w050_aeb_event "Driver assistance computer (primary): w050 aeb event";
CM_ SG_ 809 APP_w051_radcEcuIssue "Driver assistance computer (primary): w051 radc ecu issue";
CM_ SG_ 809 APP_w052_radcSensorIssue "Driver assistance computer (primary): w052 radc sensor issue";
CM_ SG_ 809 APP_w053_radcCommIssue "Driver assistance computer (primary): w053 radc comm issue";
CM_ SG_ 809 APP_w054_camAutofix "Driver assistance computer (primary): w054 cam autofix";
CM_ SG_ 809 APP_w055_radcVersionMismatch "Driver assistance computer (primary): w055 radc version mismatch";
CM_ SG_ 809 APP_w056_diMia "Driver assistance computer (primary): w056 di mia";
CM_ SG_ 809 APP_w057_mcuMia "Driver assistance computer (primary): w057 mcu mia";
CM_ SG_ 809 APP_w058_epbMia "Driver assistance computer (primary): w058 epb mia";
CM_ SG_ 809 APP_w059_parkMia "Driver assistance computer (primary): w059 park mia";
CM_ SG_ 809 APP_w060_fcw_event "Driver assistance computer (primary): w060 fcw event";
CM_ SG_ 809 APP_w061_airSuspensionMia "Driver assistance computer (primary): w061 air suspension mia";
CM_ SG_ 809 APP_w062_radcAlignment "Driver assistance computer (primary): w062 radc alignment";
CM_ SG_ 809 APP_w063_parkVersionMismatch "Driver assistance computer (primary): w063 park version mismatch";
CM_ SG_ 809 APP_w064_epasMia "Driver assistance computer (primary): w064 epas mia";
CM_ BO_ 873 "Driver assistance computer (primary) message: warning matrix1";
CM_ SG_ 873 APP_w065_deserializerOvercurrent "Driver assistance computer (primary): w065 deserializer overcurrent";
CM_ SG_ 873 APP_w066_deserializerLockLost "Driver assistance computer (primary): w066 deserializer lock lost";
CM_ SG_ 873 APP_w067_steeringAlignment "Driver assistance computer (primary): w067 steering alignment";
CM_ SG_ 873 APP_w068_vlInconsistency "Driver assistance computer (primary): w068 vl inconsistency";
CM_ SG_ 873 APP_w069_apcSpaceMasked "Driver assistance computer (primary): w069 apc space masked";
CM_ SG_ 873 APP_w070_apcIncompleteCal "Driver assistance computer (primary): w070 apc incomplete cal";
CM_ SG_ 873 APP_w071_selfparkStarted "Driver assistance computer (primary): w071 selfpark started";
CM_ SG_ 873 APP_w072_selfparkComplete "Driver assistance computer (primary): w072 selfpark complete";
CM_ SG_ 873 APP_w073_issueEscalatedLDW "Driver assistance computer (primary): w073 issue escalated LDW";
CM_ SG_ 873 APP_w074_inPathStationaryObst "Driver assistance computer (primary): w074 in path stationary obst";
CM_ SG_ 873 APP_w075_scMia "Driver assistance computer (primary): w075 sc mia";
CM_ SG_ 873 APP_w076_mobilEyeSetC "Driver assistance computer (primary): w076 mobil eye set c";
CM_ SG_ 873 APP_w077_pmmActive "Driver assistance computer (primary): w077 pmm active";
CM_ SG_ 873 APP_w078_pmmActive2 "Driver assistance computer (primary): w078 pmm active2";
CM_ SG_ 873 APP_w079_edrAvailable "Driver assistance computer (primary): w079 edr available";
CM_ SG_ 873 APP_w080_accFailedActivation "Driver assistance computer (primary): w080 acc failed activation";
CM_ SG_ 873 APP_w081_pmmActiveBraking "Driver assistance computer (primary): w081 pmm active braking";
CM_ SG_ 873 APP_w082_inPathFSviolation "Driver assistance computer (primary): w082 in path f sviolation";
CM_ SG_ 873 APP_w083_inPathRADObject "Driver assistance computer (primary): w083 in path RAD object";
CM_ SG_ 873 APP_w084_pmmIPSO "Driver assistance computer (primary): w084 pmm IPSO";
CM_ SG_ 873 APP_w085_pmmSteering "Driver assistance computer (primary): w085 pmm steering";
CM_ SG_ 873 APP_w086_robCollision "Driver assistance computer (primary): w086 rob collision";
CM_ SG_ 873 APP_w087_DEPRECATED "Driver assistance computer (primary): w087 DEPRECATED";
CM_ SG_ 873 APP_w088_DEPRECATED "Driver assistance computer (primary): w088 DEPRECATED";
CM_ SG_ 873 APP_w089_DEPRECATED "Driver assistance computer (primary): w089 DEPRECATED";
CM_ SG_ 873 APP_w090_DEPRECATED "Driver assistance computer (primary): w090 DEPRECATED";
CM_ SG_ 873 APP_w091_DEPRECATED "Driver assistance computer (primary): w091 DEPRECATED";
CM_ SG_ 873 APP_w092_DEPRECATED "Driver assistance computer (primary): w092 DEPRECATED";
CM_ SG_ 873 APP_w093_DEPRECATED "Driver assistance computer (primary): w093 DEPRECATED";
CM_ SG_ 873 APP_w094_DEPRECATED "Driver assistance computer (primary): w094 DEPRECATED";
CM_ SG_ 873 APP_w095_DEPRECATED "Driver assistance computer (primary): w095 DEPRECATED";
CM_ SG_ 873 APP_w096_DEPRECATED "Driver assistance computer (primary): w096 DEPRECATED";
CM_ SG_ 873 APP_w097_DEPRECATED "Driver assistance computer (primary): w097 DEPRECATED";
CM_ SG_ 873 APP_w098_DEPRECATED "Driver assistance computer (primary): w098 DEPRECATED";
CM_ SG_ 873 APP_w099_DEPRECATED "Driver assistance computer (primary): w099 DEPRECATED";
CM_ SG_ 873 APP_w100_DEPRECATED "Driver assistance computer (primary): w100 DEPRECATED";
CM_ SG_ 873 APP_w101_DEPRECATED "Driver assistance computer (primary): w101 DEPRECATED";
CM_ SG_ 873 APP_w102_DEPRECATED "Driver assistance computer (primary): w102 DEPRECATED";
CM_ SG_ 873 APP_w103_robExperimentalAEB "Driver assistance computer (primary): w103 rob experimental AEB";
CM_ SG_ 873 APP_w104_DEPRECATED "Driver assistance computer (primary): w104 DEPRECATED";
CM_ SG_ 873 APP_w105_DEPRECATED "Driver assistance computer (primary): w105 DEPRECATED";
CM_ SG_ 873 APP_w106_torsionBarOffset "Driver assistance computer (primary): w106 torsion bar offset";
BA_DEF_ BO_ "GenMsgCycleTime" INT 0 3600000;
BA_DEF_ BO_ "GenMsgSendType" ENUM "Cyclic","NotUsed","NotUsed","NotUsed","NotUsed","NotUsed","NotUsed","IfActive","NoMsgSendType","NotUsed";
BA_DEF_ BO_ "VFrameFormat" ENUM "StandardCAN","ExtendedCAN","reserved","J1939PG","reserved","reserved","reserved","reserved","reserved","reserved","reserved","reserved","reserved","reserved","StandardCAN_FD","ExtendedCAN_FD";
BA_DEF_ BO_ "CANFD_BRS" ENUM "0","1";
BA_DEF_ SG_ "SystemSignalLongSymbol" STRING;
BA_DEF_ SG_ "Confidence" ENUM "layout-only","plausible","validated";
BA_DEF_DEF_ "GenMsgCycleTime" 0;
BA_DEF_DEF_ "GenMsgSendType" "NoMsgSendType";
BA_DEF_DEF_ "VFrameFormat" "StandardCAN";
BA_DEF_DEF_ "CANFD_BRS" "1";
BA_DEF_DEF_ "SystemSignalLongSymbol" "";
BA_DEF_DEF_ "Confidence" "layout-only";
BA_ "SystemSignalLongSymbol" SG_ 1513 APP_sw357_cabinCameraFailsafeAct "APP_sw357_cabinCameraFailsafeActive";
BA_ "SystemSignalLongSymbol" SG_ 1513 APP_sw357_invalidDrowsinessPredi "APP_sw357_invalidDrowsinessPredictions";
BA_ "SystemSignalLongSymbol" SG_ 1513 APP_sw357_invalidSccmSteeringAng "APP_sw357_invalidSccmSteeringAngle";
BA_ "SystemSignalLongSymbol" SG_ 1513 APP_sw357_invalidSccmSteeri_0001 "APP_sw357_invalidSccmSteeringAngleRate";
BA_ "SystemSignalLongSymbol" SG_ 1513 APP_sw357_poorFrontCameraVisibil "APP_sw357_poorFrontCameraVisibility";
BA_ "SystemSignalLongSymbol" SG_ 1513 APP_sw357_electricalFaultForMain "APP_sw357_electricalFaultForMainCam";
BA_ "SystemSignalLongSymbol" SG_ 1513 APP_sw357_electricalFaultForCabi "APP_sw357_electricalFaultForCabinCam";
BA_ "SystemSignalLongSymbol" SG_ 1513 APP_sw357_mainCameraFailsafeActi "APP_sw357_mainCameraFailsafeActive";
BA_ "SystemSignalLongSymbol" SG_ 1513 APP_sw357_electricalFaultForFish "APP_sw357_electricalFaultForFisheyeCam";
BA_ "SystemSignalLongSymbol" SG_ 1513 APP_sw357_fisheyeCameraFailsafeA "APP_sw357_fisheyeCameraFailsafeActive";
BA_ "SystemSignalLongSymbol" SG_ 1513 APP_sw358_mainCameraStreamUnavai "APP_sw358_mainCameraStreamUnavailable";
BA_ "SystemSignalLongSymbol" SG_ 1513 APP_sw358_fisheyeCameraStreamUna "APP_sw358_fisheyeCameraStreamUnavailable";
BA_ "SystemSignalLongSymbol" SG_ 1513 APP_sw407_apPowerRequestNotNomin "APP_sw407_apPowerRequestNotNominal";
BA_ "SystemSignalLongSymbol" SG_ 1513 APP_sw407_gnssDegradedSignalStre "APP_sw407_gnssDegradedSignalStrength";
BA_ "SystemSignalLongSymbol" SG_ 1513 APP_sw407_cameraVisionFailsafeBe "APP_sw407_cameraVisionFailsafeBeforeActivation";
BA_ "SystemSignalLongSymbol" SG_ 1513 APP_sw407_severeFrontVisionOcclu "APP_sw407_severeFrontVisionOcclusion";
BA_ "SystemSignalLongSymbol" SG_ 1513 APP_sw407_severeLeftVisionOcclus "APP_sw407_severeLeftVisionOcclusion";
BA_ "SystemSignalLongSymbol" SG_ 1513 APP_sw407_severeRightVisionOcclu "APP_sw407_severeRightVisionOcclusion";
BA_ "SystemSignalLongSymbol" SG_ 1513 APP_sw407_severeReverseVisionOcc "APP_sw407_severeReverseVisionOcclusion";
BA_ "SystemSignalLongSymbol" SG_ 1513 APP_sw407_frequentVisionOcclusio "APP_sw407_frequentVisionOcclusion";
BA_ "SystemSignalLongSymbol" SG_ 1513 APP_sw407_fasciaVisionOcclusionA "APP_sw407_fasciaVisionOcclusionAtStop";
BA_ "SystemSignalLongSymbol" SG_ 1513 APP_sw407_epasDriverlessModeNotA "APP_sw407_epasDriverlessModeNotActive";
BA_ "SystemSignalLongSymbol" SG_ 1513 APP_sw407_epasSystemTorqueReduce "APP_sw407_epasSystemTorqueReduced";
BA_ "SystemSignalLongSymbol" SG_ 1513 APP_sw407_extendedComputeInactiv "APP_sw407_extendedComputeInactive";
BA_ "SystemSignalLongSymbol" SG_ 1513 APP_sw407_epbRedundantBrakingSta "APP_sw407_epbRedundantBrakingStatus";
BA_ "SystemSignalLongSymbol" SG_ 1513 APP_sw407_vehicleAutonomyBehavio "APP_sw407_vehicleAutonomyBehaviorMismatch";
BA_ "SystemSignalLongSymbol" SG_ 1513 APP_sw408_controllerSolverFailur "APP_sw408_controllerSolverFailure";
BA_ "SystemSignalLongSymbol" SG_ 1513 APP_sw408_controllerSolverDegrad "APP_sw408_controllerSolverDegraded";
BA_ "SystemSignalLongSymbol" SG_ 1513 APP_sw408_controllerSolverCritic "APP_sw408_controllerSolverCritical";
BA_ "SystemSignalLongSymbol" SG_ 1513 APP_sw408_rideshareIngressNoNavR "APP_sw408_rideshareIngressNoNavRoute";
BA_ "SystemSignalLongSymbol" SG_ 1513 APP_sw408_incompatibleSystemHeal "APP_sw408_incompatibleSystemHealth";
BA_ "SystemSignalLongSymbol" SG_ 1513 APP_sw408_singleSocHealthyExcept "APP_sw408_singleSocHealthyException";
BA_ "SystemSignalLongSymbol" SG_ 1513 APP_sw408_systemUnhealthyDevOver "APP_sw408_systemUnhealthyDevOverride";
BA_ "SystemSignalLongSymbol" SG_ 1513 APP_sw408_passengerUnbuckledActi "APP_sw408_passengerUnbuckledActiveRide";
BA_ "SystemSignalLongSymbol" SG_ 1513 APP_sw408_chargeCableConnectedOr "APP_sw408_chargeCableConnectedOrStatusUnknown";
BA_ "SystemSignalLongSymbol" SG_ 1513 APP_sw408_fleetMaintenanceRequir "APP_sw408_fleetMaintenanceRequired";
BA_ "SystemSignalLongSymbol" SG_ 1513 APP_sw408_visionCabinOccupancyUn "APP_sw408_visionCabinOccupancyUnavailable";
BA_ "SystemSignalLongSymbol" SG_ 1513 APP_sw408_elevatedTirePressureRe "APP_sw408_elevatedTirePressureReading";
BA_ "SystemSignalLongSymbol" SG_ 1513 APP_sw408_tirePressureHardWarnin "APP_sw408_tirePressureHardWarning";
BA_ "SystemSignalLongSymbol" SG_ 1513 APP_sw408_epbParkingAvailability "APP_sw408_epbParkingAvailabilityFaulted";
BA_ "SystemSignalLongSymbol" SG_ 1513 APP_sw408_epbParkingAvailab_0002 "APP_sw408_epbParkingAvailabilitySpeedInvalid";
BA_ "SystemSignalLongSymbol" SG_ 1513 APP_sw408_epbParkingAvailab_0001 "APP_sw408_epbParkingAvailabilityRequestPathDegraded";
BA_ "SystemSignalLongSymbol" SG_ 1513 APP_sw408_epbParkingAvailab_0003 "APP_sw408_epbParkingAvailabilityUnknown";
BA_ "SystemSignalLongSymbol" SG_ 1513 APP_sw408_diBrakingDecelerationU "APP_sw408_diBrakingDecelerationUnavailable";
BA_ "SystemSignalLongSymbol" SG_ 1513 APP_sw408_apRedundancyUnavailabl "APP_sw408_apRedundancyUnavailable";
BA_ "SystemSignalLongSymbol" SG_ 1513 APP_sw408_lowBeamLightFaultedInL "APP_sw408_lowBeamLightFaultedInLowVis";
BA_ "SystemSignalLongSymbol" SG_ 1513 APP_sw408_highBeamLightFaultedIn "APP_sw408_highBeamLightFaultedInLowVis";
BA_ "SystemSignalLongSymbol" SG_ 1513 APP_sw408_allTailLightsFaultedIn "APP_sw408_allTailLightsFaultedInLowVis";
BA_ "SystemSignalLongSymbol" SG_ 1513 APP_sw409_windshieldCamHeaterFau "APP_sw409_windshieldCamHeaterFault";
BA_ "SystemSignalLongSymbol" SG_ 1513 APP_sw409_leftPillarCamHeaterFau "APP_sw409_leftPillarCamHeaterFault";
BA_ "SystemSignalLongSymbol" SG_ 1513 APP_sw409_rightPillarCamHeaterFa "APP_sw409_rightPillarCamHeaterFault";
BA_ "SystemSignalLongSymbol" SG_ 1513 APP_sw409_redundantBrakePathActi "APP_sw409_redundantBrakePathActive";
BA_ "SystemSignalLongSymbol" SG_ 1513 APP_sw409_redundantBrakesNotRead "APP_sw409_redundantBrakesNotReady";
BA_ "SystemSignalLongSymbol" SG_ 1513 APP_sw409_redundantBrakesNotArme "APP_sw409_redundantBrakesNotArmed";
BA_ "SystemSignalLongSymbol" SG_ 1513 APP_sw409_redundantBrakesRedunda "APP_sw409_redundantBrakesRedundancyLost";
BA_ "SystemSignalLongSymbol" SG_ 1513 APP_sw409_redundantBrakesFailOpe "APP_sw409_redundantBrakesFailOperational";
BA_ "SystemSignalLongSymbol" SG_ 1513 APP_sw409_seatbeltStatusUnhealth "APP_sw409_seatbeltStatusUnhealthy";
BA_ "SystemSignalLongSymbol" SG_ 1513 APP_sw409_seatOccupancyStatusUnh "APP_sw409_seatOccupancyStatusUnhealthy";
BA_ "SystemSignalLongSymbol" SG_ 1513 APP_sw409_poorLocalizationAccura "APP_sw409_poorLocalizationAccuracy";
BA_ "SystemSignalLongSymbol" SG_ 1513 APP_sw409_diChassisControlCanMes "APP_sw409_diChassisControlCanMessageMia";
BA_ "SystemSignalLongSymbol" SG_ 1513 APP_sw409_diSystemStatusCanMessa "APP_sw409_diSystemStatusCanMessagesMia";
BA_ "SystemSignalLongSymbol" SG_ 1513 APP_sw409_parkBrakeCanMessagesMi "APP_sw409_parkBrakeCanMessagesMia";
BA_ "SystemSignalLongSymbol" SG_ 1513 APP_sw409_driverNotPresentPreAct "APP_sw409_driverNotPresentPreActivation";
BA_ "SystemSignalLongSymbol" SG_ 1513 APP_sw409_passengerUnexpectedRid "APP_sw409_passengerUnexpectedRideInactive";
BA_ "SystemSignalLongSymbol" SG_ 1513 APP_sw409_waitingForPassengerEgr "APP_sw409_waitingForPassengerEgress";
BA_ "SystemSignalLongSymbol" SG_ 1513 APP_sw409_unassignedPassengerUnb "APP_sw409_unassignedPassengerUnbuckled";
BA_ "SystemSignalLongSymbol" SG_ 1513 APP_sw409_notAuthenticatedForDri "APP_sw409_notAuthenticatedForDrive";
BA_ "SystemSignalLongSymbol" SG_ 1513 APP_sw409_cameraRedundancyNotRea "APP_sw409_cameraRedundancyNotReady";
BA_ "SystemSignalLongSymbol" SG_ 1513 APP_sw409_autonomousBehaviorsTas "APP_sw409_autonomousBehaviorsTaskSuspending";
BA_ "SystemSignalLongSymbol" SG_ 1513 APP_sw409_cameraPreconditioningI "APP_sw409_cameraPreconditioningIncomplete";
BA_ "SystemSignalLongSymbol" SG_ 1513 APP_sw409_safetyOperatorNotPrese "APP_sw409_safetyOperatorNotPresent";
BA_ "SystemSignalLongSymbol" SG_ 1513 APP_sw409_unsupervisedRtNotAllow "APP_sw409_unsupervisedRtNotAllowed";
BA_ "SystemSignalLongSymbol" SG_ 1513 APP_sw409_driverPresentNotAllowe "APP_sw409_driverPresentNotAllowed";
BA_ "SystemSignalLongSymbol" SG_ 1513 APP_sw409_apThermalDegradedBlock "APP_sw409_apThermalDegradedBlockActivation";
BA_ "SystemSignalLongSymbol" SG_ 1513 APP_sw409_apThermalDegradedPullo "APP_sw409_apThermalDegradedPulloverReq";
BA_ "SystemSignalLongSymbol" SG_ 1513 APP_sw409_autonomousBehaviorsLin "APP_sw409_autonomousBehaviorsLinkNotEstablished";
BA_ "SystemSignalLongSymbol" SG_ 1513 APP_sw410_autonomyControllingAnd "APP_sw410_autonomyControllingAndNotParked";
BA_ "SystemSignalLongSymbol" SG_ 1513 APP_sw410_missionPlannerDesiredB "APP_sw410_missionPlannerDesiredBehaviorNotE2e";
BA_ "SystemSignalLongSymbol" SG_ 1513 APP_sw410_arbiterSelectedBehavio "APP_sw410_arbiterSelectedBehaviorNotE2e";
BA_ "SystemSignalLongSymbol" SG_ 1513 APP_sw410_arbiterSelectedBe_0001 "APP_sw410_arbiterSelectedBehaviorOutOfDate";
BA_ "SystemSignalLongSymbol" SG_ 1513 APP_sw410_peerVisionFailoverActi "APP_sw410_peerVisionFailoverActive";
BA_ "SystemSignalLongSymbol" SG_ 1513 APP_sw410_apsSingleCameraPowerFa "APP_sw410_apsSingleCameraPowerFailure";
BA_ "SystemSignalLongSymbol" SG_ 1513 APP_sw410_apsDualCameraPowerFail "APP_sw410_apsDualCameraPowerFailure";
BA_ "SystemSignalLongSymbol" SG_ 1513 APP_sw410_anyLvHealthCanMessageM "APP_sw410_anyLvHealthCanMessageMia";
BA_ "SystemSignalLongSymbol" SG_ 1513 APP_sw410_anyLvHealthCanMessageI "APP_sw410_anyLvHealthCanMessageInvalid";
BA_ "SystemSignalLongSymbol" SG_ 1513 APP_sw410_uiHealthStatusCanMessa "APP_sw410_uiHealthStatusCanMessageMia";
BA_ "SystemSignalLongSymbol" SG_ 1513 APP_sw410_gtwCarConfigCanMessage "APP_sw410_gtwCarConfigCanMessageMia";
BA_ "SystemSignalLongSymbol" SG_ 1513 APP_sw410_vcleftDoorStatusCanMes "APP_sw410_vcleftDoorStatusCanMessageMia";
BA_ "SystemSignalLongSymbol" SG_ 1513 APP_sw410_vcrightDoorStatusCanMe "APP_sw410_vcrightDoorStatusCanMessageMia";
BA_ "SystemSignalLongSymbol" SG_ 1513 APP_sw410_anyLeftDoorOpenButtonF "APP_sw410_anyLeftDoorOpenButtonFaulted";
BA_ "SystemSignalLongSymbol" SG_ 1513 APP_sw410_anyRightDoorOpenButton "APP_sw410_anyRightDoorOpenButtonFaulted";
BA_ "SystemSignalLongSymbol" SG_ 1513 APP_sw410_sgkAutonomyStateNotInS "APP_sw410_sgkAutonomyStateNotInSync";
BA_ "SystemSignalLongSymbol" SG_ 1513 APP_sw410_apThermalModelFaultDet "APP_sw410_apThermalModelFaultDetected";
BA_ "SystemSignalLongSymbol" SG_ 1513 APP_sw410_wheelSpeedsCanMessageM "APP_sw410_wheelSpeedsCanMessageMia";
BA_ "SystemSignalLongSymbol" SG_ 1513 APP_sw410_allWheelSpeedsSensorsF "APP_sw410_allWheelSpeedsSensorsFaulted";
BA_ "SystemSignalLongSymbol" SG_ 1513 APP_sw410_diAutonomyHealthCanMes "APP_sw410_diAutonomyHealthCanMessageMia";
BA_ "SystemSignalLongSymbol" SG_ 1513 APP_sw410_devPulloverOverrideAct "APP_sw410_devPulloverOverrideActive";
BA_ "SystemSignalLongSymbol" SG_ 1513 APP_sw410_cabinCameraIrLedFaulte "APP_sw410_cabinCameraIrLedFaulted";
BA_ "SystemSignalLongSymbol" SG_ 1513 APP_sw410_selfNetworkDecryptionN "APP_sw410_selfNetworkDecryptionNotReady";
BA_ "SystemSignalLongSymbol" SG_ 1513 APP_sw410_uiCenterDisplayUnavail "APP_sw410_uiCenterDisplayUnavailable";
BA_ "SystemSignalLongSymbol" SG_ 1513 APP_sw410_uiConnectivityHwUnheal "APP_sw410_uiConnectivityHwUnhealthy";
BA_ "SystemSignalLongSymbol" SG_ 1513 APP_sw413_apSystemIssuePendingRe "APP_sw413_apSystemIssuePendingReboot";
BA_ "SystemSignalLongSymbol" SG_ 1513 APP_sw413_diVelocityEstimatorSta "APP_sw413_diVelocityEstimatorStateDegraded";
BA_ "SystemSignalLongSymbol" SG_ 1513 APP_sw413_noVehicleSpeedSourceAv "APP_sw413_noVehicleSpeedSourceAvailable";
BA_ "SystemSignalLongSymbol" SG_ 1513 APP_sw413_secondaryWasherFluidLo "APP_sw413_secondaryWasherFluidLow";
BA_ "SystemSignalLongSymbol" SG_ 1513 APP_sw413_leftRepeaterAirCleanDe "APP_sw413_leftRepeaterAirCleanDegraded";
BA_ "SystemSignalLongSymbol" SG_ 1513 APP_sw413_rightRepeaterAirCleanD "APP_sw413_rightRepeaterAirCleanDegraded";
BA_ "SystemSignalLongSymbol" SG_ 1513 APP_sw413_leftRepeaterFluid_0001 "APP_sw413_leftRepeaterFluidCleanDegraded";
BA_ "SystemSignalLongSymbol" SG_ 1513 APP_sw413_rightRepeaterFlui_0001 "APP_sw413_rightRepeaterFluidCleanDegraded";
BA_ "SystemSignalLongSymbol" SG_ 1513 APP_sw413_backupFluidCleanDegrad "APP_sw413_backupFluidCleanDegraded";
BA_ "SystemSignalLongSymbol" SG_ 1513 APP_sw413_fasciaFluidCleanDegrad "APP_sw413_fasciaFluidCleanDegraded";
BA_ "SystemSignalLongSymbol" SG_ 1513 APP_sw413_leftRepeaterAirCleanCr "APP_sw413_leftRepeaterAirCleanCritical";
BA_ "SystemSignalLongSymbol" SG_ 1513 APP_sw413_rightRepeaterAirCleanC "APP_sw413_rightRepeaterAirCleanCritical";
BA_ "SystemSignalLongSymbol" SG_ 1513 APP_sw413_leftRepeaterFluidClean "APP_sw413_leftRepeaterFluidCleanCritical";
BA_ "SystemSignalLongSymbol" SG_ 1513 APP_sw413_rightRepeaterFluidClea "APP_sw413_rightRepeaterFluidCleanCritical";
BA_ "SystemSignalLongSymbol" SG_ 1513 APP_sw413_backupFluidCleanCritic "APP_sw413_backupFluidCleanCritical";
BA_ "SystemSignalLongSymbol" SG_ 1513 APP_sw413_fasciaFluidCleanCritic "APP_sw413_fasciaFluidCleanCritical";
BA_ "SystemSignalLongSymbol" SG_ 1513 APP_sw413_camDayOffgassingPreAle "APP_sw413_camDayOffgassingPreAlert";
BA_ "SystemSignalLongSymbol" SG_ 1513 APP_sw433_currentCameraIsAeroRib "APP_sw433_currentCameraIsAeroRibFromEeprom";
BA_ "SystemSignalLongSymbol" SG_ 1513 APP_sw433_currentCameraAeroRibIn "APP_sw433_currentCameraAeroRibInfoFromGtw";
BA_ "SystemSignalLongSymbol" SG_ 1513 APP_sw433_previousCameraIsAeroRi "APP_sw433_previousCameraIsAeroRibFromEeprom";
BA_ "SystemSignalLongSymbol" SG_ 1513 APP_sw433_previousCameraAeroRibI "APP_sw433_previousCameraAeroRibInfoFromGtw";
BA_ "SystemSignalLongSymbol" SG_ 1513 APP_sw434_currentCameraIsAeroRib "APP_sw434_currentCameraIsAeroRibFromEeprom";
BA_ "SystemSignalLongSymbol" SG_ 1513 APP_sw434_currentCameraAeroRibIn "APP_sw434_currentCameraAeroRibInfoFromGtw";
BA_ "SystemSignalLongSymbol" SG_ 1513 APP_sw434_previousCameraIsAeroRi "APP_sw434_previousCameraIsAeroRibFromEeprom";
BA_ "SystemSignalLongSymbol" SG_ 1513 APP_sw434_previousCameraAeroRibI "APP_sw434_previousCameraAeroRibInfoFromGtw";
BA_ "SystemSignalLongSymbol" SG_ 1513 APP_sw443_configuredImagerModelN "APP_sw443_configuredImagerModelNumber";
BA_ "SystemSignalLongSymbol" SG_ 1513 APP_sw443_detectedImagerModelNum "APP_sw443_detectedImagerModelNumber";
BA_ "SystemSignalLongSymbol" SG_ 1513 APP_sw444_configuredImagerModelN "APP_sw444_configuredImagerModelNumber";
BA_ "SystemSignalLongSymbol" SG_ 1513 APP_sw444_detectedImagerModelNum "APP_sw444_detectedImagerModelNumber";
BA_ "SystemSignalLongSymbol" SG_ 1513 APP_sw445_configuredImagerModelN "APP_sw445_configuredImagerModelNumber";
BA_ "SystemSignalLongSymbol" SG_ 1513 APP_sw445_detectedImagerModelNum "APP_sw445_detectedImagerModelNumber";
BA_ "SystemSignalLongSymbol" SG_ 1513 APP_sw446_configuredImagerModelN "APP_sw446_configuredImagerModelNumber";
BA_ "SystemSignalLongSymbol" SG_ 1513 APP_sw446_detectedImagerModelNum "APP_sw446_detectedImagerModelNumber";
BA_ "SystemSignalLongSymbol" SG_ 1513 APP_sw447_configuredImagerModelN "APP_sw447_configuredImagerModelNumber";
BA_ "SystemSignalLongSymbol" SG_ 1513 APP_sw447_detectedImagerModelNum "APP_sw447_detectedImagerModelNumber";
BA_ "SystemSignalLongSymbol" SG_ 1513 APP_sw448_configuredImagerModelN "APP_sw448_configuredImagerModelNumber";
BA_ "SystemSignalLongSymbol" SG_ 1513 APP_sw448_detectedImagerModelNum "APP_sw448_detectedImagerModelNumber";
BA_ "SystemSignalLongSymbol" SG_ 1513 APP_sw449_configuredImagerModelN "APP_sw449_configuredImagerModelNumber";
BA_ "SystemSignalLongSymbol" SG_ 1513 APP_sw449_detectedImagerModelNum "APP_sw449_detectedImagerModelNumber";
BA_ "SystemSignalLongSymbol" SG_ 1513 APP_sw450_configuredImagerModelN "APP_sw450_configuredImagerModelNumber";
BA_ "SystemSignalLongSymbol" SG_ 1513 APP_sw450_detectedImagerModelNum "APP_sw450_detectedImagerModelNumber";
BA_ "SystemSignalLongSymbol" SG_ 1513 APP_sw451_configuredImagerModelN "APP_sw451_configuredImagerModelNumber";
BA_ "SystemSignalLongSymbol" SG_ 1513 APP_sw451_detectedImagerModelNum "APP_sw451_detectedImagerModelNumber";
BA_ "SystemSignalLongSymbol" SG_ 1513 APP_sw452_configuredImagerModelN "APP_sw452_configuredImagerModelNumber";
BA_ "SystemSignalLongSymbol" SG_ 1513 APP_sw452_detectedImagerModelNum "APP_sw452_detectedImagerModelNumber";
BA_ "Confidence" SG_ 1045 APP_backupDashCamFeedGood 1;
BA_ "Confidence" SG_ 1045 APP_backupDashCamFrameRate 1;
BA_ "Confidence" SG_ 1020 APP_decisionTemperature 1;
BA_ "Confidence" SG_ 1020 APP_pascalTemperature 1;
BA_ "Confidence" SG_ 1020 APP_parkerATemperature 1;
BA_ "Confidence" SG_ 1020 APP_parkerBTemperature 1;
BA_ "Confidence" SG_ 1020 APP_pascalExtTemperature 1;
BA_ "Confidence" SG_ 1020 APP_parkerExtTemperature 1;
BA_ "Confidence" SG_ 1020 APP_pascalHeaterDecision 1;
BA_ "Confidence" SG_ 2046 APP_mainCamExtPitchCal 1;
BA_ "Confidence" SG_ 2046 APP_mainCamExtYawCal 1;
BA_ "Confidence" SG_ 2046 APP_mainCalibTime 1;
BA_ "Confidence" SG_ 2046 APP_mainCalibProgress 1;
BA_ "Confidence" SG_ 2046 APP_mainCalibrated 1;
BA_ "Confidence" SG_ 2046 APP_narrowCamExtPitchCal 1;
BA_ "Confidence" SG_ 2046 APP_narrowCamExtYawCal 1;
BA_ "Confidence" SG_ 2046 APP_narrowCalibTime 1;
BA_ "Confidence" SG_ 2046 APP_narrowCalibProgress 1;
BA_ "Confidence" SG_ 2046 APP_narrowCalibrated 1;
BA_ "Confidence" SG_ 2046 APP_fisheyeCamExtPitchCal 1;
BA_ "Confidence" SG_ 2046 APP_fisheyeCamExtYawCal 1;
BA_ "Confidence" SG_ 2046 APP_fisheyeCalibTime 1;
BA_ "Confidence" SG_ 2046 APP_fisheyeCalibProgress 1;
BA_ "Confidence" SG_ 2046 APP_fisheyeCalibrated 1;
BA_ "Confidence" SG_ 2046 APP_lPillarCamExtPitchCal 1;
BA_ "Confidence" SG_ 2046 APP_lPillarCamExtYawCal 1;
BA_ "Confidence" SG_ 2046 APP_lPillarCalibTime 1;
BA_ "Confidence" SG_ 2046 APP_lPillarCalibProgress 1;
BA_ "Confidence" SG_ 2046 APP_lPillarCalibrated 1;
BA_ "Confidence" SG_ 2046 APP_rPillarCamExtPitchCal 1;
BA_ "Confidence" SG_ 2046 APP_rPillarCamExtYawCal 1;
BA_ "Confidence" SG_ 2046 APP_rPillarCalibTime 1;
BA_ "Confidence" SG_ 2046 APP_rPillarCalibProgress 1;
BA_ "Confidence" SG_ 2046 APP_rPillarCalibrated 1;
BA_ "Confidence" SG_ 2046 APP_lRepeatCamExtPitchCal 1;
BA_ "Confidence" SG_ 2046 APP_lRepeatCamExtYawCal 1;
BA_ "Confidence" SG_ 2046 APP_lRepeatCalibTime 1;
BA_ "Confidence" SG_ 2046 APP_lRepeatCalibProgress 1;
BA_ "Confidence" SG_ 2046 APP_lRepeatCalibrated 1;
BA_ "Confidence" SG_ 2046 APP_rRepeatCamExtPitchCal 1;
BA_ "Confidence" SG_ 2046 APP_rRepeatCamExtYawCal 1;
BA_ "Confidence" SG_ 2046 APP_rRepeatCalibTime 1;
BA_ "Confidence" SG_ 2046 APP_rRepeatCalibProgress 1;
BA_ "Confidence" SG_ 2046 APP_rRepeatCalibrated 1;
BA_ "Confidence" SG_ 2046 APP_backupCamExtPitchCal 1;
BA_ "Confidence" SG_ 2046 APP_backupCamExtYawCal 1;
BA_ "Confidence" SG_ 2046 APP_backupCalibTime 1;
BA_ "Confidence" SG_ 2046 APP_backupCalibProgress 1;
BA_ "Confidence" SG_ 2046 APP_backupCalibrated 1;
BA_ "Confidence" SG_ 2046 APP_fasciaCamExtPitchCal 1;
BA_ "Confidence" SG_ 2046 APP_fasciaCamExtYawCal 1;
BA_ "Confidence" SG_ 2046 APP_fasciaCalibTime 1;
BA_ "Confidence" SG_ 2046 APP_fasciaCalibProgress 1;
BA_ "Confidence" SG_ 2046 APP_fasciaCalibrated 1;
BA_ "Confidence" SG_ 1018 APP_mainCameraLUX 1;
BA_ "Confidence" SG_ 1018 APP_narrowCameraLUX 1;
BA_ "Confidence" SG_ 1018 APP_fisheyeCameraLUX 1;
BA_ "Confidence" SG_ 1018 APP_lRepeatCameraLUX 1;
BA_ "Confidence" SG_ 1018 APP_rRepeatCameraLUX 1;
BA_ "Confidence" SG_ 1018 APP_lPillarCameraLUX 1;
BA_ "Confidence" SG_ 1018 APP_rPillarCameraLUX 1;
BA_ "Confidence" SG_ 1018 APP_backupCameraLUX 1;
BA_ "Confidence" SG_ 1040 APP_backupCameraFeedGood 1;
BA_ "Confidence" SG_ 1040 APP_backupCameraFrameRate 1;
BA_ "Confidence" SG_ 1040 APP_cameraBlockedFrontMain 1;
BA_ "Confidence" SG_ 1040 APP_cameraBlockedFrontFisheye 1;
BA_ "Confidence" SG_ 1040 APP_cameraBlockedFrontNarrow 1;
BA_ "Confidence" SG_ 1040 APP_cameraBlockedLeftPillar 1;
BA_ "Confidence" SG_ 1040 APP_cameraBlockedLeftRepeater 1;
BA_ "Confidence" SG_ 1040 APP_cameraBlockedRightPillar 1;
BA_ "Confidence" SG_ 1040 APP_cameraBlockedRightRepeater 1;
BA_ "Confidence" SG_ 1040 APP_cameraBlockedBackup 1;
BA_ "Confidence" SG_ 1040 APP_fasciaCameraTemperature 1;
BA_ "Confidence" SG_ 1043 APP_mainDashCamFeedGood 1;
BA_ "Confidence" SG_ 1043 APP_mainDashCamFrameRate 1;
BA_ "Confidence" SG_ 1043 APP_lRepeatDashCamFeedGood 1;
BA_ "Confidence" SG_ 1043 APP_lRepeatDashCamFrameRate 1;
BA_ "Confidence" SG_ 1043 APP_rRepeatDashCamFeedGood 1;
BA_ "Confidence" SG_ 1043 APP_rRepeatDashCamFrameRate 1;
BA_ "Confidence" SG_ 2045 APP_cameraDefogMode 1;
BA_ "Confidence" SG_ 2045 APP_selfieCamFanRpm 1;
BA_ "Confidence" SG_ 2045 APP_forceDefroster 1;
BA_ "Confidence" SG_ 2045 APP_checkThermalSysHealth 1;
BA_ "Confidence" SG_ 2045 APP_hvacRequest 1;
BA_ "Confidence" SG_ 939 APP_attnMonitorVersion 1;
BA_ "Confidence" SG_ 939 APP_attnBasedDriverMonitorOn 1;
BA_ "Confidence" SG_ 939 APP_handsOnDetected 1;
BA_ "Confidence" SG_ 939 APP_handsOnDetectedSource 1;
BA_ "Confidence" SG_ 939 APP_cabinCamBlinded 1;
BA_ "Confidence" SG_ 939 APP_cabinCamDark 1;
BA_ "Confidence" SG_ 939 APP_driverStateUnknown 1;
BA_ "Confidence" SG_ 939 APP_driverNotLively 1;
BA_ "Confidence" SG_ 939 APP_driverStateUnknownHyst 1;
BA_ "Confidence" SG_ 939 APP_driverLowNominal 1;
BA_ "Confidence" SG_ 939 APP_driverHeadCappedHyst 1;
BA_ "Confidence" SG_ 939 APP_driverSunglassesUseHyst 1;
BA_ "Confidence" SG_ 939 APP_cabinLowLux 1;
BA_ "Confidence" SG_ 939 APP_cabinCamInconsistent 1;
BA_ "Confidence" SG_ 939 APP_driverLeaningBack 1;
BA_ "Confidence" SG_ 939 APP_driverLowEyeVisibility 1;
BA_ "Confidence" SG_ 939 APP_driverHandsNotReady 1;
BA_ "Confidence" SG_ 939 APP_driverSeatUnoccupied 1;
BA_ "Confidence" SG_ 939 APP_handsOnInputRequired 1;
BA_ "Confidence" SG_ 939 APP_cabinCamDarkHyst 1;
BA_ "Confidence" SG_ 939 APP_cabinLowLuxHyst 1;
BA_ "Confidence" SG_ 939 APP_ADDWSystemStatus 1;
BA_ "Confidence" SG_ 939 APP_dmStrictness 1;
BA_ "Confidence" SG_ 939 APP_dmStrictnessReason 1;
BA_ "Confidence" SG_ 603 APP_offgassingSeverity 1;
BA_ "Confidence" SG_ 603 APP_offgassingDetectionState 1;
BA_ "Confidence" SG_ 603 APP_offgassingMaxProbabilityLong 1;
BA_ "Confidence" SG_ 603 APP_offgassingMaxProbabilityShor 1;
BA_ "SystemSignalLongSymbol" SG_ 603 APP_offgassingMaxProbabilityShor "APP_offgassingMaxProbabilityShort";
BA_ "Confidence" SG_ 603 APP_offgassingLongMaxCamera 1;
BA_ "Confidence" SG_ 603 APP_offgassingShortMaxCamera 1;
BA_ "Confidence" SG_ 603 APP_offgassingLongMaxDetector 1;
BA_ "Confidence" SG_ 603 APP_offgassingShortMaxDetector 1;
BA_ "Confidence" SG_ 1061 APP_factoryGoalLatitude 1;
BA_ "Confidence" SG_ 1061 APP_factoryGoalLongitude 1;
BA_ "Confidence" SG_ 1061 APP_factoryGoalSpeed 1;
BA_ "Confidence" SG_ 843 APP_frontLeftParkAssist 1;
BA_ "Confidence" SG_ 843 APP_frontLeftMiddleParkAssist 1;
BA_ "Confidence" SG_ 843 APP_frontMiddleParkAssist 1;
BA_ "Confidence" SG_ 843 APP_frontRightMiddleParkAssist 1;
BA_ "Confidence" SG_ 843 APP_frontRightParkAssist 1;
BA_ "Confidence" SG_ 843 APP_parkAssistStatus 1;
BA_ "Confidence" SG_ 1353 APP_buildType 1;
BA_ "Confidence" SG_ 907 APP_rearLeftParkAssist 1;
BA_ "Confidence" SG_ 907 APP_rearLeftMiddleParkAssist 1;
BA_ "Confidence" SG_ 907 APP_rearMiddleParkAssist 1;
BA_ "Confidence" SG_ 907 APP_rearRightMiddleParkAssist 1;
BA_ "Confidence" SG_ 907 APP_rearRightParkAssist 1;
BA_ "Confidence" SG_ 601 APP_watchdogState 1;
BA_ "Confidence" SG_ 601 APP_fusedState 1;
BA_ "Confidence" SG_ 601 APP_cameraHeaterRequest 1;
BA_ "Confidence" SG_ 601 APP_factorySummonStatus 1;
BA_ "Confidence" SG_ 601 APP_clipRecordingStatus 1;
BA_ "Confidence" SG_ 601 APP_allowApActivationWithBrake 1;
BA_ "Confidence" SG_ 601 APP_summonUnavailableReason 1;
BA_ "Confidence" SG_ 601 APP_fsdSuspendState 1;
BA_ "Confidence" SG_ 601 APP_fsdRevokeStrikeoutCount 1;
BA_ "Confidence" SG_ 601 APP_teslaVisionSupported 1;
BA_ "Confidence" SG_ 601 APP_teslaVisionUnsupportedReason 1;
BA_ "Confidence" SG_ 601 APP_fsdRevokeCount 1;
BA_ "Confidence" SG_ 601 APP_excessiveAccelPedalWarning 1;
BA_ "Confidence" SG_ 601 APP_unifiedObjectStackSupported 1;
BA_ "Confidence" SG_ 601 APP_sendingBUCStream 1;
BA_ "Confidence" SG_ 601 APP_DDAWSystemStatus 1;
BA_ "Confidence" SG_ 601 APP_socOperatingMode 1;
BA_ "Confidence" SG_ 601 APP_summonVersionIdentifier 1;
BA_ "Confidence" SG_ 601 APP_sentryState 1;
BA_ "Confidence" SG_ 601 APP_autoparkVersionIdentifier 1;
BA_ "Confidence" SG_ 601 APP_autonomySystemHealth 1;
BA_ "Confidence" SG_ 605 APP_tcFeatureState 1;
BA_ "Confidence" SG_ 605 APP_tcStateMachine 1;
BA_ "Confidence" SG_ 605 APP_tcControlSource 1;
BA_ "Confidence" SG_ 605 APP_tcControlType 1;
BA_ "Confidence" SG_ 605 APP_tcControlDistance 1;
BA_ "Confidence" SG_ 605 APP_tcControlLightState 1;
BA_ "Confidence" SG_ 605 APP_tcContinuationReason 1;
BA_ "Confidence" SG_ 605 APP_tcConfirmationType 1;
BA_ "Confidence" SG_ 605 APP_tcWarningSuppressionReason 1;
BA_ "Confidence" SG_ 605 APP_tcUnavailableReason 1;
BA_ "Confidence" SG_ 605 APP_tcVisionLight 1;
BA_ "Confidence" SG_ 605 APP_tcVisionSign 1;
BA_ "Confidence" SG_ 605 APP_tcVisionRoadMarking 1;
BA_ "Confidence" SG_ 605 APP_tcVisionLine 1;
BA_ "Confidence" SG_ 859 APP_visionOcsStateRaw 1;
BA_ "Confidence" SG_ 859 APP_visionOcsEmptyProbRaw 1;
BA_ "Confidence" SG_ 859 APP_visionOcsChildProbRaw 1;
BA_ "Confidence" SG_ 859 APP_visionOcsAdultProbRaw 1;
BA_ "Confidence" SG_ 859 APP_visionOcsFrontPasClsVisionSt 1;
BA_ "SystemSignalLongSymbol" SG_ 859 APP_visionOcsFrontPasClsVisionSt "APP_visionOcsFrontPasClsVisionStateFlt";
VAL_ 1020 APP_pascalHeaterDecision 1 "ON" 0 "OFF" ;
VAL_ 2045 APP_cameraDefogMode 11 "CAMERA_DEFOG_DISABLE_START_FSD_BUTTON_NOT_ENABLED" 10 "CAMERA_DEFOG_DISABLE_NO_MIN_STANDBY_POWER" 9 "CAMERA_DEFOG_DISABLE_UNKNOWN" 8 "CAMERA_DEFOG_DISABLE_VEHICLE_NOT_DELIVERED" 7 "CAMERA_DEFOG_DISABLE_BAD_HW" 6 "CAMERA_DEFOG_DISABLE_FEATURE_FLAG_NOT_ENABLED" 5 "CAMERA_DEFOG_DISABLE_NOT_FSD_CAR" 4 "CAMERA_DEFOG_DISABLE_INDOORS" 3 "CAMERA_DEFOG_DISABLE_UI_FSD_NOT_ENABLED" 2 "CAMERA_DEFOG_DISABLE_LOW_SOC" 1 "CAMERA_DEFOG_ENABLE" 0 "CAMERA_DEFOG_SNA" ;
VAL_ 2045 APP_forceDefroster 3 "DEFROSTER_DEFROST" 2 "DEFROSTER_DEFOG" 1 "DEFROSTER_NONE" 0 "DEFROSTER_SNA" ;
VAL_ 2045 APP_checkThermalSysHealth 2 "EVAL_THERMAL" 1 "EVAL_NONE" 0 "EVAL_SNA" ;
VAL_ 2045 APP_hvacRequest 2 "ACTIVE" 1 "INACTIVE" ;
VAL_ 939 APP_attnMonitorVersion 1 "V1_1" 0 "V1_0" ;
VAL_ 939 APP_handsOnDetectedSource 3 "TORQUE_IGNORE_SELFIE_FOR_CAVEAT" 2 "TORQUE_AND_SELFIE" 1 "SELFIE" 0 "TORQUE" ;
VAL_ 939 APP_ADDWSystemStatus 3 "FAULTED" 2 "WARN" 1 "ACTIVE" 0 "INACTIVE" ;
VAL_ 939 APP_dmStrictness 3 "HIGH" 2 "MED" 1 "LOW" ;
VAL_ 939 APP_dmStrictnessReason 45 "UPCOMING_INTERSECTION" 44 "ON_HIGHWAY_CIPV_PRESENT" 43 "FAILSAFES_ACTIVE" 42 "LOW_SPEED_CIPV_PRESENT" 41 "RANKER_ACTIVATION" 40 "SPEED_BELOW_LOW_THRESHOLD_ON_CITY" 39 "UPCOMING_LATERAL_MANEUVER" 38 "WAITING_FOR_TRAFFIC_LIGHT" 37 "HIGH_LATERAL_ACCELERATION" 36 "DRIVER_FATIGUE_DETECTED" 35 "ON_INTERCHANGE" 34 "ON_RAMP" 33 "PERSISTED_OFFGASSING" 32 "AUTOHEADLIGHT_OFF" 31 "AUTOWIPER_OFF" 30 "CONSTRUCTION" 29 "ONCOMING_TRAFFIC_PRESENT" 28 "MED_STRICTNESS_SCENE_TAG_ACTIVE" 27 "REFERENCE_LATERAL_ERROR_WARNING" 26 "STEERING_ANGLE_OVER_THRESHOLD" 25 "SPEED_OVER_HIGH_THRESHOLD" 24 "SIDE_CAMERA_OCCLUSION" 23 "FSD_DEGRADED" 22 "INCLEMENT_WEATHER" 21 "SEVERE_RIGHT_VISION_OCCLUSION_REVERSE" 20 "SEVERE_LEFT_VISION_OCCLUSION_REVERSE" 19 "SEVERE_BACKUP_VISION_OCCLUSION_REVERSE" 18 "SEVERE_RIGHT_VISION_OCCLUSION_MANEUVER" 17 "SEVERE_LEFT_VISION_OCCLUSION_MANEUVER" 16 "SEVERE_SINGLE_FRONT_VISION_OCCLUSION" 15 "ESV_DETECTED" 14 "VRU_IN_DRIVABLE_SPACE" 13 "TOLLBOOTH" 12 "CAUTION_LIGHTS" 11 "ADVERSE_ROAD_CONDITIONS" 10 "HEAD_DOWN" 9 "HIGH_STRICTNESS_REQUIRED_FOR_DISTRACTION" 8 "PEDAL_OVERRIDE" 7 "HIGH_ACCEL_OR_DECEL" 6 "HIGH_STRICTNESS_DEV_CTRL" 5 "VISIBILITY_DEGRADED_OFFGASSING" 4 "FOLLOWING_CIPV_HIGH_DECEL" 3 "TRAFFIC_CONTROL_CONTEXT_RAILROAD" 2 "INCREASED_STRICTNESS_FOR_NON_REDUNDANT_EPAS" 1 "VISION_FAILSAFES_OVERRIDE_ACTIVE" ;
VAL_ 603 APP_offgassingSeverity 4 "APP_OFFGASSING_SEVERITY_HIGH_SEVERITY" 3 "APP_OFFGASSING_SEVERITY_MEDIUM_SEVERITY" 2 "APP_OFFGASSING_SEVERITY_LESS_SEVERITY" 1 "APP_OFFGASSING_SEVERITY_CLEAR" 0 "APP_OFFGASSING_SEVERITY_SNA" ;
VAL_ 603 APP_offgassingDetectionState 2 "APP_OFFGASSING_DETECTION_ACTIVE" 1 "APP_OFFGASSING_DETECTION_SKIPPED" 0 "APP_OFFGASSING_DETECTION_SNA" ;
VAL_ 603 APP_offgassingMaxProbabilityLong 12 "APP_OFFGASSING_DETECTION_PERCENT_16_PLUS" 11 "APP_OFFGASSING_DETECTION_PERCENT_16" 10 "APP_OFFGASSING_DETECTION_PERCENT_8" 9 "APP_OFFGASSING_DETECTION_PERCENT_4" 8 "APP_OFFGASSING_DETECTION_PERCENT_3" 7 "APP_OFFGASSING_DETECTION_PERCENT_2" 6 "APP_OFFGASSING_DETECTION_PERCENT_1_5" 5 "APP_OFFGASSING_DETECTION_PERCENT_1" 4 "APP_OFFGASSING_DETECTION_PERCENT_0_75" 3 "APP_OFFGASSING_DETECTION_PERCENT_0_5" 2 "APP_OFFGASSING_DETECTION_PERCENT_0_25" 1 "APP_OFFGASSING_DETECTION_PERCENT_0" 0 "APP_OFFGASSING_DETECTION_PERCENT_SNA" ;
VAL_ 603 APP_offgassingMaxProbabilityShor 12 "APP_OFFGASSING_DETECTION_PERCENT_16_PLUS" 11 "APP_OFFGASSING_DETECTION_PERCENT_16" 10 "APP_OFFGASSING_DETECTION_PERCENT_8" 9 "APP_OFFGASSING_DETECTION_PERCENT_4" 8 "APP_OFFGASSING_DETECTION_PERCENT_3" 7 "APP_OFFGASSING_DETECTION_PERCENT_2" 6 "APP_OFFGASSING_DETECTION_PERCENT_1_5" 5 "APP_OFFGASSING_DETECTION_PERCENT_1" 4 "APP_OFFGASSING_DETECTION_PERCENT_0_75" 3 "APP_OFFGASSING_DETECTION_PERCENT_0_5" 2 "APP_OFFGASSING_DETECTION_PERCENT_0_25" 1 "APP_OFFGASSING_DETECTION_PERCENT_0" 0 "APP_OFFGASSING_DETECTION_PERCENT_SNA" ;
VAL_ 603 APP_offgassingLongMaxCamera 3 "FISHEYE" 2 "NARROW" 1 "MAIN" ;
VAL_ 603 APP_offgassingShortMaxCamera 3 "FISHEYE" 2 "NARROW" 1 "MAIN" ;
VAL_ 603 APP_offgassingLongMaxDetector 2 "TRAFFIC_LIGHT" 1 "VEHICLE" ;
VAL_ 603 APP_offgassingShortMaxDetector 2 "TRAFFIC_LIGHT" 1 "VEHICLE" ;
VAL_ 843 APP_parkAssistStatus 2 "TEMPORARY_FAILURE" 1 "ENABLED" 0 "DISABLED" ;
VAL_ 1353 APP_buildType 3 "AP_BUILDTYPE_REPO" 1 "AP_BUILDTYPE_LOCAL" 0 "AP_BUILDTYPE_SIGNED" ;
VAL_ 601 APP_watchdogState 7 "AP_WDOG_STATE_SNA" 4 "AP_WDOG_STATE_SHUTTING_DOWN" 3 "AP_WDOG_STATE_HEALTHY" 2 "AP_WDOG_STATE_CRITICAL" 1 "AP_WDOG_STATE_DEGRADED" 0 "AP_WDOG_STATE_UNKNOWN" ;
VAL_ 601 APP_fusedState 3 "APP_FUSE_SNA" 2 "APP_FUSE_FUSED" 1 "APP_FUSE_UNFUSED" 0 "APP_FUSE_UNKNOWN" ;
VAL_ 601 APP_factorySummonStatus 8 "FACTORY_SUMMON_END_OF_ROUTE" 7 "FACTORY_SUMMON_UNAVAILABLE_HEADING_NOT_INITIALIZED" 6 "FACTORY_SUMMON_UNAVAILABLE_VEHICLE_SPEED_INVALID" 5 "FACTORY_SUMMON_UNAVAILABLE_NO_GPS" 4 "FACTORY_SUMMON_UNAVAILABLE_GOAL_TOO_FAR" 3 "FACTORY_SUMMON_UNAVAILABLE_NO_QR_INSTRUCTION" 2 "FACTORY_SUMMON_AVAILABLE" 1 "FACTORY_SUMMON_ACTIVE" 0 "FACTORY_SUMMON_SNA" ;
VAL_ 601 APP_clipRecordingStatus 4 "APP_CLIP_FAULTED" 3 "APP_CLIP_TRIGGERED" 2 "APP_CLIP_RECORDING" 1 "APP_CLIP_IDLE" 0 "APP_CLIP_NO_DRIVE" ;
VAL_ 601 APP_summonUnavailableReason 28 "SMART_SUMMON_UNAVAILABLE_OUTSIDE_GEOFENCE" 27 "SMART_SUMMON_UNAVAILABLE_ACCEL_PEDAL_PRESSED" 26 "SMART_SUMMON_UNAVAILABLE_BRAKE_PEDAL_PRESSED" 25 "SMART_SUMMON_UNAVAILABLE_REMOTE_STOP_OR_ABORT_REQUEST_ACTIVE" 24 "SMART_SUMMON_UNAVAILABLE_CLOSURE_OPEN" 23 "SMART_SUMMON_UNAVAILABLE_LOW_TIRE_PRESSURE" 22 "SMART_SUMMON_UNAVAILABLE_EXTENDED_COMPUTE_INACTIVE" 21 "SMART_SUMMON_UNAVAILABLE_HIGH_GRADE" 20 "SMART_SUMMON_UNAVAILABLE_NO_CONTEXT" 19 "SMART_SUMMON_UNAVAILABLE_PUBLIC_ROAD_BOUNDARIES_NOT_VALID" 18 "SMART_SUMMON_UNAVAILABLE_ALL_SENSORS_OCCLUDED" 17 "SMART_SUMMON_UNAVAILABLE_ULTRASONIC_STALE" 16 "SMART_SUMMON_UNAVAILABLE_VISION_HEALTH_CRITICAL" 15 "SMART_SUMMON_UNAVAILABLE_CAMERA_NOT_CALIBRATED" 14 "SMART_SUMMON_UNAVAILABLE_END_OF_LEASH" 13 "SMART_SUMMON_UNAVAILABLE_PHONE_IS_TOO_FAR" 12 "SMART_SUMMON_UNAVAILABLE_EGO_GPS_UNAVAILABLE" 11 "SMART_SUMMON_UNAVAILABLE_PHONE_GPS_UNAVAILABLE" 10 "SMART_SUMMON_UNAVAILABLE_POOR_CONNECTION" 9 "SMART_SUMMON_UNAVAILABLE_PUBLIC_ROAD" 8 "SMART_SUMMON_UNAVAILABLE_EAC_UNAVAILABLE" 7 "SMART_SUMMON_UNAVAILABLE_CRUISE_UNAVAILABLE" 6 "SMART_SUMMON_UNAVAILABLE_ULTRASONIC_FAULT" 5 "SMART_SUMMON_UNAVAILABLE_ULTRASONIC_BLOCKED" 4 "SMART_SUMMON_UNAVAILABLE_CAMERA_BLOCKED" 3 "SMART_SUMMON_UNAVAILABLE_CAMERA_STREAM" 2 "SMART_SUMMON_UNAVAILABLE_NOT_IN_PARK" 1 "SMART_SUMMON_UNAVAILABLE_NONE" 0 "SMART_SUMMON_UNAVAILABLE_UNKNOWN" ;
VAL_ 601 APP_fsdSuspendState 1 "SUSPENDED" 0 "NOT_SUSPENDED" ;
VAL_ 601 APP_teslaVisionSupported 1 "SUPPORTED" 0 "NOT_SUPPORTED" ;
VAL_ 601 APP_teslaVisionUnsupportedReason 4 "VEHICLE_LOCATION" 3 "UNSUPPORTED_CAMERA" 2 "AP_HARDWARE" 1 "NONE" 0 "UNKNOWN" ;
VAL_ 601 APP_unifiedObjectStackSupported 1 "SUPPORTED" 0 "NOT_SUPPORTED" ;
VAL_ 601 APP_DDAWSystemStatus 4 "DDAW_SYSTEM_SNA" 3 "DDAW_SYSTEM_INVALID" 2 "DDAW_SYSTEM_FAILURE" 1 "DDAW_SYSTEM_DRIVER_DROWSY" 0 "DDAW_SYSTEM_NOMINAL" ;
VAL_ 601 APP_socOperatingMode 2 "AP_DUAL_SOC" 1 "AP_SINGLE_SOC" 0 "AP_UNKNOWN" ;
VAL_ 601 APP_summonVersionIdentifier 2 "AUTONOMY_SUMMON" 1 "ACTUALLY_SMART_SUMMON" 0 "LEGACY_SMART_SUMMON" ;
VAL_ 601 APP_sentryState 6 "SENTRY_SNA" 5 "SENTRY_QUIET" 4 "SENTRY_PANIC" 3 "SENTRY_AWARE" 2 "SENTRY_ARMED" 1 "SENTRY_IDLE" 0 "SENTRY_OFF" ;
VAL_ 601 APP_autoparkVersionIdentifier 2 "ACTUALLY_SMART_AUTOPARK" 1 "V3_VISION_AUTOPARK" 0 "LEGACY_AUTOPARK" ;
VAL_ 601 APP_autonomySystemHealth 1 "AUTONOMY_SYSTEM_HEALTH_HEALTHY" 0 "AUTONOMY_SYSTEM_HEALTH_UNHEALTHY" ;
VAL_ 605 APP_tcFeatureState 3 "TC_ACTIVE" 2 "TC_AVAILABLE" 1 "TC_UNAVAILABLE" 0 "TC_DISABLED" ;
VAL_ 605 APP_tcStateMachine 6 "TCSM_CONTINUING" 5 "TCSM_STOPPED" 4 "TCSM_STOPPING" 3 "TCSM_WARNING" 2 "TCSM_AWARE" 1 "TCSM_STANDBY" 0 "TCSM_DISABLED" ;
VAL_ 605 APP_tcControlSource 3 "TC_SOURCE_MAP_AND_VISION" 2 "TC_SOURCE_VISION" 1 "TC_SOURCE_MAP" 0 "TC_SOURCE_NONE" ;
VAL_ 605 APP_tcControlType 22 "TC_TYPE_T_ARM" 21 "TC_TYPE_BEV_JUNCTION" 20 "TC_TYPE_T_IMPLICIT_BY_GEOM" 19 "TC_TYPE_T_IMPLICIT_BY_NAME" 18 "TC_TYPE_T_IMPLICIT" 17 "TC_TYPE_NO_STOP" 16 "TC_TYPE_BIKE_MERGE_FROM_RIGHT" 15 "TC_TYPE_BIKE_MERGE_FROM_LEFT" 14 "TC_TYPE_ALL_WAY_STOP_SIGN" 13 "TC_TYPE_TRAFFIC_RULE" 12 "TC_TYPE_SPEED_HUMP" 11 "TC_TYPE_SPEED_BUMP" 10 "TC_TYPE_RAMP_METER" 9 "TC_TYPE_PEDESTRIAN_CROSSING" 8 "TC_TYPE_SUICIDE_LEFT" 7 "TC_TYPE_KEEP_CLEAR_EXIT" 6 "TC_TYPE_KEEP_CLEAR_ENTER" 5 "TC_TYPE_CROSSWALK" 4 "TC_TYPE_YIELD" 3 "TC_TYPE_TRAFFIC_LIGHT" 2 "TC_TYPE_STOP_SIGN" 1 "TC_TYPE_UNKNOWN" 0 "TC_TYPE_INVALID" ;
VAL_ 605 APP_tcControlLightState 6 "TC_LIGHTSTATE_OTHER" 5 "TC_LIGHTSTAET_WHITE" 4 "TC_LIGHTSTATE_OFF" 3 "TC_LIGHTSTATE_YELLOW" 2 "TC_LIGHTSTATE_GREEN" 1 "TC_LIGHTSTATE_RED" 0 "TC_LIGHTSTATE_NONE" ;
VAL_ 605 APP_tcContinuationReason 13 "TC_CONTINUE_CONTROL_UNAVAILABLE" 12 "TC_CONTINUE_SUMMON_TIMEOUT" 11 "TC_CONTINUE_CLEAR_TO_GO" 10 "TC_CONTINUE_WARNING_TIMEOUT" 9 "TC_CONTINUE_INVALID_MAP_OR_VISION_CONTROL" 8 "TC_CONTINUE_PASSED_STOP" 7 "TC_CONTINUE_ASSUMED_DRIVER_STOPPED" 6 "TC_CONTINUE_AP_ACTIVATED_ON_HARD_STOP" 5 "TC_CONTINUE_VISION_SIGNALS" 4 "TC_CONTINUE_REQUIRED_DECEL_TOO_HIGH" 3 "TC_CONTINUE_USER_INPUT_ON_RED" 2 "TC_CONTINUE_USER_INPUT_ON_GREEN" 1 "TC_CONTINUE_GREEN_LIGHT_WITH_CIPV" 0 "TC_CONTINUE_NONE" ;
VAL_ 605 APP_tcConfirmationType 2 "TC_CONFIRM_PEDAL" 1 "TC_CONFIRM_STALK" 0 "TC_CONFIRM_NONE" ;
VAL_ 605 APP_tcWarningSuppressionReason 18 "TC_WARNING_SUPPRESS_TOO_FAR_FROM_PREDICTED_JUNCTION" 17 "TC_WARNING_SUPPRESS_NOT_SUPPORTED_BY_MEASUREMENTS" 16 "TC_WARNING_SUPPRESS_NO_ASSOCIATED_VISION_LINE" 15 "TC_WARNING_SUPPRESS_AMBIGUOUS_VISION_TYPE" 14 "TC_WARNING_SUPPRESS_CIPV_DID_NOT_STOP" 13 "TC_WARNING_SUPPRESS_STALE_SIGN_DETECTION" 12 "TC_WARNING_SUPPRESS_WRONG_MAP_TYPE" 11 "TC_WARNING_SUPPRESS_LIGHT_UNASSOCIATED" 10 "TC_WARNING_SUPPRESS_CIPV_CONTINUING" 9 "TC_WARNING_SUPPRESS_PEDAL_OVERRIDE" 8 "TC_WARNING_SUPPRESS_LOCALIZATION_DEGRADED" 7 "TC_WARNING_SUPPRESS_HARD_TURN" 6 "TC_WARNING_SUPPRESS_ASSUMED_YELLOW" 5 "TC_WARNING_SUPPRESS_DRIVER_SLOWING_DOWN" 4 "TC_WARNING_SUPPRESS_BELOW_MIN_SPEED" 3 "TC_WARNING_SUPPRESS_SLOWDOWN_PLANNED" 2 "TC_WARNING_SUPPRESS_INSUFFICIENT_DATA" 1 "TC_WARNING_SUPPRESS_FEATURE_DISABLED" 0 "TC_WARNING_SUPPRESS_NONE" ;
VAL_ 605 APP_tcUnavailableReason 9 "AP_UNAVAILBLE_SUN_GLARE_ON_ROAD_RESTRICTED" 8 "AP_UNAVAILBLE_CAMERA_BLINDED_ON_ROAD_RESTRICTED" 7 "AP_UNAVAILBLE_GPS_DEGRADED" 6 "AP_UNAVAILBLE_ROAD_ESTIMATOR_UNHEALTHY" 5 "AP_UNAVAILBLE_SUN_GLARE" 4 "AP_UNAVAILBLE_CAMERA_BLINDED" 3 "AP_UNAVAILBLE_ROAD_CLASS" 2 "AP_UNAVAILBLE_LOST_MAP_LOCALIZATION" 1 "AP_UNAVAILBLE_MCU_DISABLED" 0 "AP_UNAVAILBLE_NONE" ;
VAL_ 859 APP_visionOcsStateRaw 3 "ADULT" 2 "CHILD" 1 "EMPTY" 0 "UNKNOWN" ;
VAL_ 859 APP_visionOcsFrontPasClsVisionSt 3 "ADULT" 2 "CHILD" 1 "EMPTY" 0 "UNKNOWN" ;
